VERSION ""

NS_ :

BS_:

BU_: WCM4 WCM3 WCM2 WCM VPM VLM VKM VICM VECM VDM VCU_RTOS_ETH VCU_ENTRY_ETH VCU_AGVM_ETH VCU UVM UPM TIM TEST_TOOL_1 TCP_ETH TCP TCM TCCM SRR_SRR_ETH SRR_SRR SRR_SLR_ETH SRR_SLR SRR_RR SRR_RF_ETH SRR_RF SRR_LR_CR SRR_LF_ETH SRR_LF SIB SDM SCL SBZA_R SBZA_L SBM SAM_RR SAM_RF SAM_LR SAM_LF SAM_BH SADS RadioLow_ETH RadioLow RSI_RTOS_ETH RSI RDCM PTM PLCM PFCM PDR_ETH PDR PCM PA ODS2 ODS NVM MTCM_R MTCM_L MSM_RR MSM_P MSM_LR MSM_D MSB2 MSB1 MRCM_R MRCM_L MFC LRR_RR_ETH LRR_LR_ETH LRR_CF_ETH LRR LRL_CF_ETH LIB_48V LIB1 IPC_INT IPC_GP IPC ICS_Info ICCM HVAC_FP_R HVAC_FP_F HUD_CAN HDLM FPI_RTOS_ETH FPI FOPM FCM_LC FCM EPSb EPS_1 EPSRAb EPSRAa EPS EOCM_HC_Superset EOCM_HCP2 EOCM ELM ECP_X1 ECP_S2 ECP_S ECP_MC ECP_H3 ECP_H2 ECP_H1 ECP_E ECM EBCM DMS DEFC DCM CSM_ETH CSM_AV CSM CGM_OTA_ETH CGM BSM_MH BSM_HEV BSM BCM ARS ARB APA AOS AMP ALC AHS AHL_AFL ADIMb ADIMa ACP2_MCU

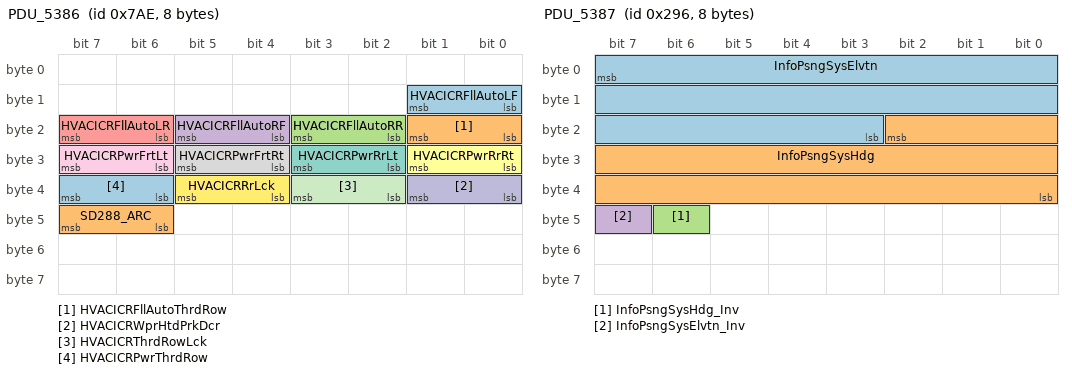
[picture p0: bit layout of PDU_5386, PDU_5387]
BO_ 1966 PDU_5386: 8 VCU
 SG_ HVACICRFllAutoLF : 9|2@0+ (1,0) [0|2] "" Vector__XXX
 SG_ HVACICRFllAutoThrdRow : 17|2@0+ (1,0) [0|2] "" Vector__XXX
 SG_ HVACICRFllAutoRR : 19|2@0+ (1,0) [0|2] "" Vector__XXX
 SG_ HVACICRFllAutoRF : 21|2@0+ (1,0) [0|2] "" Vector__XXX
 SG_ HVACICRFllAutoLR : 23|2@0+ (1,0) [0|2] "" Vector__XXX
 SG_ HVACICRPwrRrRt : 25|2@0+ (1,0) [0|2] "" Vector__XXX
 SG_ HVACICRPwrRrLt : 27|2@0+ (1,0) [0|2] "" Vector__XXX
 SG_ HVACICRPwrFrtRt : 29|2@0+ (1,0) [0|2] "" Vector__XXX
 SG_ HVACICRPwrFrtLt : 31|2@0+ (1,0) [0|2] "" Vector__XXX
 SG_ HVACICRWprHtdPrkDcr : 33|2@0+ (1,0) [0|2] "" Vector__XXX
 SG_ HVACICRThrdRowLck : 35|2@0+ (1,0) [0|2] "" Vector__XXX
 SG_ HVACICRRrLck : 37|2@0+ (1,0) [0|2] "" Vector__XXX
 SG_ HVACICRPwrThrdRow : 39|2@0+ (1,0) [0|2] "" Vector__XXX
 SG_ SD288_ARC : 47|2@0+ (1,0) [0|3] "" Vector__XXX

BO_ 662 PDU_5387: 8 VCU
 SG_ InfoPsngSysElvtn : 7|21@0+ (1,-100000) [-100000|1.99715e+006] "cm" Vector__XXX
 SG_ InfoPsngSysHdg : 18|19@0+ (0.001,0) [0|524.287] "deg" Vector__XXX
 SG_ InfoPsngSysHdg_Inv : 46|1@0+ (1,0) [0|1] "" Vector__XXX
 SG_ InfoPsngSysElvtn_Inv : 47|1@0+ (1,0) [0|1] "" Vector__XXX

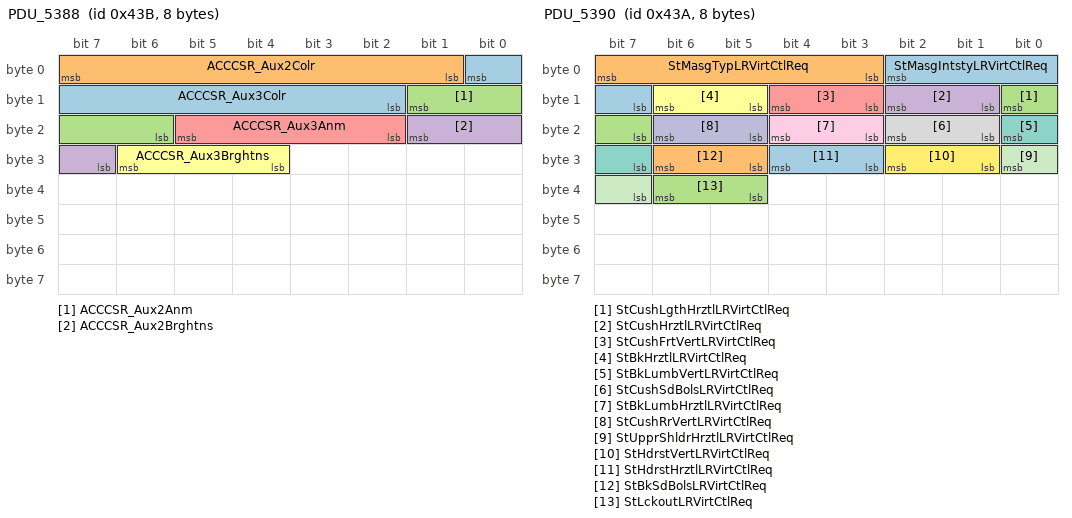
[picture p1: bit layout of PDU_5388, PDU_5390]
BO_ 1083 PDU_5388: 8 VCU
 SG_ ACCCSR_Aux3Colr : 0|7@0+ (1,0) [0|127] "" Vector__XXX
 SG_ ACCCSR_Aux2Colr : 7|7@0+ (1,0) [0|127] "" Vector__XXX
 SG_ ACCCSR_Aux2Anm : 9|4@0+ (1,0) [0|15] "" Vector__XXX
 SG_ ACCCSR_Aux2Brghtns : 17|3@0+ (1,0) [0|4] "" Vector__XXX
 SG_ ACCCSR_Aux3Anm : 21|4@0+ (1,0) [0|15] "" Vector__XXX
 SG_ ACCCSR_Aux3Brghtns : 30|3@0+ (1,0) [0|4] "" Vector__XXX

BO_ 1965 PDU_5389: 8 VCU
 SG_ StMasgTypLFVirtCtlReq : 1|5@0+ (1,0) [0|16] "" Vector__XXX
 SG_ StMemLFVirtCtlReq : 7|6@0+ (1,0) [0|33] "" Vector__XXX
 SG_ StBkHrztlLFCtlFrmFrtVirtCtlReq : 8|2@0+ (1,0) [0|2] "" Vector__XXX
 SG_ StMasgIntstyLFVirtCtlReq : 12|4@0+ (1,0) [0|8] "" Vector__XXX
 SG_ StBkLumbHrztlLFVirtCtlReq : 16|2@0+ (1,0) [0|2] "" Vector__XXX
 SG_ StCushHrztlLFCtlFrmFrtVirtCtlRq : 18|2@0+ (1,0) [0|2] "" Vector__XXX
 SG_ StCushFrtVertLFVirtCtlReq : 20|2@0+ (1,0) [0|2] "" Vector__XXX
 SG_ StBkHrztlLFCtlFrmRrVirtCtlReq : 22|2@0+ (1,0) [0|2] "" Vector__XXX
 SG_ StBkLumbVertLFVirtCtlReq : 24|2@0+ (1,0) [0|2] "" Vector__XXX
 SG_ StCushRrVertLFVirtCtlReq : 26|2@0+ (1,0) [0|2] "" Vector__XXX
 SG_ StCushLgthHrztlLFVirtCtlReq : 28|2@0+ (1,0) [0|2] "" Vector__XXX
 SG_ StCushHrztlLFCtlFrmRrVirtCtlReq : 30|2@0+ (1,0) [0|2] "" Vector__XXX
 SG_ StHdrstVertLFVirtCtlReq : 32|2@0+ (1,0) [0|2] "" Vector__XXX
 SG_ StHdrstHrztlLFVirtCtlReq : 34|2@0+ (1,0) [0|2] "" Vector__XXX
 SG_ StBkSdBolsLFVirtCtlReq : 36|2@0+ (1,0) [0|2] "" Vector__XXX
 SG_ StCushSdBolsLFVirtCtlReq : 38|2@0+ (1,0) [0|2] "" Vector__XXX
 SG_ StUpprShldrHrztlLFVirtCtlReq : 46|2@0+ (1,0) [0|2] "" Vector__XXX

BO_ 1082 PDU_5390: 8 VCU
 SG_ StMasgIntstyLRVirtCtlReq : 2|4@0+ (1,0) [0|8] "" Vector__XXX
 SG_ StMasgTypLRVirtCtlReq : 7|5@0+ (1,0) [0|16] "" Vector__XXX
 SG_ StCushLgthHrztlLRVirtCtlReq : 8|2@0+ (1,0) [0|2] "" Vector__XXX
 SG_ StCushHrztlLRVirtCtlReq : 10|2@0+ (1,0) [0|2] "" Vector__XXX
 SG_ StCushFrtVertLRVirtCtlReq : 12|2@0+ (1,0) [0|2] "" Vector__XXX
 SG_ StBkHrztlLRVirtCtlReq : 14|2@0+ (1,0) [0|2] "" Vector__XXX
 SG_ StBkLumbVertLRVirtCtlReq : 16|2@0+ (1,0) [0|2] "" Vector__XXX
 SG_ StCushSdBolsLRVirtCtlReq : 18|2@0+ (1,0) [0|2] "" Vector__XXX
 SG_ StBkLumbHrztlLRVirtCtlReq : 20|2@0+ (1,0) [0|2] "" Vector__XXX
 SG_ StCushRrVertLRVirtCtlReq : 22|2@0+ (1,0) [0|2] "" Vector__XXX
 SG_ StUpprShldrHrztlLRVirtCtlReq : 24|2@0+ (1,0) [0|2] "" Vector__XXX
 SG_ StHdrstVertLRVirtCtlReq : 26|2@0+ (1,0) [0|2] "" Vector__XXX
 SG_ StHdrstHrztlLRVirtCtlReq : 28|2@0+ (1,0) [0|2] "" Vector__XXX
 SG_ StBkSdBolsLRVirtCtlReq : 30|2@0+ (1,0) [0|2] "" Vector__XXX
 SG_ StLckoutLRVirtCtlReq : 38|2@0+ (1,0) [0|2] "" Vector__XXX

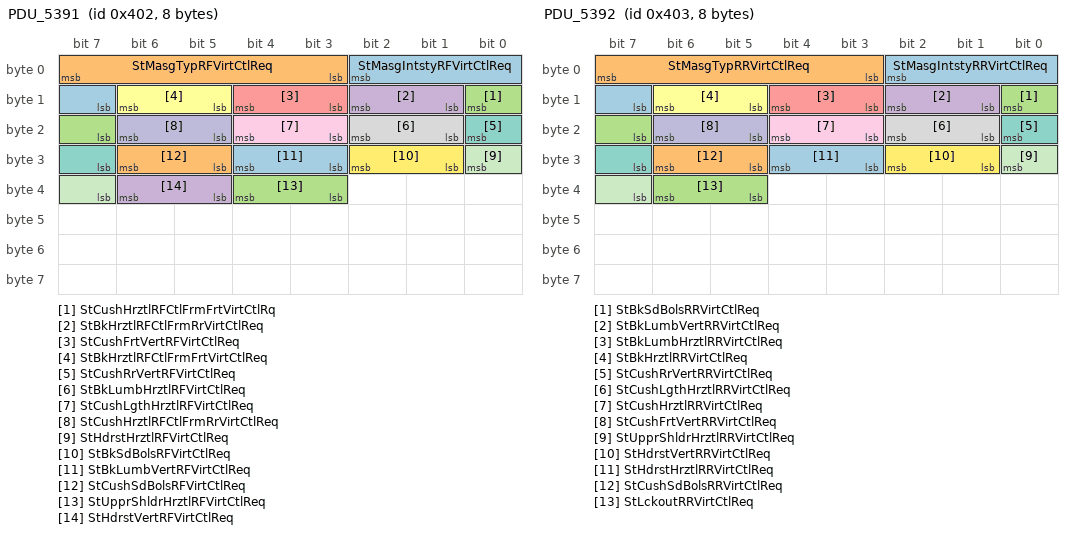
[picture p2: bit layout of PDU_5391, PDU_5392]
BO_ 1026 PDU_5391: 8 VCU
 SG_ StMasgIntstyRFVirtCtlReq : 2|4@0+ (1,0) [0|8] "" Vector__XXX
 SG_ StMasgTypRFVirtCtlReq : 7|5@0+ (1,0) [0|16] "" Vector__XXX
 SG_ StCushHrztlRFCtlFrmFrtVirtCtlRq : 8|2@0+ (1,0) [0|2] "" Vector__XXX
 SG_ StBkHrztlRFCtlFrmRrVirtCtlReq : 10|2@0+ (1,0) [0|2] "" Vector__XXX
 SG_ StCushFrtVertRFVirtCtlReq : 12|2@0+ (1,0) [0|2] "" Vector__XXX
 SG_ StBkHrztlRFCtlFrmFrtVirtCtlReq : 14|2@0+ (1,0) [0|2] "" Vector__XXX
 SG_ StCushRrVertRFVirtCtlReq : 16|2@0+ (1,0) [0|2] "" Vector__XXX
 SG_ StBkLumbHrztlRFVirtCtlReq : 18|2@0+ (1,0) [0|2] "" Vector__XXX
 SG_ StCushLgthHrztlRFVirtCtlReq : 20|2@0+ (1,0) [0|2] "" Vector__XXX
 SG_ StCushHrztlRFCtlFrmRrVirtCtlReq : 22|2@0+ (1,0) [0|2] "" Vector__XXX
 SG_ StHdrstHrztlRFVirtCtlReq : 24|2@0+ (1,0) [0|2] "" Vector__XXX
 SG_ StBkSdBolsRFVirtCtlReq : 26|2@0+ (1,0) [0|2] "" Vector__XXX
 SG_ StBkLumbVertRFVirtCtlReq : 28|2@0+ (1,0) [0|2] "" Vector__XXX
 SG_ StCushSdBolsRFVirtCtlReq : 30|2@0+ (1,0) [0|2] "" Vector__XXX
 SG_ StUpprShldrHrztlRFVirtCtlReq : 36|2@0+ (1,0) [0|2] "" Vector__XXX
 SG_ StHdrstVertRFVirtCtlReq : 38|2@0+ (1,0) [0|2] "" Vector__XXX

BO_ 1027 PDU_5392: 8 VCU
 SG_ StMasgIntstyRRVirtCtlReq : 2|4@0+ (1,0) [0|8] "" Vector__XXX
 SG_ StMasgTypRRVirtCtlReq : 7|5@0+ (1,0) [0|16] "" Vector__XXX
 SG_ StBkSdBolsRRVirtCtlReq : 8|2@0+ (1,0) [0|2] "" Vector__XXX
 SG_ StBkLumbVertRRVirtCtlReq : 10|2@0+ (1,0) [0|2] "" Vector__XXX
 SG_ StBkLumbHrztlRRVirtCtlReq : 12|2@0+ (1,0) [0|2] "" Vector__XXX
 SG_ StBkHrztlRRVirtCtlReq : 14|2@0+ (1,0) [0|2] "" Vector__XXX
 SG_ StCushRrVertRRVirtCtlReq : 16|2@0+ (1,0) [0|2] "" Vector__XXX
 SG_ StCushLgthHrztlRRVirtCtlReq : 18|2@0+ (1,0) [0|2] "" Vector__XXX
 SG_ StCushHrztlRRVirtCtlReq : 20|2@0+ (1,0) [0|2] "" Vector__XXX
 SG_ StCushFrtVertRRVirtCtlReq : 22|2@0+ (1,0) [0|2] "" Vector__XXX
 SG_ StUpprShldrHrztlRRVirtCtlReq : 24|2@0+ (1,0) [0|2] "" Vector__XXX
 SG_ StHdrstVertRRVirtCtlReq : 26|2@0+ (1,0) [0|2] "" Vector__XXX
 SG_ StHdrstHrztlRRVirtCtlReq : 28|2@0+ (1,0) [0|2] "" Vector__XXX
 SG_ StCushSdBolsRRVirtCtlReq : 30|2@0+ (1,0) [0|2] "" Vector__XXX
 SG_ StLckoutRRVirtCtlReq : 38|2@0+ (1,0) [0|2] "" Vector__XXX

BO_ 1085 PDU_5393: 8 VCU
 SG_ TrlrTirePresLFInrXferdSnsrID : 7|32@0+ (1,0) [0|4.29497e+009] "" Vector__XXX
 SG_ TrlrTirePresLRInrXferdSnsrID : 39|32@0+ (1,0) [0|4.29497e+009] "" Vector__XXX

BO_ 1982 PDU_5394: 8 VCU
 SG_ TrlrTirePresLtMdlInrXferdSnsrID : 7|32@0+ (1,0) [0|4.29497e+009] "" Vector__XXX
 SG_ TrlrTirePresRFInrXferdSnsrID : 39|32@0+ (1,0) [0|4.29497e+009] "" Vector__XXX

BO_ 1084 PDU_5395: 8 VCU
 SG_ TrlrTirePresRRInrXferdSnsrID : 7|32@0+ (1,0) [0|4.29497e+009] "" Vector__XXX
 SG_ TrlrTirePresRtMdlInrXferdSnsrID : 39|32@0+ (1,0) [0|4.29497e+009] "" Vector__XXX

BO_ 1983 PDU_5396: 8 VCU
 SG_ InfoUTCYr : 7|8@0+ (1,2000) [2000|2255] "year" Vector__XXX
 SG_ InfoUTCSec : 9|6@0+ (1,0) [0|63] "seconds" Vector__XXX
 SG_ InfoUTCMin : 15|6@0+ (1,0) [0|63] "minutes" Vector__XXX
 SG_ InfoUTCDay : 19|5@0+ (1,0) [0|31] "day" Vector__XXX
 SG_ InfoUTCMth : 25|4@0+ (1,0) [0|12] "" Vector__XXX
 SG_ InfoUTCHrs : 30|5@0+ (1,0) [0|31] "hour" Vector__XXX
 SG_ InfoUTCYr_Inv : 32|1@0+ (1,0) [0|1] "" Vector__XXX
 SG_ InfoUTCSec_Inv : 33|1@0+ (1,0) [0|1] "" Vector__XXX
 SG_ InfoUTCMth_Inv : 34|1@0+ (1,0) [0|1] "" Vector__XXX
 SG_ InfoUTCMin_Inv : 35|1@0+ (1,0) [0|1] "" Vector__XXX
 SG_ InfoUTCHrs_Inv : 36|1@0+ (1,0) [0|1] "" Vector__XXX
 SG_ InfoUTCDay_Inv : 37|1@0+ (1,0) [0|1] "" Vector__XXX
 SG_ OffbrdEngyXferMinSOCReq : 45|7@0+ (1,0) [0|127] "%" Vector__XXX
 SG_ DrvrSeltdOtltOffPwrMdVirCtlRq : 47|2@0+ (1,0) [0|2] "" Vector__XXX
 SG_ OtltsOffPwrModeTmrReqVal : 51|11@0+ (1,0) [0|2047] "min" Vector__XXX
 SG_ OtltsOffPwrModeTmrOpCstSetReq : 53|2@0+ (1,0) [0|2] "" Vector__XXX
 SG_ OffbrdEngyXferMinSOCReq_DuD : 54|1@0+ (1,0) [0|1] "" Vector__XXX
 SG_ OtltsOffPwrModeTmrReqVal_DuD : 56|1@0+ (1,0) [0|1] "" Vector__XXX

BO_ 1979 PDU_5397: 8 VCU
 SG_ VirtCtlGlsRfTntLvlPnl3Req : 1|3@0+ (1,0) [0|7] "" Vector__XXX
 SG_ VirtCtlGlsRfTntLvlPnl2Req : 4|3@0+ (1,0) [0|7] "" Vector__XXX
 SG_ VirtCtlGlsRfTntLvlPnl1Req : 7|3@0+ (1,0) [0|7] "" Vector__XXX
 SG_ VirtCtlGlsRfTntLvlPnl6Req : 8|3@0+ (1,0) [0|7] "" Vector__XXX
 SG_ VirtCtlGlsRfTntLvlPnl5Req : 11|3@0+ (1,0) [0|7] "" Vector__XXX
 SG_ VirtCtlGlsRfTntLvlPnl4Req : 14|3@0+ (1,0) [0|7] "" Vector__XXX
 SG_ VirtCtlGlsRfTntLvlPnl8Req : 18|3@0+ (1,0) [0|7] "" Vector__XXX
 SG_ VirtCtlGlsRfTntLvlPnl7Req : 21|3@0+ (1,0) [0|7] "" Vector__XXX
 SG_ VirtCtlPwrShdBkGlsReq : 24|2@0+ (1,0) [0|2] "" Vector__XXX
 SG_ VirtCtlGlsRfTntAutoSetReq : 26|2@0+ (1,0) [0|2] "" Vector__XXX
 SG_ VirtCtlGlsRfPwrShdPrvcyReqd : 28|2@0+ (1,0) [0|2] "" Vector__XXX
 SG_ VirtCtlGlsRfTntLvlSldrReq : 31|3@0+ (1,0) [0|6] "" Vector__XXX
 SG_ VirtCtlGlsRfTntReqd : 32|1@0+ (1,0) [0|1] "" Vector__XXX
 SG_ VirtCtlGlsRfDrkReqd : 33|1@0+ (1,0) [0|1] "" Vector__XXX
 SG_ VirtCtlGlsRfClrReqd : 34|1@0+ (1,0) [0|1] "" Vector__XXX
 SG_ VirtCtlPwrShdRRReq : 36|2@0+ (1,0) [0|2] "" Vector__XXX
 SG_ VirtCtlPwrShdLRReq : 38|2@0+ (1,0) [0|2] "" Vector__XXX
 SG_ OtltsOffPwrModeTmrAddTmReq : 46|1@0+ (1,0) [0|1] "" Vector__XXX
 SG_ OtltsOffPwrMdSysStopReq : 47|1@0+ (1,0) [0|1] "" Vector__XXX

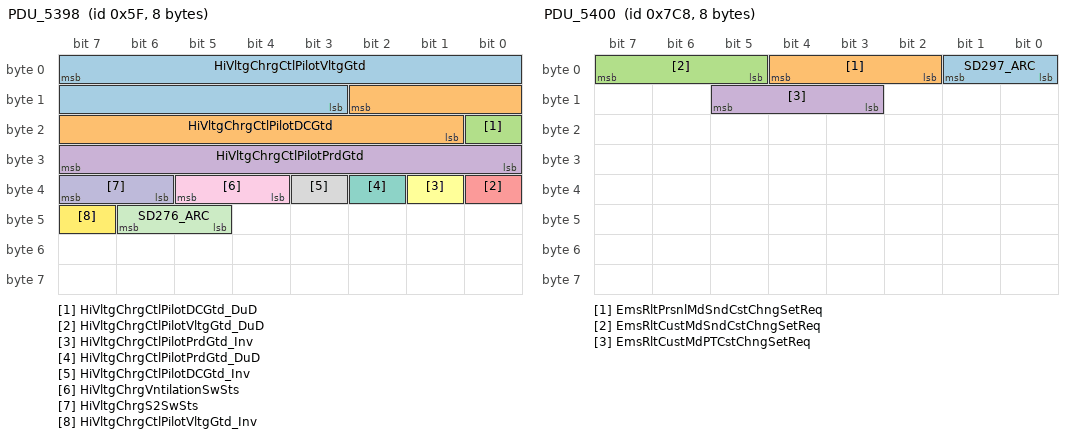
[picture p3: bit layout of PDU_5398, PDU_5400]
BO_ 95 PDU_5398: 8 PLCM
 SG_ HiVltgChrgCtlPilotVltgGtd : 7|13@0- (0.005,0) [-20.48|20.475] "V" VCU
 SG_ HiVltgChrgCtlPilotDCGtd : 10|10@0+ (0.1,0) [0|102.3] "%" VCU
 SG_ HiVltgChrgCtlPilotDCGtd_DuD : 16|1@0+ (1,0) [0|1] "" VCU
 SG_ HiVltgChrgCtlPilotPrdGtd : 31|8@0+ (0.01,0) [0|2.55] "ms" VCU
 SG_ HiVltgChrgCtlPilotVltgGtd_DuD : 32|1@0+ (1,0) [0|1] "" VCU
 SG_ HiVltgChrgCtlPilotPrdGtd_Inv : 33|1@0+ (1,0) [0|1] "" VCU
 SG_ HiVltgChrgCtlPilotPrdGtd_DuD : 34|1@0+ (1,0) [0|1] "" VCU
 SG_ HiVltgChrgCtlPilotDCGtd_Inv : 35|1@0+ (1,0) [0|1] "" VCU
 SG_ HiVltgChrgVntilationSwSts : 37|2@0+ (1,0) [0|3] "" VCU
 SG_ HiVltgChrgS2SwSts : 39|2@0+ (1,0) [0|3] "" VCU
 SG_ SD276_ARC : 46|2@0+ (1,0) [0|3] "" VCU
 SG_ HiVltgChrgCtlPilotVltgGtd_Inv : 47|1@0+ (1,0) [0|1] "" VCU

BO_ 1936 PDU_5399: 8 PLCM
 SG_ ChrgStnCommActvReqd : 7|1@0+ (1,0) [0|1] "" Vector__XXX

BO_ 1992 PDU_5400: 8 VCU
 SG_ SD297_ARC : 1|2@0+ (1,0) [0|3] "" Vector__XXX
 SG_ EmsRltPrsnlMdSndCstChngSetReq : 4|3@0+ (1,0) [0|7] "" Vector__XXX
 SG_ EmsRltCustMdSndCstChngSetReq : 7|3@0+ (1,0) [0|7] "" Vector__XXX
 SG_ EmsRltCustMdPTCstChngSetReq : 13|3@0+ (1,0) [0|7] "" Vector__XXX

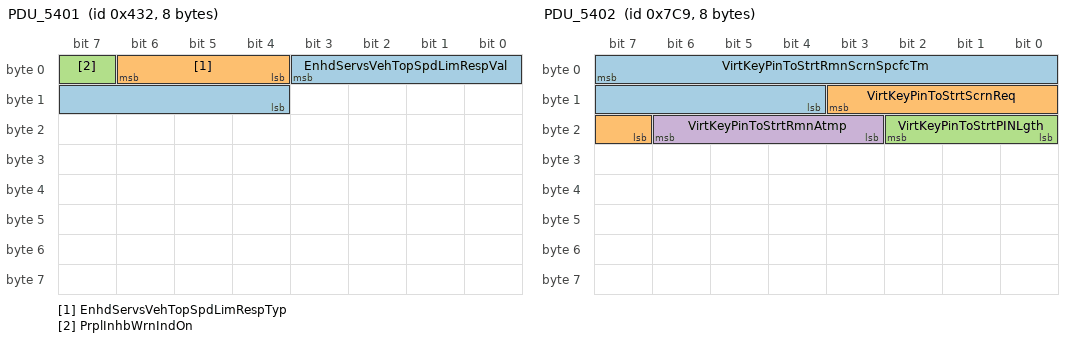
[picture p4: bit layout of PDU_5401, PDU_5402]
BO_ 1074 PDU_5401: 8 CGM
 SG_ EnhdServsVehTopSpdLimRespVal : 3|8@0+ (2,0) [0|510] "kph" TCP
 SG_ EnhdServsVehTopSpdLimRespTyp : 6|3@0+ (1,0) [0|6] "" TCP
 SG_ PrplInhbWrnIndOn : 7|1@0+ (1,0) [0|1] "" IPC,IPC_INT,VCU

BO_ 1993 PDU_5402: 8 VKM
 SG_ VirtKeyPinToStrtRmnScrnSpcfcTm : 7|12@0+ (1,0) [0|4095] "sec" CSM,VCU
 SG_ VirtKeyPinToStrtScrnReq : 11|5@0+ (1,0) [0|9] "" CSM,VCU
 SG_ VirtKeyPinToStrtPINLgth : 18|3@0+ (1,0) [0|7] "" CSM,VCU
 SG_ VirtKeyPinToStrtRmnAtmp : 22|4@0+ (1,0) [0|15] "" CSM,VCU

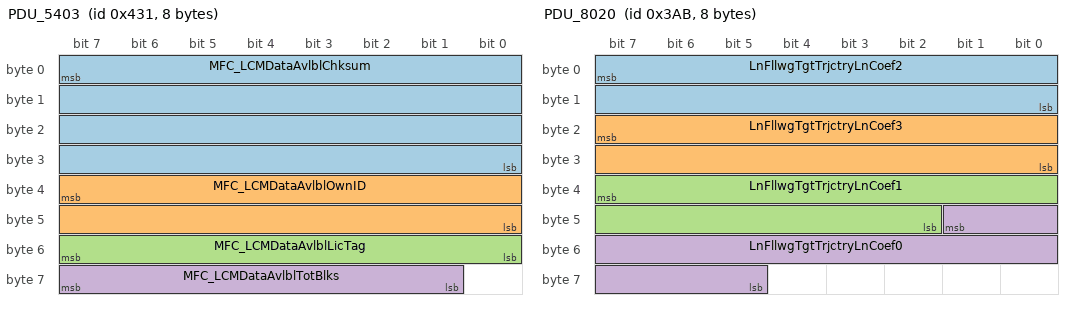
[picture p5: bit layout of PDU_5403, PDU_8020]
BO_ 1073 PDU_5403: 8 MFC
 SG_ MFC_LCMDataAvlblChksum : 7|32@0+ (1,0) [0|4.29497e+009] "" VCU
 SG_ MFC_LCMDataAvlblOwnID : 39|16@0+ (1,0) [0|65535] "" VCU
 SG_ MFC_LCMDataAvlblLicTag : 55|8@0+ (1,0) [0|255] "" VCU
 SG_ MFC_LCMDataAvlblTotBlks : 63|7@0+ (1,0) [0|127] "" VCU

BO_ 939 PDU_8020: 8 CGM
 SG_ LnFllwgTgtTrjctryLnCoef2 : 7|16@0- (9.77e-07,0) [-0.0320143|0.0320134] "1/m" TCP
 SG_ LnFllwgTgtTrjctryLnCoef3 : 23|16@0- (3.73e-09,0) [-0.000122225|0.000122221] "1/m^2" TCP
 SG_ LnFllwgTgtTrjctryLnCoef1 : 39|14@0- (0.00125,0) [-10.24|10.2388] "m/m" TCP
 SG_ LnFllwgTgtTrjctryLnCoef0 : 41|13@0- (0.00309,0) [-12.6566|12.6535] "m" TCP

BO_ 1947 PDU_8061: 8 CGM
 SG_ TrfcSgnMemCstSetAval : 0|1@0+ (1,0) [0|1] "" CSM,CSM_AV,VCU
 SG_ TrfcSgnMemCstAvlFlg7 : 1|1@0+ (1,0) [0|1] "" CSM,CSM_AV,VCU
 SG_ TrfcSgnMemCstAvlFlg6 : 2|1@0+ (1,0) [0|1] "" CSM,CSM_AV,VCU
 SG_ TrfcSgnMemCstAvlFlg5 : 3|1@0+ (1,0) [0|1] "" CSM,CSM_AV,VCU
 SG_ TrfcSgnMemCstAvlFlg4 : 4|1@0+ (1,0) [0|1] "" CSM,CSM_AV,VCU
 SG_ TrfcSgnMemCstAvlFlg3 : 5|1@0+ (1,0) [0|1] "" CSM,CSM_AV,VCU
 SG_ TrfcSgnMemCstAvlFlg2 : 6|1@0+ (1,0) [0|1] "" CSM,CSM_AV,VCU
 SG_ TrfcSgnMemCstAvlFlg1 : 7|1@0+ (1,0) [0|1] "" CSM,CSM_AV,VCU
 SG_ TrfcSgnMemOvrspdChmCstAvlFlg7 : 8|1@0+ (1,0) [0|1] "" CSM,CSM_AV,VCU
 SG_ TrfcSgnMemOvrspdChmCstAvlFlg6 : 9|1@0+ (1,0) [0|1] "" CSM,CSM_AV,VCU
 SG_ TrfcSgnMemOvrspdChmCstAvlFlg5 : 10|1@0+ (1,0) [0|1] "" CSM,CSM_AV,VCU
 SG_ TrfcSgnMemOvrspdChmCstAvlFlg4 : 11|1@0+ (1,0) [0|1] "" CSM,CSM_AV,VCU
 SG_ TrfcSgnMemOvrspdChmCstAvlFlg3 : 12|1@0+ (1,0) [0|1] "" CSM,CSM_AV,VCU
 SG_ TrfcSgnMemOvrspdChmCstAvlFlg2 : 13|1@0+ (1,0) [0|1] "" CSM,CSM_AV,VCU
 SG_ TrfcSgnMemOvrspdChmCstAvlFlg1 : 14|1@0+ (1,0) [0|1] "" CSM,CSM_AV,VCU
 SG_ TrfcSgnMemOfstEnbld : 15|1@0+ (1,0) [0|1] "" IPC,IPC_INT,VCU
 SG_ TrfcSgnMemSpdLmChgChmCstAvlFlg7 : 16|1@0+ (1,0) [0|1] "" CSM,CSM_AV,VCU
 SG_ TrfcSgnMemSpdLmChgChmCstAvlFlg6 : 17|1@0+ (1,0) [0|1] "" CSM,CSM_AV,VCU
 SG_ TrfcSgnMemSpdLmChgChmCstAvlFlg5 : 18|1@0+ (1,0) [0|1] "" CSM,CSM_AV,VCU
 SG_ TrfcSgnMemSpdLmChgChmCstAvlFlg4 : 19|1@0+ (1,0) [0|1] "" CSM,CSM_AV,VCU
 SG_ TrfcSgnMemSpdLmChgChmCstAvlFlg3 : 20|1@0+ (1,0) [0|1] "" CSM,CSM_AV,VCU
 SG_ TrfcSgnMemSpdLmChgChmCstAvlFlg2 : 21|1@0+ (1,0) [0|1] "" CSM,CSM_AV,VCU
 SG_ TrfcSgnMemSpdLmChgChmCstAvlFlg1 : 22|1@0+ (1,0) [0|1] "" CSM,CSM_AV,VCU
 SG_ TrfcSgnMemOvrspdChmCstSetAval : 23|1@0+ (1,0) [0|1] "" CSM,CSM_AV,VCU
 SG_ TrfcSgnMemSpdLmChgChmCstSetAval : 31|1@0+ (1,0) [0|1] "" CSM,CSM_AV,VCU

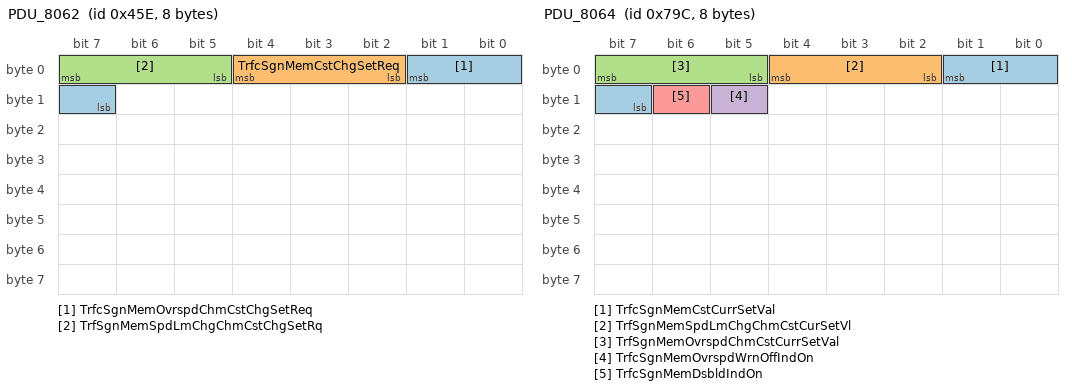
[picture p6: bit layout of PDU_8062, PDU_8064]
BO_ 1118 PDU_8062: 8 CSM
 SG_ TrfcSgnMemOvrspdChmCstChgSetReq : 1|3@0+ (1,0) [0|2] "" Vector__XXX
 SG_ TrfcSgnMemCstChgSetReq : 4|3@0+ (1,0) [0|2] "" Vector__XXX
 SG_ TrfSgnMemSpdLmChgChmCstChgSetRq : 7|3@0+ (1,0) [0|2] "" Vector__XXX

BO_ 1119 PDU_8063: 8 CGM
 SG_ TrfcSgnMemSgnChgChmEvntStat : 5|2@0+ (1,0) [0|2] "" IPC,IPC_INT,VCU
 SG_ TrfcSgnMemOvrspdChmEvntStat : 7|2@0+ (1,0) [0|2] "" IPC,IPC_INT,VCU

BO_ 1948 PDU_8064: 8 CGM
 SG_ TrfcSgnMemCstCurrSetVal : 1|3@0+ (1,0) [0|2] "" CSM,CSM_AV,VCU
 SG_ TrfSgnMemSpdLmChgChmCstCurSetVl : 4|3@0+ (1,0) [0|2] "" CSM,CSM_AV,VCU
 SG_ TrfSgnMemOvrspdChmCstCurrSetVal : 7|3@0+ (1,0) [0|2] "" CSM,CSM_AV,VCU
 SG_ TrfcSgnMemOvrspdWrnOffIndOn : 13|1@0+ (1,0) [0|1] "" IPC,IPC_INT,VCU
 SG_ TrfcSgnMemDsbldIndOn : 14|1@0+ (1,0) [0|1] "" IPC,IPC_INT,VCU

BO_ 1192 PDU_9036: 8 CGM
 SG_ AutDrvLckCstAvlFlg1 : 0|1@0+ (1,0) [0|1] "" RadioLow,CSM,CSM_AV,VCU
 SG_ AirQltySnsCstAvlFlg7 : 1|1@0+ (1,0) [0|1] "" RadioLow,CSM,CSM_AV,VCU
 SG_ AirQltySnsCstAvlFlg6 : 2|1@0+ (1,0) [0|1] "" RadioLow,CSM,CSM_AV,VCU
 SG_ AirQltySnsCstAvlFlg5 : 3|1@0+ (1,0) [0|1] "" RadioLow,CSM,CSM_AV,VCU
 SG_ AirQltySnsCstAvlFlg4 : 4|1@0+ (1,0) [0|1] "" RadioLow,CSM,CSM_AV,VCU
 SG_ AirQltySnsCstAvlFlg3 : 5|1@0+ (1,0) [0|1] "" RadioLow,CSM,CSM_AV,VCU
 SG_ AirQltySnsCstAvlFlg2 : 6|1@0+ (1,0) [0|1] "" RadioLow,CSM,CSM_AV,VCU
 SG_ AirQltySnsCstAvlFlg1 : 7|1@0+ (1,0) [0|1] "" RadioLow,CSM,CSM_AV,VCU
 SG_ AutMirFldCstAvlFlg2 : 8|1@0+ (1,0) [0|1] "" RadioLow,CSM,CSM_AV,VCU
 SG_ AutMirFldCstAvlFlg1 : 9|1@0+ (1,0) [0|1] "" RadioLow,CSM,CSM_AV,VCU
 SG_ AutDrvLckCstAvlFlg7 : 10|1@0+ (1,0) [0|1] "" RadioLow,CSM,CSM_AV,VCU
 SG_ AutDrvLckCstAvlFlg6 : 11|1@0+ (1,0) [0|1] "" RadioLow,CSM,CSM_AV,VCU
 SG_ AutDrvLckCstAvlFlg5 : 12|1@0+ (1,0) [0|1] "" RadioLow,CSM,CSM_AV,VCU
 SG_ AutDrvLckCstAvlFlg4 : 13|1@0+ (1,0) [0|1] "" RadioLow,CSM,CSM_AV,VCU
 SG_ AutDrvLckCstAvlFlg3 : 14|1@0+ (1,0) [0|1] "" RadioLow,CSM,CSM_AV,VCU
 SG_ AutDrvLckCstAvlFlg2 : 15|1@0+ (1,0) [0|1] "" RadioLow,CSM,CSM_AV,VCU
 SG_ AutoAirDstCstAvlFlg3 : 16|1@0+ (1,0) [0|1] "" RadioLow,TCP,CSM,CSM_AV,VCU
 SG_ AutoAirDstCstAvlFlg2 : 17|1@0+ (1,0) [0|1] "" RadioLow,TCP,CSM,CSM_AV,VCU
 SG_ AutoAirDstCstAvlFlg1 : 18|1@0+ (1,0) [0|1] "" RadioLow,TCP,CSM,CSM_AV,VCU
 SG_ AutMirFldCstAvlFlg7 : 19|1@0+ (1,0) [0|1] "" RadioLow,CSM,CSM_AV,VCU
 SG_ AutMirFldCstAvlFlg6 : 20|1@0+ (1,0) [0|1] "" RadioLow,CSM,CSM_AV,VCU
 SG_ AutMirFldCstAvlFlg5 : 21|1@0+ (1,0) [0|1] "" RadioLow,CSM,CSM_AV,VCU
 SG_ AutMirFldCstAvlFlg4 : 22|1@0+ (1,0) [0|1] "" RadioLow,CSM,CSM_AV,VCU
 SG_ AutMirFldCstAvlFlg3 : 23|1@0+ (1,0) [0|1] "" RadioLow,CSM,CSM_AV,VCU
 SG_ AutoCoolStCstAvlFlg4 : 24|1@0+ (1,0) [0|1] "" RadioLow,CSM,CSM_AV,VCU
 SG_ AutoCoolStCstAvlFlg3 : 25|1@0+ (1,0) [0|1] "" RadioLow,CSM,CSM_AV,VCU
 SG_ AutoCoolStCstAvlFlg2 : 26|1@0+ (1,0) [0|1] "" RadioLow,CSM,CSM_AV,VCU
 SG_ AutoCoolStCstAvlFlg1 : 27|1@0+ (1,0) [0|1] "" RadioLow,CSM,CSM_AV,VCU
 SG_ AutoAirDstCstAvlFlg7 : 28|1@0+ (1,0) [0|1] "" RadioLow,TCP,CSM,CSM_AV,VCU
 SG_ AutoAirDstCstAvlFlg6 : 29|1@0+ (1,0) [0|1] "" RadioLow,TCP,CSM,CSM_AV,VCU
 SG_ AutoAirDstCstAvlFlg5 : 30|1@0+ (1,0) [0|1] "" RadioLow,TCP,CSM,CSM_AV,VCU
 SG_ AutoAirDstCstAvlFlg4 : 31|1@0+ (1,0) [0|1] "" RadioLow,TCP,CSM,CSM_AV,VCU
 SG_ AutoDfgCstAvlFlg5 : 32|1@0+ (1,0) [0|1] "" RadioLow,CSM,CSM_AV,VCU
 SG_ AutoDfgCstAvlFlg4 : 33|1@0+ (1,0) [0|1] "" RadioLow,CSM,CSM_AV,VCU
 SG_ AutoDfgCstAvlFlg3 : 34|1@0+ (1,0) [0|1] "" RadioLow,CSM,CSM_AV,VCU
 SG_ AutoDfgCstAvlFlg2 : 35|1@0+ (1,0) [0|1] "" RadioLow,CSM,CSM_AV,VCU
 SG_ AutoDfgCstAvlFlg1 : 36|1@0+ (1,0) [0|1] "" RadioLow,CSM,CSM_AV,VCU
 SG_ AutoCoolStCstAvlFlg7 : 37|1@0+ (1,0) [0|1] "" RadioLow,CSM,CSM_AV,VCU
 SG_ AutoCoolStCstAvlFlg6 : 38|1@0+ (1,0) [0|1] "" RadioLow,CSM,CSM_AV,VCU
 SG_ AutoCoolStCstAvlFlg5 : 39|1@0+ (1,0) [0|1] "" RadioLow,CSM,CSM_AV,VCU
 SG_ AutoFanCstAvlFlg6 : 40|1@0+ (1,0) [0|1] "" RadioLow,CSM,CSM_AV,VCU
 SG_ AutoFanCstAvlFlg5 : 41|1@0+ (1,0) [0|1] "" RadioLow,CSM,CSM_AV,VCU
 SG_ AutoFanCstAvlFlg4 : 42|1@0+ (1,0) [0|1] "" RadioLow,CSM,CSM_AV,VCU
 SG_ AutoFanCstAvlFlg3 : 43|1@0+ (1,0) [0|1] "" RadioLow,CSM,CSM_AV,VCU
 SG_ AutoFanCstAvlFlg2 : 44|1@0+ (1,0) [0|1] "" RadioLow,CSM,CSM_AV,VCU
 SG_ AutoFanCstAvlFlg1 : 45|1@0+ (1,0) [0|1] "" RadioLow,CSM,CSM_AV,VCU
 SG_ AutoDfgCstAvlFlg7 : 46|1@0+ (1,0) [0|1] "" RadioLow,CSM,CSM_AV,VCU
 SG_ AutoDfgCstAvlFlg6 : 47|1@0+ (1,0) [0|1] "" RadioLow,CSM,CSM_AV,VCU
 SG_ AutoHtdStCstAvlFlg7 : 48|1@0+ (1,0) [0|1] "" RadioLow,CSM,CSM_AV,VCU
 SG_ AutoHtdStCstAvlFlg6 : 49|1@0+ (1,0) [0|1] "" RadioLow,CSM,CSM_AV,VCU
 SG_ AutoHtdStCstAvlFlg5 : 50|1@0+ (1,0) [0|1] "" RadioLow,CSM,CSM_AV,VCU
 SG_ AutoHtdStCstAvlFlg4 : 51|1@0+ (1,0) [0|1] "" RadioLow,CSM,CSM_AV,VCU
 SG_ AutoHtdStCstAvlFlg3 : 52|1@0+ (1,0) [0|1] "" RadioLow,CSM,CSM_AV,VCU
 SG_ AutoHtdStCstAvlFlg2 : 53|1@0+ (1,0) [0|1] "" RadioLow,CSM,CSM_AV,VCU
 SG_ AutoHtdStCstAvlFlg1 : 54|1@0+ (1,0) [0|1] "" RadioLow,CSM,CSM_AV,VCU
 SG_ AutoFanCstAvlFlg7 : 55|1@0+ (1,0) [0|1] "" RadioLow,CSM,CSM_AV,VCU
 SG_ Aux1AmbtColrCtlCstAvlFlg87 : 56|1@0+ (1,0) [0|1] "" VCU
 SG_ AutoRrWpCstAvlFlg7 : 57|1@0+ (1,0) [0|1] "" RadioLow,CSM,CSM_AV,VCU
 SG_ AutoRrWpCstAvlFlg6 : 58|1@0+ (1,0) [0|1] "" RadioLow,CSM,CSM_AV,VCU
 SG_ AutoRrWpCstAvlFlg5 : 59|1@0+ (1,0) [0|1] "" RadioLow,CSM,CSM_AV,VCU
 SG_ AutoRrWpCstAvlFlg4 : 60|1@0+ (1,0) [0|1] "" RadioLow,CSM,CSM_AV,VCU
 SG_ AutoRrWpCstAvlFlg3 : 61|1@0+ (1,0) [0|1] "" RadioLow,CSM,CSM_AV,VCU
 SG_ AutoRrWpCstAvlFlg2 : 62|1@0+ (1,0) [0|1] "" RadioLow,CSM,CSM_AV,VCU
 SG_ AutoRrWpCstAvlFlg1 : 63|1@0+ (1,0) [0|1] "" RadioLow,CSM,CSM_AV,VCU

BO_ 1874 PDU_9037: 8 CGM
 SG_ Aux1AmbtAnmCtlCstAvlFlg1 : 0|1@0+ (1,0) [0|1] "" RadioLow,CSM,CSM_AV,VCU
 SG_ AutUnlckCstAvlFlg7 : 1|1@0+ (1,0) [0|1] "" RadioLow,CSM,CSM_AV,VCU
 SG_ AutUnlckCstAvlFlg6 : 2|1@0+ (1,0) [0|1] "" RadioLow,CSM,CSM_AV,VCU
 SG_ AutUnlckCstAvlFlg5 : 3|1@0+ (1,0) [0|1] "" RadioLow,CSM,CSM_AV,VCU
 SG_ AutUnlckCstAvlFlg4 : 4|1@0+ (1,0) [0|1] "" RadioLow,CSM,CSM_AV,VCU
 SG_ AutUnlckCstAvlFlg3 : 5|1@0+ (1,0) [0|1] "" RadioLow,CSM,CSM_AV,VCU
 SG_ AutUnlckCstAvlFlg2 : 6|1@0+ (1,0) [0|1] "" RadioLow,CSM,CSM_AV,VCU
 SG_ AutUnlckCstAvlFlg1 : 7|1@0+ (1,0) [0|1] "" RadioLow,CSM,CSM_AV,VCU
 SG_ Aux1AmbtAnmCtlCstAvlFlg3 : 8|1@0+ (1,0) [0|1] "" RadioLow,CSM,CSM_AV,VCU
 SG_ Aux1AmbtAnmCtlCstAvlFlg2 : 9|1@0+ (1,0) [0|1] "" RadioLow,CSM,CSM_AV,VCU
 SG_ Aux1AmbtAnmCtlCstAvlFlg15 : 10|1@0+ (1,0) [0|1] "" RadioLow,CSM,CSM_AV,VCU
 SG_ Aux1AmbtAnmCtlCstAvlFlg14 : 11|1@0+ (1,0) [0|1] "" RadioLow,CSM,CSM_AV,VCU
 SG_ Aux1AmbtAnmCtlCstAvlFlg13 : 12|1@0+ (1,0) [0|1] "" RadioLow,CSM,CSM_AV,VCU
 SG_ Aux1AmbtAnmCtlCstAvlFlg12 : 13|1@0+ (1,0) [0|1] "" RadioLow,CSM,CSM_AV,VCU
 SG_ Aux1AmbtAnmCtlCstAvlFlg11 : 14|1@0+ (1,0) [0|1] "" RadioLow,CSM,CSM_AV,VCU
 SG_ Aux1AmbtAnmCtlCstAvlFlg10 : 15|1@0+ (1,0) [0|1] "" RadioLow,CSM,CSM_AV,VCU
 SG_ Aux1AmbtBrghtnsCtlCstAvlFlg1 : 16|1@0+ (1,0) [0|1] "" RadioLow,CSM,CSM_AV,VCU
 SG_ Aux1AmbtAnmCtlCstSetAval : 17|1@0+ (1,0) [0|1] "" RadioLow,CSM,CSM_AV,VCU
 SG_ Aux1AmbtAnmCtlCstAvlFlg9 : 18|1@0+ (1,0) [0|1] "" RadioLow,CSM,CSM_AV,VCU
 SG_ Aux1AmbtAnmCtlCstAvlFlg8 : 19|1@0+ (1,0) [0|1] "" RadioLow,CSM,CSM_AV,VCU
 SG_ Aux1AmbtAnmCtlCstAvlFlg7 : 20|1@0+ (1,0) [0|1] "" RadioLow,CSM,CSM_AV,VCU
 SG_ Aux1AmbtAnmCtlCstAvlFlg6 : 21|1@0+ (1,0) [0|1] "" RadioLow,CSM,CSM_AV,VCU
 SG_ Aux1AmbtAnmCtlCstAvlFlg5 : 22|1@0+ (1,0) [0|1] "" RadioLow,CSM,CSM_AV,VCU
 SG_ Aux1AmbtAnmCtlCstAvlFlg4 : 23|1@0+ (1,0) [0|1] "" RadioLow,CSM,CSM_AV,VCU
 SG_ Aux1AmbtColrCtlCstAvlFlg1 : 24|1@0+ (1,0) [0|1] "" RadioLow,CSM,CSM_AV,VCU
 SG_ Aux1AmbtBrghtnsCtlCstSetAval : 25|1@0+ (1,0) [0|1] "" RadioLow,CSM,CSM_AV,VCU
 SG_ Aux1AmbtBrghtnsCtlCstAvlFlg7 : 26|1@0+ (1,0) [0|1] "" RadioLow,CSM,CSM_AV,VCU
 SG_ Aux1AmbtBrghtnsCtlCstAvlFlg6 : 27|1@0+ (1,0) [0|1] "" RadioLow,CSM,CSM_AV,VCU
 SG_ Aux1AmbtBrghtnsCtlCstAvlFlg5 : 28|1@0+ (1,0) [0|1] "" RadioLow,CSM,CSM_AV,VCU
 SG_ Aux1AmbtBrghtnsCtlCstAvlFlg4 : 29|1@0+ (1,0) [0|1] "" RadioLow,CSM,CSM_AV,VCU
 SG_ Aux1AmbtBrghtnsCtlCstAvlFlg3 : 30|1@0+ (1,0) [0|1] "" RadioLow,CSM,CSM_AV,VCU
 SG_ Aux1AmbtBrghtnsCtlCstAvlFlg2 : 31|1@0+ (1,0) [0|1] "" RadioLow,CSM,CSM_AV,VCU
 SG_ Aux1AmbtColrCtlCstAvlFlg17 : 32|1@0+ (1,0) [0|1] "" RadioLow,CSM,CSM_AV,VCU
 SG_ Aux1AmbtColrCtlCstAvlFlg16 : 33|1@0+ (1,0) [0|1] "" RadioLow,CSM,CSM_AV,VCU
 SG_ Aux1AmbtColrCtlCstAvlFlg15 : 34|1@0+ (1,0) [0|1] "" RadioLow,CSM,CSM_AV,VCU
 SG_ Aux1AmbtColrCtlCstAvlFlg14 : 35|1@0+ (1,0) [0|1] "" RadioLow,CSM,CSM_AV,VCU
 SG_ Aux1AmbtColrCtlCstAvlFlg13 : 36|1@0+ (1,0) [0|1] "" RadioLow,CSM,CSM_AV,VCU
 SG_ Aux1AmbtColrCtlCstAvlFlg12 : 37|1@0+ (1,0) [0|1] "" RadioLow,CSM,CSM_AV,VCU
 SG_ Aux1AmbtColrCtlCstAvlFlg11 : 38|1@0+ (1,0) [0|1] "" RadioLow,CSM,CSM_AV,VCU
 SG_ Aux1AmbtColrCtlCstAvlFlg10 : 39|1@0+ (1,0) [0|1] "" RadioLow,CSM,CSM_AV,VCU
 SG_ Aux1AmbtColrCtlCstAvlFlg24 : 40|1@0+ (1,0) [0|1] "" RadioLow,CSM,CSM_AV,VCU
 SG_ Aux1AmbtColrCtlCstAvlFlg23 : 41|1@0+ (1,0) [0|1] "" RadioLow,CSM,CSM_AV,VCU
 SG_ Aux1AmbtColrCtlCstAvlFlg22 : 42|1@0+ (1,0) [0|1] "" RadioLow,CSM,CSM_AV,VCU
 SG_ Aux1AmbtColrCtlCstAvlFlg21 : 43|1@0+ (1,0) [0|1] "" RadioLow,CSM,CSM_AV,VCU
 SG_ Aux1AmbtColrCtlCstAvlFlg20 : 44|1@0+ (1,0) [0|1] "" RadioLow,CSM,CSM_AV,VCU
 SG_ Aux1AmbtColrCtlCstAvlFlg2 : 45|1@0+ (1,0) [0|1] "" RadioLow,CSM,CSM_AV,VCU
 SG_ Aux1AmbtColrCtlCstAvlFlg19 : 46|1@0+ (1,0) [0|1] "" RadioLow,CSM,CSM_AV,VCU
 SG_ Aux1AmbtColrCtlCstAvlFlg18 : 47|1@0+ (1,0) [0|1] "" RadioLow,CSM,CSM_AV,VCU
 SG_ Aux1AmbtColrCtlCstAvlFlg31 : 48|1@0+ (1,0) [0|1] "" RadioLow,CSM,CSM_AV,VCU
 SG_ Aux1AmbtColrCtlCstAvlFlg30 : 49|1@0+ (1,0) [0|1] "" RadioLow,CSM,CSM_AV,VCU
 SG_ Aux1AmbtColrCtlCstAvlFlg3 : 50|1@0+ (1,0) [0|1] "" RadioLow,CSM,CSM_AV,VCU
 SG_ Aux1AmbtColrCtlCstAvlFlg29 : 51|1@0+ (1,0) [0|1] "" RadioLow,CSM,CSM_AV,VCU
 SG_ Aux1AmbtColrCtlCstAvlFlg28 : 52|1@0+ (1,0) [0|1] "" RadioLow,CSM,CSM_AV,VCU
 SG_ Aux1AmbtColrCtlCstAvlFlg27 : 53|1@0+ (1,0) [0|1] "" RadioLow,CSM,CSM_AV,VCU
 SG_ Aux1AmbtColrCtlCstAvlFlg26 : 54|1@0+ (1,0) [0|1] "" RadioLow,CSM,CSM_AV,VCU
 SG_ Aux1AmbtColrCtlCstAvlFlg25 : 55|1@0+ (1,0) [0|1] "" RadioLow,CSM,CSM_AV,VCU
 SG_ Aux1AmbtColrCtlCstAvlFlg88 : 56|1@0+ (1,0) [0|1] "" VCU
 SG_ Aux1AmbtColrCtlCstSetAval : 57|1@0+ (1,0) [0|1] "" RadioLow,CSM,CSM_AV,VCU
 SG_ Aux1AmbtColrCtlCstAvlFlg9 : 58|1@0+ (1,0) [0|1] "" RadioLow,CSM,CSM_AV,VCU
 SG_ Aux1AmbtColrCtlCstAvlFlg8 : 59|1@0+ (1,0) [0|1] "" RadioLow,CSM,CSM_AV,VCU
 SG_ Aux1AmbtColrCtlCstAvlFlg7 : 60|1@0+ (1,0) [0|1] "" RadioLow,CSM,CSM_AV,VCU
 SG_ Aux1AmbtColrCtlCstAvlFlg6 : 61|1@0+ (1,0) [0|1] "" RadioLow,CSM,CSM_AV,VCU
 SG_ Aux1AmbtColrCtlCstAvlFlg5 : 62|1@0+ (1,0) [0|1] "" RadioLow,CSM,CSM_AV,VCU
 SG_ Aux1AmbtColrCtlCstAvlFlg4 : 63|1@0+ (1,0) [0|1] "" RadioLow,CSM,CSM_AV,VCU

BO_ 1191 PDU_9038: 8 CGM
 SG_ HndsFrStrgeAccssCstCfg : 7|3@0+ (1,0) [0|2] "" RadioLow,CSM,CSM_AV,VCU
 SG_ DaytimeTlLghtsCstAvlFlg7 : 8|1@0+ (1,0) [0|1] "" RadioLow,CSM,CSM_AV,VCU
 SG_ DaytimeTlLghtsCstAvlFlg6 : 9|1@0+ (1,0) [0|1] "" RadioLow,CSM,CSM_AV,VCU
 SG_ DaytimeTlLghtsCstAvlFlg5 : 10|1@0+ (1,0) [0|1] "" RadioLow,CSM,CSM_AV,VCU
 SG_ DaytimeTlLghtsCstAvlFlg4 : 11|1@0+ (1,0) [0|1] "" RadioLow,CSM,CSM_AV,VCU
 SG_ DaytimeTlLghtsCstAvlFlg3 : 12|1@0+ (1,0) [0|1] "" RadioLow,CSM,CSM_AV,VCU
 SG_ DaytimeTlLghtsCstAvlFlg2 : 13|1@0+ (1,0) [0|1] "" RadioLow,CSM,CSM_AV,VCU
 SG_ DaytimeTlLghtsCstAvlFlg1 : 14|1@0+ (1,0) [0|1] "" RadioLow,CSM,CSM_AV,VCU
 SG_ HFRCCstAvlFlg1 : 16|1@0+ (1,0) [0|1] "" RadioLow,CSM,CSM_AV,VCU
 SG_ ExtLghtCstAvlFlg7 : 17|1@0+ (1,0) [0|1] "" RadioLow,CSM,CSM_AV,VCU
 SG_ ExtLghtCstAvlFlg6 : 18|1@0+ (1,0) [0|1] "" RadioLow,CSM,CSM_AV,VCU
 SG_ ExtLghtCstAvlFlg5 : 19|1@0+ (1,0) [0|1] "" RadioLow,CSM,CSM_AV,VCU
 SG_ ExtLghtCstAvlFlg4 : 20|1@0+ (1,0) [0|1] "" RadioLow,CSM,CSM_AV,VCU
 SG_ ExtLghtCstAvlFlg3 : 21|1@0+ (1,0) [0|1] "" RadioLow,CSM,CSM_AV,VCU
 SG_ ExtLghtCstAvlFlg2 : 22|1@0+ (1,0) [0|1] "" RadioLow,CSM,CSM_AV,VCU
 SG_ ExtLghtCstAvlFlg1 : 23|1@0+ (1,0) [0|1] "" RadioLow,CSM,CSM_AV,VCU
 SG_ IntrAmbtAnmCtlCstAvlFlg10 : 24|1@0+ (1,0) [0|1] "" RadioLow,CSM,CSM_AV,VCU
 SG_ IntrAmbtAnmCtlCstAvlFlg1 : 25|1@0+ (1,0) [0|1] "" RadioLow,CSM,CSM_AV,VCU
 SG_ HFRCCstAvlFlg7 : 26|1@0+ (1,0) [0|1] "" RadioLow,CSM,CSM_AV,VCU
 SG_ HFRCCstAvlFlg6 : 27|1@0+ (1,0) [0|1] "" RadioLow,CSM,CSM_AV,VCU
 SG_ HFRCCstAvlFlg5 : 28|1@0+ (1,0) [0|1] "" RadioLow,CSM,CSM_AV,VCU
 SG_ HFRCCstAvlFlg4 : 29|1@0+ (1,0) [0|1] "" RadioLow,CSM,CSM_AV,VCU
 SG_ HFRCCstAvlFlg3 : 30|1@0+ (1,0) [0|1] "" RadioLow,CSM,CSM_AV,VCU
 SG_ HFRCCstAvlFlg2 : 31|1@0+ (1,0) [0|1] "" RadioLow,CSM,CSM_AV,VCU
 SG_ IntrAmbtAnmCtlCstAvlFlg4 : 32|1@0+ (1,0) [0|1] "" RadioLow,CSM,CSM_AV,VCU
 SG_ IntrAmbtAnmCtlCstAvlFlg3 : 33|1@0+ (1,0) [0|1] "" RadioLow,CSM,CSM_AV,VCU
 SG_ IntrAmbtAnmCtlCstAvlFlg2 : 34|1@0+ (1,0) [0|1] "" RadioLow,CSM,CSM_AV,VCU
 SG_ IntrAmbtAnmCtlCstAvlFlg15 : 35|1@0+ (1,0) [0|1] "" RadioLow,CSM,CSM_AV,VCU
 SG_ IntrAmbtAnmCtlCstAvlFlg14 : 36|1@0+ (1,0) [0|1] "" RadioLow,CSM,CSM_AV,VCU
 SG_ IntrAmbtAnmCtlCstAvlFlg13 : 37|1@0+ (1,0) [0|1] "" RadioLow,CSM,CSM_AV,VCU
 SG_ IntrAmbtAnmCtlCstAvlFlg12 : 38|1@0+ (1,0) [0|1] "" RadioLow,CSM,CSM_AV,VCU
 SG_ IntrAmbtAnmCtlCstAvlFlg11 : 39|1@0+ (1,0) [0|1] "" RadioLow,CSM,CSM_AV,VCU
 SG_ IntrAmbtBrghtnsCtlCstAvlFlg2 : 40|1@0+ (1,0) [0|1] "" RadioLow,CSM,CSM_AV,VCU
 SG_ IntrAmbtBrghtnsCtlCstAvlFlg1 : 41|1@0+ (1,0) [0|1] "" RadioLow,CSM,CSM_AV,VCU
 SG_ IntrAmbtAnmCtlCstSetAval : 42|1@0+ (1,0) [0|1] "" RadioLow,CSM,CSM_AV,VCU
 SG_ IntrAmbtAnmCtlCstAvlFlg9 : 43|1@0+ (1,0) [0|1] "" RadioLow,CSM,CSM_AV,VCU
 SG_ IntrAmbtAnmCtlCstAvlFlg8 : 44|1@0+ (1,0) [0|1] "" RadioLow,CSM,CSM_AV,VCU
 SG_ IntrAmbtAnmCtlCstAvlFlg7 : 45|1@0+ (1,0) [0|1] "" RadioLow,CSM,CSM_AV,VCU
 SG_ IntrAmbtAnmCtlCstAvlFlg6 : 46|1@0+ (1,0) [0|1] "" RadioLow,CSM,CSM_AV,VCU
 SG_ IntrAmbtAnmCtlCstAvlFlg5 : 47|1@0+ (1,0) [0|1] "" RadioLow,CSM,CSM_AV,VCU
 SG_ Aux1AmbtColrCtlCstAvlFlg75 : 48|1@0+ (1,0) [0|1] "" VCU
 SG_ Aux1AmbtColrCtlCstAvlFlg74 : 49|1@0+ (1,0) [0|1] "" VCU
 SG_ IntrAmbtBrghtnsCtlCstSetAval : 50|1@0+ (1,0) [0|1] "" RadioLow,CSM,CSM_AV,VCU
 SG_ IntrAmbtBrghtnsCtlCstAvlFlg7 : 51|1@0+ (1,0) [0|1] "" RadioLow,CSM,CSM_AV,VCU
 SG_ IntrAmbtBrghtnsCtlCstAvlFlg6 : 52|1@0+ (1,0) [0|1] "" RadioLow,CSM,CSM_AV,VCU
 SG_ IntrAmbtBrghtnsCtlCstAvlFlg5 : 53|1@0+ (1,0) [0|1] "" RadioLow,CSM,CSM_AV,VCU
 SG_ IntrAmbtBrghtnsCtlCstAvlFlg4 : 54|1@0+ (1,0) [0|1] "" RadioLow,CSM,CSM_AV,VCU
 SG_ IntrAmbtBrghtnsCtlCstAvlFlg3 : 55|1@0+ (1,0) [0|1] "" RadioLow,CSM,CSM_AV,VCU
 SG_ Aux1AmbtColrCtlCstAvlFlg83 : 56|1@0+ (1,0) [0|1] "" VCU
 SG_ Aux1AmbtColrCtlCstAvlFlg82 : 57|1@0+ (1,0) [0|1] "" VCU
 SG_ Aux1AmbtColrCtlCstAvlFlg81 : 58|1@0+ (1,0) [0|1] "" VCU
 SG_ Aux1AmbtColrCtlCstAvlFlg80 : 59|1@0+ (1,0) [0|1] "" VCU
 SG_ Aux1AmbtColrCtlCstAvlFlg79 : 60|1@0+ (1,0) [0|1] "" VCU
 SG_ Aux1AmbtColrCtlCstAvlFlg78 : 61|1@0+ (1,0) [0|1] "" VCU
 SG_ Aux1AmbtColrCtlCstAvlFlg77 : 62|1@0+ (1,0) [0|1] "" VCU
 SG_ Aux1AmbtColrCtlCstAvlFlg76 : 63|1@0+ (1,0) [0|1] "" VCU

BO_ 1875 PDU_9039: 8 CGM
 SG_ FTLDI_LFTmToFlt : 5|21@0+ (1,0) [0|2.09715e+006] "min" TCP,VCU
 SG_ FTLDI_LFSts : 7|2@0+ (1,0) [0|3] "" TCP,VCU
 SG_ FTLDI_RFSts : 16|2@0+ (1,0) [0|3] "" TCP,VCU
 SG_ FTLDI_RFTmToFlt : 30|21@0+ (1,0) [0|2.09715e+006] "min" TCP,VCU
 SG_ IntrAmbtColrCtlCstAvlFlg10 : 40|1@0+ (1,0) [0|1] "" RadioLow,CSM,CSM_AV,VCU
 SG_ IntrAmbtColrCtlCstAvlFlg1 : 41|1@0+ (1,0) [0|1] "" RadioLow,CSM,CSM_AV,VCU
 SG_ IntrAmbtColrCtlCstAvlFlg18 : 48|1@0+ (1,0) [0|1] "" RadioLow,CSM,CSM_AV,VCU
 SG_ IntrAmbtColrCtlCstAvlFlg17 : 49|1@0+ (1,0) [0|1] "" RadioLow,CSM,CSM_AV,VCU
 SG_ IntrAmbtColrCtlCstAvlFlg16 : 50|1@0+ (1,0) [0|1] "" RadioLow,CSM,CSM_AV,VCU
 SG_ IntrAmbtColrCtlCstAvlFlg15 : 51|1@0+ (1,0) [0|1] "" RadioLow,CSM,CSM_AV,VCU
 SG_ IntrAmbtColrCtlCstAvlFlg14 : 52|1@0+ (1,0) [0|1] "" RadioLow,CSM,CSM_AV,VCU
 SG_ IntrAmbtColrCtlCstAvlFlg13 : 53|1@0+ (1,0) [0|1] "" RadioLow,CSM,CSM_AV,VCU
 SG_ IntrAmbtColrCtlCstAvlFlg12 : 54|1@0+ (1,0) [0|1] "" RadioLow,CSM,CSM_AV,VCU
 SG_ IntrAmbtColrCtlCstAvlFlg11 : 55|1@0+ (1,0) [0|1] "" RadioLow,CSM,CSM_AV,VCU
 SG_ IntrAmbtColrCtlCstAvlFlg25 : 56|1@0+ (1,0) [0|1] "" RadioLow,CSM,CSM_AV,VCU
 SG_ IntrAmbtColrCtlCstAvlFlg24 : 57|1@0+ (1,0) [0|1] "" RadioLow,CSM,CSM_AV,VCU
 SG_ IntrAmbtColrCtlCstAvlFlg23 : 58|1@0+ (1,0) [0|1] "" RadioLow,CSM,CSM_AV,VCU
 SG_ IntrAmbtColrCtlCstAvlFlg22 : 59|1@0+ (1,0) [0|1] "" RadioLow,CSM,CSM_AV,VCU
 SG_ IntrAmbtColrCtlCstAvlFlg21 : 60|1@0+ (1,0) [0|1] "" RadioLow,CSM,CSM_AV,VCU
 SG_ IntrAmbtColrCtlCstAvlFlg20 : 61|1@0+ (1,0) [0|1] "" RadioLow,CSM,CSM_AV,VCU
 SG_ IntrAmbtColrCtlCstAvlFlg2 : 62|1@0+ (1,0) [0|1] "" RadioLow,CSM,CSM_AV,VCU
 SG_ IntrAmbtColrCtlCstAvlFlg19 : 63|1@0+ (1,0) [0|1] "" RadioLow,CSM,CSM_AV,VCU

BO_ 1190 PDU_9040: 8 CGM
 SG_ HmdtySnsrGlssTemp : 7|10@0+ (0.146,-50) [-50|99.358] "deg C" CSM,CSM_AV,VCU
 SG_ HmdtySnsrTemp : 13|10@0+ (0.146,-50) [-50|99.358] "deg C" CSM,CSM_AV,VCU
 SG_ HmdtySnsrRltvHmdty : 19|8@0+ (0.392,0) [0|99.96] "%" CSM,CSM_AV,VCU
 SG_ IntrAmbtColrCtlCstAvlFlg29 : 24|1@0+ (1,0) [0|1] "" RadioLow,CSM,CSM_AV,VCU
 SG_ IntrAmbtColrCtlCstAvlFlg28 : 25|1@0+ (1,0) [0|1] "" RadioLow,CSM,CSM_AV,VCU
 SG_ IntrAmbtColrCtlCstAvlFlg27 : 26|1@0+ (1,0) [0|1] "" RadioLow,CSM,CSM_AV,VCU
 SG_ IntrAmbtColrCtlCstAvlFlg26 : 27|1@0+ (1,0) [0|1] "" RadioLow,CSM,CSM_AV,VCU
 SG_ IntrAmbtColrCtlCstAvlFlg8 : 32|1@0+ (1,0) [0|1] "" RadioLow,CSM,CSM_AV,VCU
 SG_ IntrAmbtColrCtlCstAvlFlg7 : 33|1@0+ (1,0) [0|1] "" RadioLow,CSM,CSM_AV,VCU
 SG_ IntrAmbtColrCtlCstAvlFlg6 : 34|1@0+ (1,0) [0|1] "" RadioLow,CSM,CSM_AV,VCU
 SG_ IntrAmbtColrCtlCstAvlFlg5 : 35|1@0+ (1,0) [0|1] "" RadioLow,CSM,CSM_AV,VCU
 SG_ IntrAmbtColrCtlCstAvlFlg4 : 36|1@0+ (1,0) [0|1] "" RadioLow,CSM,CSM_AV,VCU
 SG_ IntrAmbtColrCtlCstAvlFlg31 : 37|1@0+ (1,0) [0|1] "" RadioLow,CSM,CSM_AV,VCU
 SG_ IntrAmbtColrCtlCstAvlFlg30 : 38|1@0+ (1,0) [0|1] "" RadioLow,CSM,CSM_AV,VCU
 SG_ IntrAmbtColrCtlCstAvlFlg3 : 39|1@0+ (1,0) [0|1] "" RadioLow,CSM,CSM_AV,VCU
 SG_ IonzrCtrlCstAvlFlg6 : 40|1@0+ (1,0) [0|1] "" RadioLow,CSM,CSM_AV,VCU
 SG_ IonzrCtrlCstAvlFlg5 : 41|1@0+ (1,0) [0|1] "" RadioLow,CSM,CSM_AV,VCU
 SG_ IonzrCtrlCstAvlFlg4 : 42|1@0+ (1,0) [0|1] "" RadioLow,CSM,CSM_AV,VCU
 SG_ IonzrCtrlCstAvlFlg3 : 43|1@0+ (1,0) [0|1] "" RadioLow,CSM,CSM_AV,VCU
 SG_ IonzrCtrlCstAvlFlg2 : 44|1@0+ (1,0) [0|1] "" RadioLow,CSM,CSM_AV,VCU
 SG_ IonzrCtrlCstAvlFlg1 : 45|1@0+ (1,0) [0|1] "" RadioLow,CSM,CSM_AV,VCU
 SG_ IntrAmbtColrCtlCstSetAval : 46|1@0+ (1,0) [0|1] "" RadioLow,CSM,CSM_AV,VCU
 SG_ IntrAmbtColrCtlCstAvlFlg9 : 47|1@0+ (1,0) [0|1] "" RadioLow,CSM,CSM_AV,VCU
 SG_ LDCLCstAvlFlg7 : 48|1@0+ (1,0) [0|1] "" RadioLow,CSM,CSM_AV,VCU
 SG_ LDCLCstAvlFlg6 : 49|1@0+ (1,0) [0|1] "" RadioLow,CSM,CSM_AV,VCU
 SG_ LDCLCstAvlFlg5 : 50|1@0+ (1,0) [0|1] "" RadioLow,CSM,CSM_AV,VCU
 SG_ LDCLCstAvlFlg4 : 51|1@0+ (1,0) [0|1] "" RadioLow,CSM,CSM_AV,VCU
 SG_ LDCLCstAvlFlg3 : 52|1@0+ (1,0) [0|1] "" RadioLow,CSM,CSM_AV,VCU
 SG_ LDCLCstAvlFlg2 : 53|1@0+ (1,0) [0|1] "" RadioLow,CSM,CSM_AV,VCU
 SG_ LDCLCstAvlFlg1 : 54|1@0+ (1,0) [0|1] "" RadioLow,CSM,CSM_AV,VCU
 SG_ IonzrCtrlCstAvlFlg7 : 55|1@0+ (1,0) [0|1] "" RadioLow,CSM,CSM_AV,VCU
 SG_ Aux1AmbtColrCtlCstAvlFlg89 : 56|1@0+ (1,0) [0|1] "" VCU
 SG_ OpDrAtLOCstAvlFlg7 : 57|1@0+ (1,0) [0|1] "" RadioLow,CSM,CSM_AV,VCU
 SG_ OpDrAtLOCstAvlFlg6 : 58|1@0+ (1,0) [0|1] "" RadioLow,CSM,CSM_AV,VCU
 SG_ OpDrAtLOCstAvlFlg5 : 59|1@0+ (1,0) [0|1] "" RadioLow,CSM,CSM_AV,VCU
 SG_ OpDrAtLOCstAvlFlg4 : 60|1@0+ (1,0) [0|1] "" RadioLow,CSM,CSM_AV,VCU
 SG_ OpDrAtLOCstAvlFlg3 : 61|1@0+ (1,0) [0|1] "" RadioLow,CSM,CSM_AV,VCU
 SG_ OpDrAtLOCstAvlFlg2 : 62|1@0+ (1,0) [0|1] "" RadioLow,CSM,CSM_AV,VCU
 SG_ OpDrAtLOCstAvlFlg1 : 63|1@0+ (1,0) [0|1] "" RadioLow,CSM,CSM_AV,VCU

BO_ 1876 PDU_9041: 8 CGM
 SG_ PsvUnlckCstAvlFlg1 : 0|1@0+ (1,0) [0|1] "" RadioLow,CSM,CSM_AV,VCU
 SG_ PlltnCtrlCstAvlFlg7 : 1|1@0+ (1,0) [0|1] "" RadioLow,CSM,CSM_AV,VCU
 SG_ PlltnCtrlCstAvlFlg6 : 2|1@0+ (1,0) [0|1] "" RadioLow,CSM,CSM_AV,VCU
 SG_ PlltnCtrlCstAvlFlg5 : 3|1@0+ (1,0) [0|1] "" RadioLow,CSM,CSM_AV,VCU
 SG_ PlltnCtrlCstAvlFlg4 : 4|1@0+ (1,0) [0|1] "" RadioLow,CSM,CSM_AV,VCU
 SG_ PlltnCtrlCstAvlFlg3 : 5|1@0+ (1,0) [0|1] "" RadioLow,CSM,CSM_AV,VCU
 SG_ PlltnCtrlCstAvlFlg2 : 6|1@0+ (1,0) [0|1] "" RadioLow,CSM,CSM_AV,VCU
 SG_ PlltnCtrlCstAvlFlg1 : 7|1@0+ (1,0) [0|1] "" RadioLow,CSM,CSM_AV,VCU
 SG_ RemInVehRmndrCstAvlFlg2 : 8|1@0+ (1,0) [0|1] "" RadioLow,CSM,CSM_AV,VCU
 SG_ RemInVehRmndrCstAvlFlg1 : 9|1@0+ (1,0) [0|1] "" RadioLow,CSM,CSM_AV,VCU
 SG_ PsvUnlckCstAvlFlg7 : 10|1@0+ (1,0) [0|1] "" RadioLow,CSM,CSM_AV,VCU
 SG_ PsvUnlckCstAvlFlg6 : 11|1@0+ (1,0) [0|1] "" RadioLow,CSM,CSM_AV,VCU
 SG_ PsvUnlckCstAvlFlg5 : 12|1@0+ (1,0) [0|1] "" RadioLow,CSM,CSM_AV,VCU
 SG_ PsvUnlckCstAvlFlg4 : 13|1@0+ (1,0) [0|1] "" RadioLow,CSM,CSM_AV,VCU
 SG_ PsvUnlckCstAvlFlg3 : 14|1@0+ (1,0) [0|1] "" RadioLow,CSM,CSM_AV,VCU
 SG_ PsvUnlckCstAvlFlg2 : 15|1@0+ (1,0) [0|1] "" RadioLow,CSM,CSM_AV,VCU
 SG_ RemLftVehRmndrCstAvlFlg3 : 16|1@0+ (1,0) [0|1] "" RadioLow,CSM,CSM_AV,VCU
 SG_ RemLftVehRmndrCstAvlFlg2 : 17|1@0+ (1,0) [0|1] "" RadioLow,CSM,CSM_AV,VCU
 SG_ RemLftVehRmndrCstAvlFlg1 : 18|1@0+ (1,0) [0|1] "" RadioLow,CSM,CSM_AV,VCU
 SG_ RemInVehRmndrCstAvlFlg7 : 19|1@0+ (1,0) [0|1] "" RadioLow,CSM,CSM_AV,VCU
 SG_ RemInVehRmndrCstAvlFlg6 : 20|1@0+ (1,0) [0|1] "" RadioLow,CSM,CSM_AV,VCU
 SG_ RemInVehRmndrCstAvlFlg5 : 21|1@0+ (1,0) [0|1] "" RadioLow,CSM,CSM_AV,VCU
 SG_ RemInVehRmndrCstAvlFlg4 : 22|1@0+ (1,0) [0|1] "" RadioLow,CSM,CSM_AV,VCU
 SG_ RemInVehRmndrCstAvlFlg3 : 23|1@0+ (1,0) [0|1] "" RadioLow,CSM,CSM_AV,VCU
 SG_ RevTltMirCstAvlFlg4 : 24|1@0+ (1,0) [0|1] "" RadioLow,CSM,CSM_AV,VCU
 SG_ RevTltMirCstAvlFlg3 : 25|1@0+ (1,0) [0|1] "" RadioLow,CSM,CSM_AV,VCU
 SG_ RevTltMirCstAvlFlg2 : 26|1@0+ (1,0) [0|1] "" RadioLow,CSM,CSM_AV,VCU
 SG_ RevTltMirCstAvlFlg1 : 27|1@0+ (1,0) [0|1] "" RadioLow,CSM,CSM_AV,VCU
 SG_ RemLftVehRmndrCstAvlFlg7 : 28|1@0+ (1,0) [0|1] "" RadioLow,CSM,CSM_AV,VCU
 SG_ RemLftVehRmndrCstAvlFlg6 : 29|1@0+ (1,0) [0|1] "" RadioLow,CSM,CSM_AV,VCU
 SG_ RemLftVehRmndrCstAvlFlg5 : 30|1@0+ (1,0) [0|1] "" RadioLow,CSM,CSM_AV,VCU
 SG_ RemLftVehRmndrCstAvlFlg4 : 31|1@0+ (1,0) [0|1] "" RadioLow,CSM,CSM_AV,VCU
 SG_ RlkRtUlkDrCstAvlFlg5 : 32|1@0+ (1,0) [0|1] "" RadioLow,CSM,CSM_AV,VCU
 SG_ RlkRtUlkDrCstAvlFlg4 : 33|1@0+ (1,0) [0|1] "" RadioLow,CSM,CSM_AV,VCU
 SG_ RlkRtUlkDrCstAvlFlg3 : 34|1@0+ (1,0) [0|1] "" RadioLow,CSM,CSM_AV,VCU
 SG_ RlkRtUlkDrCstAvlFlg2 : 35|1@0+ (1,0) [0|1] "" RadioLow,CSM,CSM_AV,VCU
 SG_ RlkRtUlkDrCstAvlFlg1 : 36|1@0+ (1,0) [0|1] "" RadioLow,CSM,CSM_AV,VCU
 SG_ RevTltMirCstAvlFlg7 : 37|1@0+ (1,0) [0|1] "" RadioLow,CSM,CSM_AV,VCU
 SG_ RevTltMirCstAvlFlg6 : 38|1@0+ (1,0) [0|1] "" RadioLow,CSM,CSM_AV,VCU
 SG_ RevTltMirCstAvlFlg5 : 39|1@0+ (1,0) [0|1] "" RadioLow,CSM,CSM_AV,VCU
 SG_ RmtSnrfOpCstAvlFlg6 : 40|1@0+ (1,0) [0|1] "" RadioLow,CSM,CSM_AV,VCU
 SG_ RmtSnrfOpCstAvlFlg5 : 41|1@0+ (1,0) [0|1] "" RadioLow,CSM,CSM_AV,VCU
 SG_ RmtSnrfOpCstAvlFlg4 : 42|1@0+ (1,0) [0|1] "" RadioLow,CSM,CSM_AV,VCU
 SG_ RmtSnrfOpCstAvlFlg3 : 43|1@0+ (1,0) [0|1] "" RadioLow,CSM,CSM_AV,VCU
 SG_ RmtSnrfOpCstAvlFlg2 : 44|1@0+ (1,0) [0|1] "" RadioLow,CSM,CSM_AV,VCU
 SG_ RmtSnrfOpCstAvlFlg1 : 45|1@0+ (1,0) [0|1] "" RadioLow,CSM,CSM_AV,VCU
 SG_ RlkRtUlkDrCstAvlFlg7 : 46|1@0+ (1,0) [0|1] "" RadioLow,CSM,CSM_AV,VCU
 SG_ RlkRtUlkDrCstAvlFlg6 : 47|1@0+ (1,0) [0|1] "" RadioLow,CSM,CSM_AV,VCU
 SG_ RmtStrtCoolStCstAvlFlg7 : 48|1@0+ (1,0) [0|1] "" RadioLow,CSM,CSM_AV,VCU
 SG_ RmtStrtCoolStCstAvlFlg6 : 49|1@0+ (1,0) [0|1] "" RadioLow,CSM,CSM_AV,VCU
 SG_ RmtStrtCoolStCstAvlFlg5 : 50|1@0+ (1,0) [0|1] "" RadioLow,CSM,CSM_AV,VCU
 SG_ RmtStrtCoolStCstAvlFlg4 : 51|1@0+ (1,0) [0|1] "" RadioLow,CSM,CSM_AV,VCU
 SG_ RmtStrtCoolStCstAvlFlg3 : 52|1@0+ (1,0) [0|1] "" RadioLow,CSM,CSM_AV,VCU
 SG_ RmtStrtCoolStCstAvlFlg2 : 53|1@0+ (1,0) [0|1] "" RadioLow,CSM,CSM_AV,VCU
 SG_ RmtStrtCoolStCstAvlFlg1 : 54|1@0+ (1,0) [0|1] "" RadioLow,CSM,CSM_AV,VCU
 SG_ RmtSnrfOpCstAvlFlg7 : 55|1@0+ (1,0) [0|1] "" RadioLow,CSM,CSM_AV,VCU
 SG_ Aux1AmbtColrCtlCstAvlFlg90 : 56|1@0+ (1,0) [0|1] "" VCU
 SG_ RmtStrtHtdStCstAvlFlg7 : 57|1@0+ (1,0) [0|1] "" RadioLow,CSM,CSM_AV,VCU
 SG_ RmtStrtHtdStCstAvlFlg6 : 58|1@0+ (1,0) [0|1] "" RadioLow,CSM,CSM_AV,VCU
 SG_ RmtStrtHtdStCstAvlFlg5 : 59|1@0+ (1,0) [0|1] "" RadioLow,CSM,CSM_AV,VCU
 SG_ RmtStrtHtdStCstAvlFlg4 : 60|1@0+ (1,0) [0|1] "" RadioLow,CSM,CSM_AV,VCU
 SG_ RmtStrtHtdStCstAvlFlg3 : 61|1@0+ (1,0) [0|1] "" RadioLow,CSM,CSM_AV,VCU
 SG_ RmtStrtHtdStCstAvlFlg2 : 62|1@0+ (1,0) [0|1] "" RadioLow,CSM,CSM_AV,VCU
 SG_ RmtStrtHtdStCstAvlFlg1 : 63|1@0+ (1,0) [0|1] "" RadioLow,CSM,CSM_AV,VCU

BO_ 1189 PDU_9042: 8 CGM
 SG_ RnSnsCstAvlFlg1 : 0|1@0+ (1,0) [0|1] "" RadioLow,CSM,CSM_AV,VCU
 SG_ RmtWndOpCstAvlFlg7 : 1|1@0+ (1,0) [0|1] "" RadioLow,CSM,CSM_AV,VCU
 SG_ RmtWndOpCstAvlFlg6 : 2|1@0+ (1,0) [0|1] "" RadioLow,CSM,CSM_AV,VCU
 SG_ RmtWndOpCstAvlFlg5 : 3|1@0+ (1,0) [0|1] "" RadioLow,CSM,CSM_AV,VCU
 SG_ RmtWndOpCstAvlFlg4 : 4|1@0+ (1,0) [0|1] "" RadioLow,CSM,CSM_AV,VCU
 SG_ RmtWndOpCstAvlFlg3 : 5|1@0+ (1,0) [0|1] "" RadioLow,CSM,CSM_AV,VCU
 SG_ RmtWndOpCstAvlFlg2 : 6|1@0+ (1,0) [0|1] "" RadioLow,CSM,CSM_AV,VCU
 SG_ RmtWndOpCstAvlFlg1 : 7|1@0+ (1,0) [0|1] "" RadioLow,CSM,CSM_AV,VCU
 SG_ RrDfgStUpCstAvlFlg2 : 8|1@0+ (1,0) [0|1] "" RadioLow,CSM,CSM_AV,VCU
 SG_ RrDfgStUpCstAvlFlg1 : 9|1@0+ (1,0) [0|1] "" RadioLow,CSM,CSM_AV,VCU
 SG_ RnSnsCstAvlFlg7 : 10|1@0+ (1,0) [0|1] "" RadioLow,CSM,CSM_AV,VCU
 SG_ RnSnsCstAvlFlg6 : 11|1@0+ (1,0) [0|1] "" RadioLow,CSM,CSM_AV,VCU
 SG_ RnSnsCstAvlFlg5 : 12|1@0+ (1,0) [0|1] "" RadioLow,CSM,CSM_AV,VCU
 SG_ RnSnsCstAvlFlg4 : 13|1@0+ (1,0) [0|1] "" RadioLow,CSM,CSM_AV,VCU
 SG_ RnSnsCstAvlFlg3 : 14|1@0+ (1,0) [0|1] "" RadioLow,CSM,CSM_AV,VCU
 SG_ RnSnsCstAvlFlg2 : 15|1@0+ (1,0) [0|1] "" RadioLow,CSM,CSM_AV,VCU
 SG_ RrStRmndrEnblDsblCstAvlFlg3 : 16|1@0+ (1,0) [0|1] "" RadioLow,CSM,CSM_AV,VCU
 SG_ RrStRmndrEnblDsblCstAvlFlg2 : 17|1@0+ (1,0) [0|1] "" RadioLow,CSM,CSM_AV,VCU
 SG_ RrStRmndrEnblDsblCstAvlFlg1 : 18|1@0+ (1,0) [0|1] "" RadioLow,CSM,CSM_AV,VCU
 SG_ RrDfgStUpCstAvlFlg7 : 19|1@0+ (1,0) [0|1] "" RadioLow,CSM,CSM_AV,VCU
 SG_ RrDfgStUpCstAvlFlg6 : 20|1@0+ (1,0) [0|1] "" RadioLow,CSM,CSM_AV,VCU
 SG_ RrDfgStUpCstAvlFlg5 : 21|1@0+ (1,0) [0|1] "" RadioLow,CSM,CSM_AV,VCU
 SG_ RrDfgStUpCstAvlFlg4 : 22|1@0+ (1,0) [0|1] "" RadioLow,CSM,CSM_AV,VCU
 SG_ RrDfgStUpCstAvlFlg3 : 23|1@0+ (1,0) [0|1] "" RadioLow,CSM,CSM_AV,VCU
 SG_ RrZnStUpCstAvlFlg4 : 24|1@0+ (1,0) [0|1] "" RadioLow,CSM,CSM_AV,VCU
 SG_ RrZnStUpCstAvlFlg3 : 25|1@0+ (1,0) [0|1] "" RadioLow,CSM,CSM_AV,VCU
 SG_ RrZnStUpCstAvlFlg2 : 26|1@0+ (1,0) [0|1] "" RadioLow,CSM,CSM_AV,VCU
 SG_ RrZnStUpCstAvlFlg1 : 27|1@0+ (1,0) [0|1] "" RadioLow,CSM,CSM_AV,VCU
 SG_ RrStRmndrEnblDsblCstAvlFlg7 : 28|1@0+ (1,0) [0|1] "" RadioLow,CSM,CSM_AV,VCU
 SG_ RrStRmndrEnblDsblCstAvlFlg6 : 29|1@0+ (1,0) [0|1] "" RadioLow,CSM,CSM_AV,VCU
 SG_ RrStRmndrEnblDsblCstAvlFlg5 : 30|1@0+ (1,0) [0|1] "" RadioLow,CSM,CSM_AV,VCU
 SG_ RrStRmndrEnblDsblCstAvlFlg4 : 31|1@0+ (1,0) [0|1] "" RadioLow,CSM,CSM_AV,VCU
 SG_ RtLkFdbkCstAvlFlg5 : 32|1@0+ (1,0) [0|1] "" RadioLow,CSM,CSM_AV,VCU
 SG_ RtLkFdbkCstAvlFlg4 : 33|1@0+ (1,0) [0|1] "" RadioLow,CSM,CSM_AV,VCU
 SG_ RtLkFdbkCstAvlFlg3 : 34|1@0+ (1,0) [0|1] "" RadioLow,CSM,CSM_AV,VCU
 SG_ RtLkFdbkCstAvlFlg2 : 35|1@0+ (1,0) [0|1] "" RadioLow,CSM,CSM_AV,VCU
 SG_ RtLkFdbkCstAvlFlg1 : 36|1@0+ (1,0) [0|1] "" RadioLow,CSM,CSM_AV,VCU
 SG_ RrZnStUpCstAvlFlg7 : 37|1@0+ (1,0) [0|1] "" RadioLow,CSM,CSM_AV,VCU
 SG_ RrZnStUpCstAvlFlg6 : 38|1@0+ (1,0) [0|1] "" RadioLow,CSM,CSM_AV,VCU
 SG_ RrZnStUpCstAvlFlg5 : 39|1@0+ (1,0) [0|1] "" RadioLow,CSM,CSM_AV,VCU
 SG_ RtUlkLtFbCstAvlFlg6 : 40|1@0+ (1,0) [0|1] "" RadioLow,CSM,CSM_AV,VCU
 SG_ RtUlkLtFbCstAvlFlg5 : 41|1@0+ (1,0) [0|1] "" RadioLow,CSM,CSM_AV,VCU
 SG_ RtUlkLtFbCstAvlFlg4 : 42|1@0+ (1,0) [0|1] "" RadioLow,CSM,CSM_AV,VCU
 SG_ RtUlkLtFbCstAvlFlg3 : 43|1@0+ (1,0) [0|1] "" RadioLow,CSM,CSM_AV,VCU
 SG_ RtUlkLtFbCstAvlFlg2 : 44|1@0+ (1,0) [0|1] "" RadioLow,CSM,CSM_AV,VCU
 SG_ RtUlkLtFbCstAvlFlg1 : 45|1@0+ (1,0) [0|1] "" RadioLow,CSM,CSM_AV,VCU
 SG_ RtLkFdbkCstAvlFlg7 : 46|1@0+ (1,0) [0|1] "" RadioLow,CSM,CSM_AV,VCU
 SG_ RtLkFdbkCstAvlFlg6 : 47|1@0+ (1,0) [0|1] "" RadioLow,CSM,CSM_AV,VCU
 SG_ SelUlkCstAvlFlg7 : 48|1@0+ (1,0) [0|1] "" RadioLow,CSM,CSM_AV,VCU
 SG_ SelUlkCstAvlFlg6 : 49|1@0+ (1,0) [0|1] "" RadioLow,CSM,CSM_AV,VCU
 SG_ SelUlkCstAvlFlg5 : 50|1@0+ (1,0) [0|1] "" RadioLow,CSM,CSM_AV,VCU
 SG_ SelUlkCstAvlFlg4 : 51|1@0+ (1,0) [0|1] "" RadioLow,CSM,CSM_AV,VCU
 SG_ SelUlkCstAvlFlg3 : 52|1@0+ (1,0) [0|1] "" RadioLow,CSM,CSM_AV,VCU
 SG_ SelUlkCstAvlFlg2 : 53|1@0+ (1,0) [0|1] "" RadioLow,CSM,CSM_AV,VCU
 SG_ SelUlkCstAvlFlg1 : 54|1@0+ (1,0) [0|1] "" RadioLow,CSM,CSM_AV,VCU
 SG_ RtUlkLtFbCstAvlFlg7 : 55|1@0+ (1,0) [0|1] "" RadioLow,CSM,CSM_AV,VCU
 SG_ Aux1AmbtColrCtlCstAvlFlg92 : 56|1@0+ (1,0) [0|1] "" VCU
 SG_ Aux1AmbtColrCtlCstAvlFlg91 : 57|1@0+ (1,0) [0|1] "" VCU
 SG_ TnDrvOvSpdWrnCstAvlFlg6 : 58|1@0+ (1,0) [0|1] "" RadioLow,TCP,CSM,CSM_AV,VCU
 SG_ TnDrvOvSpdWrnCstAvlFlg5 : 59|1@0+ (1,0) [0|1] "" RadioLow,TCP,CSM,CSM_AV,VCU
 SG_ TnDrvOvSpdWrnCstAvlFlg4 : 60|1@0+ (1,0) [0|1] "" RadioLow,TCP,CSM,CSM_AV,VCU
 SG_ TnDrvOvSpdWrnCstAvlFlg3 : 61|1@0+ (1,0) [0|1] "" RadioLow,TCP,CSM,CSM_AV,VCU
 SG_ TnDrvOvSpdWrnCstAvlFlg2 : 62|1@0+ (1,0) [0|1] "" RadioLow,TCP,CSM,CSM_AV,VCU
 SG_ TnDrvOvSpdWrnCstAvlFlg1 : 63|1@0+ (1,0) [0|1] "" RadioLow,TCP,CSM,CSM_AV,VCU

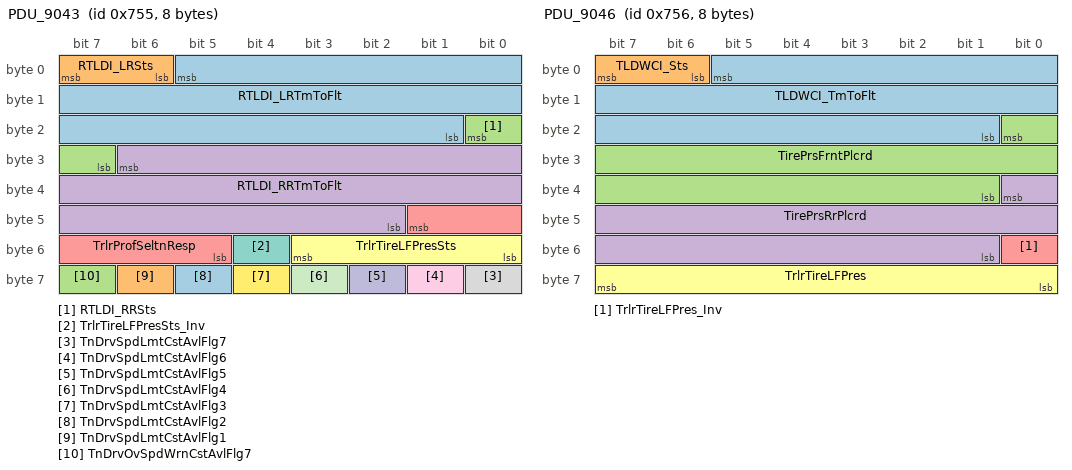
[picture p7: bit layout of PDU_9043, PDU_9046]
BO_ 1877 PDU_9043: 8 CGM
 SG_ RTLDI_LRTmToFlt : 5|21@0+ (1,0) [0|2.09715e+006] "min" TCP,VCU
 SG_ RTLDI_LRSts : 7|2@0+ (1,0) [0|3] "" TCP,VCU
 SG_ RTLDI_RRSts : 16|2@0+ (1,0) [0|3] "" TCP,VCU
 SG_ RTLDI_RRTmToFlt : 30|21@0+ (1,0) [0|2.09715e+006] "min" TCP,VCU
 SG_ TrlrProfSeltnResp : 41|5@0+ (1,0) [0|21] "" CSM,CSM_AV,VCU
 SG_ TrlrTireLFPresSts : 51|4@0+ (1,0) [0|8] "" VKM,CSM,CSM_AV,VCU
 SG_ TrlrTireLFPresSts_Inv : 52|1@0+ (1,0) [0|1] "" VKM,CSM,CSM_AV,VCU
 SG_ TnDrvSpdLmtCstAvlFlg7 : 56|1@0+ (1,0) [0|1] "" RadioLow,CSM,CSM_AV,VCU
 SG_ TnDrvSpdLmtCstAvlFlg6 : 57|1@0+ (1,0) [0|1] "" RadioLow,TCP,CSM,CSM_AV,VCU
 SG_ TnDrvSpdLmtCstAvlFlg5 : 58|1@0+ (1,0) [0|1] "" RadioLow,TCP,CSM,CSM_AV,VCU
 SG_ TnDrvSpdLmtCstAvlFlg4 : 59|1@0+ (1,0) [0|1] "" RadioLow,TCP,CSM,CSM_AV,VCU
 SG_ TnDrvSpdLmtCstAvlFlg3 : 60|1@0+ (1,0) [0|1] "" RadioLow,TCP,CSM,CSM_AV,VCU
 SG_ TnDrvSpdLmtCstAvlFlg2 : 61|1@0+ (1,0) [0|1] "" RadioLow,TCP,CSM,CSM_AV,VCU
 SG_ TnDrvSpdLmtCstAvlFlg1 : 62|1@0+ (1,0) [0|1] "" RadioLow,TCP,CSM,CSM_AV,VCU
 SG_ TnDrvOvSpdWrnCstAvlFlg7 : 63|1@0+ (1,0) [0|1] "" RadioLow,TCP,CSM,CSM_AV,VCU

BO_ 1878 PDU_9046: 8 CGM
 SG_ TLDWCI_TmToFlt : 5|21@0+ (1,0) [0|2.09715e+006] "min" TCP,VCU
 SG_ TLDWCI_Sts : 7|2@0+ (1,0) [0|3] "" TCP,VCU
 SG_ TirePrsFrntPlcrd : 16|16@0+ (0.0625,0) [0|4095.94] "kPaG" TCP,VKM,CSM,CSM_AV,VCU
 SG_ TirePrsRrPlcrd : 32|16@0+ (0.0625,0) [0|4095.94] "kPaG" TCP,VKM,VCU
 SG_ TrlrTireLFPres_Inv : 48|1@0+ (1,0) [0|1] "" VKM,CSM,CSM_AV,VCU
 SG_ TrlrTireLFPres : 63|8@0+ (4,0) [0|1020] "kPaG" VKM,CSM,CSM_AV,VCU

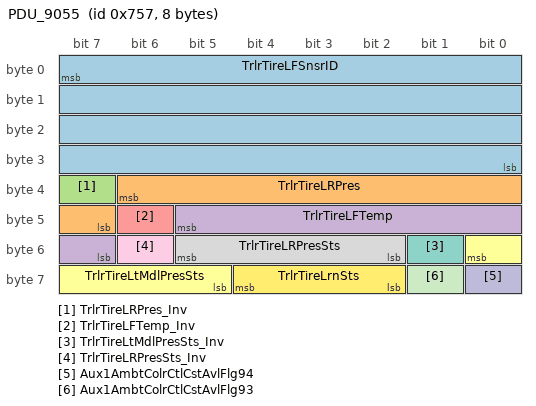
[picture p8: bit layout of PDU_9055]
BO_ 1879 PDU_9055: 8 CGM
 SG_ TrlrTireLFSnsrID : 7|32@0+ (1,0) [0|4.29497e+009] "" CSM,CSM_AV,VCU
 SG_ TrlrTireLRPres : 38|8@0+ (4,0) [0|1020] "kPaG" VKM,CSM,CSM_AV,VCU
 SG_ TrlrTireLRPres_Inv : 39|1@0+ (1,0) [0|1] "" VKM,CSM,CSM_AV,VCU
 SG_ TrlrTireLFTemp : 45|7@0+ (1,-20) [-20|107] "degC" CSM,CSM_AV,VCU
 SG_ TrlrTireLFTemp_Inv : 46|1@0+ (1,0) [0|1] "" CSM,CSM_AV,VCU
 SG_ TrlrTireLtMdlPresSts : 48|4@0+ (1,0) [0|8] "" VKM,CSM,CSM_AV,VCU
 SG_ TrlrTireLtMdlPresSts_Inv : 49|1@0+ (1,0) [0|1] "" VKM,CSM,CSM_AV,VCU
 SG_ TrlrTireLRPresSts : 53|4@0+ (1,0) [0|8] "" VKM,CSM,CSM_AV,VCU
 SG_ TrlrTireLRPresSts_Inv : 54|1@0+ (1,0) [0|1] "" VKM,CSM,CSM_AV,VCU
 SG_ Aux1AmbtColrCtlCstAvlFlg94 : 56|1@0+ (1,0) [0|1] "" VCU
 SG_ Aux1AmbtColrCtlCstAvlFlg93 : 57|1@0+ (1,0) [0|1] "" VCU
 SG_ TrlrTireLrnSts : 60|3@0+ (1,0) [0|4] "" CSM,CSM_AV,VCU

BA_DEF_ SG_  "SignalType" STRING ;
BA_DEF_ SG_  "SignalLongName" STRING ;
BA_DEF_ BO_  "GenMsgCycleTime" INT 0 10000;
BA_DEF_ BO_  "GenMsgSendType" ENUM "cyclicX","spontanX","cyclicIfActiveX","spontanWithDelay","cyclicAndSpontanX","cyclicAndSpontanWithDelay","spontanWithRepetition","cyclicIfActiveAndSpontanWD";
BA_DEF_DEF_  "SignalType" "";
BA_DEF_DEF_  "SignalLongName" "";
BA_DEF_DEF_  "GenMsgCycleTime" 0;
BA_DEF_DEF_  "GenMsgSendType" "cyclicX";
BA_ "GenMsgCycleTime" BO_ 1966 1000;
BA_ "GenMsgCycleTime" BO_ 662 100;
BA_ "GenMsgCycleTime" BO_ 1083 1000;
BA_ "GenMsgCycleTime" BO_ 1965 1000;
BA_ "GenMsgCycleTime" BO_ 1082 1000;
BA_ "GenMsgCycleTime" BO_ 1026 1000;
BA_ "GenMsgCycleTime" BO_ 1027 1000;
BA_ "GenMsgCycleTime" BO_ 1085 1000;
BA_ "GenMsgCycleTime" BO_ 1982 1000;
BA_ "GenMsgCycleTime" BO_ 1084 1000;
BA_ "GenMsgCycleTime" BO_ 1983 1000;
BA_ "GenMsgCycleTime" BO_ 1979 1000;
BA_ "GenMsgCycleTime" BO_ 95 10;
BA_ "GenMsgCycleTime" BO_ 1936 1000;
BA_ "GenMsgCycleTime" BO_ 1992 1000;
BA_ "GenMsgCycleTime" BO_ 1074 1000;
BA_ "GenMsgCycleTime" BO_ 1993 1000;
BA_ "GenMsgCycleTime" BO_ 939 500;
BA_ "GenMsgCycleTime" BO_ 1947 1000;
BA_ "GenMsgCycleTime" BO_ 1118 1000;
BA_ "GenMsgCycleTime" BO_ 1119 1000;
BA_ "GenMsgCycleTime" BO_ 1948 1000;
BA_ "GenMsgCycleTime" BO_ 1192 1000;
BA_ "GenMsgCycleTime" BO_ 1874 1000;
BA_ "GenMsgCycleTime" BO_ 1191 1000;
BA_ "GenMsgCycleTime" BO_ 1875 1000;
BA_ "GenMsgCycleTime" BO_ 1190 1000;
BA_ "GenMsgCycleTime" BO_ 1876 1000;
BA_ "GenMsgCycleTime" BO_ 1189 1000;
BA_ "GenMsgCycleTime" BO_ 1877 1000;
BA_ "GenMsgCycleTime" BO_ 1878 1000;
BA_ "GenMsgCycleTime" BO_ 1879 1000;
BA_ "SignalType" SG_ 1966 HVACICRFllAutoLF "ENM";
BA_ "SignalLongName" SG_ 1966 HVACICRFllAutoLF "Serial Data 288 : HVAC Infotainment Controls Request Full Auto Front Left";
BA_ "SignalType" SG_ 1966 HVACICRFllAutoThrdRow "ENM";
BA_ "SignalLongName" SG_ 1966 HVACICRFllAutoThrdRow "Serial Data 288 : HVAC Infotainment Controls Request Full Auto Third Row";
BA_ "SignalType" SG_ 1966 HVACICRFllAutoRR "ENM";
BA_ "SignalLongName" SG_ 1966 HVACICRFllAutoRR "Serial Data 288 : HVAC Infotainment Controls Request Full Auto Rear Right";
BA_ "SignalType" SG_ 1966 HVACICRFllAutoRF "ENM";
BA_ "SignalLongName" SG_ 1966 HVACICRFllAutoRF "Serial Data 288 : HVAC Infotainment Controls Request Full Auto Front Right";
BA_ "SignalType" SG_ 1966 HVACICRFllAutoLR "ENM";
BA_ "SignalLongName" SG_ 1966 HVACICRFllAutoLR "Serial Data 288 : HVAC Infotainment Controls Request Full Auto Rear Left";
BA_ "SignalType" SG_ 1966 HVACICRPwrRrRt "ENM";
BA_ "SignalLongName" SG_ 1966 HVACICRPwrRrRt "Serial Data 288 : HVAC Infotainment Controls Request Power Rear Right";
BA_ "SignalType" SG_ 1966 HVACICRPwrRrLt "ENM";
BA_ "SignalLongName" SG_ 1966 HVACICRPwrRrLt "Serial Data 288 : HVAC Infotainment Controls Request Power Rear Left";
BA_ "SignalType" SG_ 1966 HVACICRPwrFrtRt "ENM";
BA_ "SignalLongName" SG_ 1966 HVACICRPwrFrtRt "Serial Data 288 : HVAC Infotainment Controls Request Power Front Right";
BA_ "SignalType" SG_ 1966 HVACICRPwrFrtLt "ENM";
BA_ "SignalLongName" SG_ 1966 HVACICRPwrFrtLt "Serial Data 288 : HVAC Infotainment Controls Request Power Front Left";
BA_ "SignalType" SG_ 1966 HVACICRWprHtdPrkDcr "ENM";
BA_ "SignalLongName" SG_ 1966 HVACICRWprHtdPrkDcr "Serial Data 288 : HVAC Infotainment Controls Request Wiper Heated Park Deicer";
BA_ "SignalType" SG_ 1966 HVACICRThrdRowLck "ENM";
BA_ "SignalLongName" SG_ 1966 HVACICRThrdRowLck "Serial Data 288 : HVAC Infotainment Controls Request Third Row Lock";
BA_ "SignalType" SG_ 1966 HVACICRRrLck "ENM";
BA_ "SignalLongName" SG_ 1966 HVACICRRrLck "Serial Data 288 : HVAC Infotainment Controls Request Rear Lock";
BA_ "SignalType" SG_ 1966 HVACICRPwrThrdRow "ENM";
BA_ "SignalLongName" SG_ 1966 HVACICRPwrThrdRow "Serial Data 288 : HVAC Infotainment Controls Request Power Third Row";
BA_ "SignalLongName" SG_ 1966 SD288_ARC "Serial Data 288 : Alive Rolling Count";
BA_ "SignalLongName" SG_ 662 InfoPsngSysElvtn "Infotainment Positioning System Velocity : Infotainment Positioning System Elevation";
BA_ "SignalLongName" SG_ 662 InfoPsngSysHdg "Infotainment Positioning System Velocity : Infotainment Positioning System Heading";
BA_ "SignalType" SG_ 662 InfoPsngSysHdg_Inv "ENM";
BA_ "SignalLongName" SG_ 662 InfoPsngSysHdg_Inv "Infotainment Positioning System Velocity : Infotainment Positioning System Heading Invalid";
BA_ "SignalType" SG_ 662 InfoPsngSysElvtn_Inv "ENM";
BA_ "SignalLongName" SG_ 662 InfoPsngSysElvtn_Inv "Infotainment Positioning System Velocity : Infotainment Positioning System Elevation Invalid";
BA_ "SignalType" SG_ 1083 ACCCSR_Aux3Colr "ENM";
BA_ "SignalLongName" SG_ 1083 ACCCSR_Aux3Colr "Ambient Control Customization Change Setting Request Extended : Ambient Control Customization Change Setting Request Auxiliary 3 Color";
BA_ "SignalType" SG_ 1083 ACCCSR_Aux2Colr "ENM";
BA_ "SignalLongName" SG_ 1083 ACCCSR_Aux2Colr "Ambient Control Customization Change Setting Request Extended : Ambient Control Customization Change Setting Request Auxiliary 2 Color";
BA_ "SignalType" SG_ 1083 ACCCSR_Aux2Anm "ENM";
BA_ "SignalLongName" SG_ 1083 ACCCSR_Aux2Anm "Ambient Control Customization Change Setting Request Extended : Ambient Control Customization Change Setting Request Auxiliary 2 Animation";
BA_ "SignalType" SG_ 1083 ACCCSR_Aux2Brghtns "ENM";
BA_ "SignalLongName" SG_ 1083 ACCCSR_Aux2Brghtns "Ambient Control Customization Change Setting Request Extended : Ambient Control Customization Change Setting Request Auxiliary 2 Brightness";
BA_ "SignalType" SG_ 1083 ACCCSR_Aux3Anm "ENM";
BA_ "SignalLongName" SG_ 1083 ACCCSR_Aux3Anm "Ambient Control Customization Change Setting Request Extended : Ambient Control Customization Change Setting Request Auxiliary 3 Animation";
BA_ "SignalType" SG_ 1083 ACCCSR_Aux3Brghtns "ENM";
BA_ "SignalLongName" SG_ 1083 ACCCSR_Aux3Brghtns "Ambient Control Customization Change Setting Request Extended : Ambient Control Customization Change Setting Request Auxiliary 3 Brightness";
BA_ "SignalType" SG_ 1965 StMasgTypLFVirtCtlReq "ENM";
BA_ "SignalLongName" SG_ 1965 StMasgTypLFVirtCtlReq "Seat Left Front Virtual Control Request Information : Seat Massage Type Left Front Virtual Control Request";
BA_ "SignalType" SG_ 1965 StMemLFVirtCtlReq "ENM";
BA_ "SignalLongName" SG_ 1965 StMemLFVirtCtlReq "Seat Memory Left Front Virtual Control Request";
BA_ "SignalType" SG_ 1965 StBkHrztlLFCtlFrmFrtVirtCtlReq "ENM";
BA_ "SignalLongName" SG_ 1965 StBkHrztlLFCtlFrmFrtVirtCtlReq "Seat Left Front Virtual Control Request Information : Seat Back Horizontal Left Front Control From Front Virtual Control Request";
BA_ "SignalType" SG_ 1965 StMasgIntstyLFVirtCtlReq "ENM";
BA_ "SignalLongName" SG_ 1965 StMasgIntstyLFVirtCtlReq "Seat Left Front Virtual Control Request Information : Seat Massage Intensity Left Front Virtual Control Request";
BA_ "SignalType" SG_ 1965 StBkLumbHrztlLFVirtCtlReq "ENM";
BA_ "SignalLongName" SG_ 1965 StBkLumbHrztlLFVirtCtlReq "Seat Left Front Virtual Control Request Information : Seat Back Lumbar Horizontal Left Front Virtual Control Request";
BA_ "SignalType" SG_ 1965 StCushHrztlLFCtlFrmFrtVirtCtlRq "ENM";
BA_ "SignalLongName" SG_ 1965 StCushHrztlLFCtlFrmFrtVirtCtlRq "Seat Left Front Virtual Control Request Information : Seat Cushion Horizontal Left Front Control From Front Virtual Control Request";
BA_ "SignalType" SG_ 1965 StCushFrtVertLFVirtCtlReq "ENM";
BA_ "SignalLongName" SG_ 1965 StCushFrtVertLFVirtCtlReq "Seat Left Front Virtual Control Request Information : Seat Cushion Front Vertical Left Front Virtual Control Request";
BA_ "SignalType" SG_ 1965 StBkHrztlLFCtlFrmRrVirtCtlReq "ENM";
BA_ "SignalLongName" SG_ 1965 StBkHrztlLFCtlFrmRrVirtCtlReq "Seat Left Front Virtual Control Request Information : Seat Back Horizontal Left Front Control From Rear Virtual Control Request";
BA_ "SignalType" SG_ 1965 StBkLumbVertLFVirtCtlReq "ENM";
BA_ "SignalLongName" SG_ 1965 StBkLumbVertLFVirtCtlReq "Seat Left Front Virtual Control Request Information : Seat Back Lumbar Vertical Left Front Virtual Control Request";
BA_ "SignalType" SG_ 1965 StCushRrVertLFVirtCtlReq "ENM";
BA_ "SignalLongName" SG_ 1965 StCushRrVertLFVirtCtlReq "Seat Left Front Virtual Control Request Information : Seat Cushion Rear Vertical Left Front Virtual Control Request";
BA_ "SignalType" SG_ 1965 StCushLgthHrztlLFVirtCtlReq "ENM";
BA_ "SignalLongName" SG_ 1965 StCushLgthHrztlLFVirtCtlReq "Seat Left Front Virtual Control Request Information : Seat Cushion Length Horizontal Left Front Virtual Control Request";
BA_ "SignalType" SG_ 1965 StCushHrztlLFCtlFrmRrVirtCtlReq "ENM";
BA_ "SignalLongName" SG_ 1965 StCushHrztlLFCtlFrmRrVirtCtlReq "Seat Left Front Virtual Control Request Information : Seat Cushion Horizontal Left Front Control From Rear Virtual Control Request";
BA_ "SignalType" SG_ 1965 StHdrstVertLFVirtCtlReq "ENM";
BA_ "SignalLongName" SG_ 1965 StHdrstVertLFVirtCtlReq "Seat Left Front Virtual Control Request Information : Seat Headrest Vertical Left Front Virtual Control Request";
BA_ "SignalType" SG_ 1965 StHdrstHrztlLFVirtCtlReq "ENM";
BA_ "SignalLongName" SG_ 1965 StHdrstHrztlLFVirtCtlReq "Seat Left Front Virtual Control Request Information : Seat Headrest Horizontal Left Front Virtual Control Request";
BA_ "SignalType" SG_ 1965 StBkSdBolsLFVirtCtlReq "ENM";
BA_ "SignalLongName" SG_ 1965 StBkSdBolsLFVirtCtlReq "Seat Left Front Virtual Control Request Information : Seat Back Side Bolster Left Front Virtual Control Request";
BA_ "SignalType" SG_ 1965 StCushSdBolsLFVirtCtlReq "ENM";
BA_ "SignalLongName" SG_ 1965 StCushSdBolsLFVirtCtlReq "Seat Left Front Virtual Control Request Information : Seat Cushion Side Bolster Left Front Virtual Control Request";
BA_ "SignalType" SG_ 1965 StUpprShldrHrztlLFVirtCtlReq "ENM";
BA_ "SignalLongName" SG_ 1965 StUpprShldrHrztlLFVirtCtlReq "Seat Left Front Virtual Control Request Information : Seat Upper Shoulder Horizontal Left Front Virtual Control Request";
BA_ "SignalType" SG_ 1082 StMasgIntstyLRVirtCtlReq "ENM";
BA_ "SignalLongName" SG_ 1082 StMasgIntstyLRVirtCtlReq "Seat Left Rear Virtual Control Request Information : Seat Massage Intensity Left Rear Virtual Control Request";
BA_ "SignalType" SG_ 1082 StMasgTypLRVirtCtlReq "ENM";
BA_ "SignalLongName" SG_ 1082 StMasgTypLRVirtCtlReq "Seat Left Rear Virtual Control Request Information : Seat Massage Type Left Rear Virtual Control Request";
BA_ "SignalType" SG_ 1082 StCushLgthHrztlLRVirtCtlReq "ENM";
BA_ "SignalLongName" SG_ 1082 StCushLgthHrztlLRVirtCtlReq "Seat Left Rear Virtual Control Request Information : Seat Cushion Length Horizontal Left Rear Virtual Control Request";
BA_ "SignalType" SG_ 1082 StCushHrztlLRVirtCtlReq "ENM";
BA_ "SignalLongName" SG_ 1082 StCushHrztlLRVirtCtlReq "Seat Left Rear Virtual Control Request Information : Seat Cushion Horizontal Left Rear Virtual Control Request";
BA_ "SignalType" SG_ 1082 StCushFrtVertLRVirtCtlReq "ENM";
BA_ "SignalLongName" SG_ 1082 StCushFrtVertLRVirtCtlReq "Seat Left Rear Virtual Control Request Information : Seat Cushion Front Vertical Left Rear Virtual Control Request";
BA_ "SignalType" SG_ 1082 StBkHrztlLRVirtCtlReq "ENM";
BA_ "SignalLongName" SG_ 1082 StBkHrztlLRVirtCtlReq "Seat Left Rear Virtual Control Request Information : Seat Back Horizontal Left Rear Virtual Control Request";
BA_ "SignalType" SG_ 1082 StBkLumbVertLRVirtCtlReq "ENM";
BA_ "SignalLongName" SG_ 1082 StBkLumbVertLRVirtCtlReq "Seat Left Rear Virtual Control Request Information : Seat Back Lumbar Vertical Left Rear Virtual Control Request";
BA_ "SignalType" SG_ 1082 StCushSdBolsLRVirtCtlReq "ENM";
BA_ "SignalLongName" SG_ 1082 StCushSdBolsLRVirtCtlReq "Seat Left Rear Virtual Control Request Information : Seat Cushion Side Bolster Left Rear Virtual Control Request";
BA_ "SignalType" SG_ 1082 StBkLumbHrztlLRVirtCtlReq "ENM";
BA_ "SignalLongName" SG_ 1082 StBkLumbHrztlLRVirtCtlReq "Seat Left Rear Virtual Control Request Information : Seat Back Lumbar Horizontal Left Rear Virtual Control Request";
BA_ "SignalType" SG_ 1082 StCushRrVertLRVirtCtlReq "ENM";
BA_ "SignalLongName" SG_ 1082 StCushRrVertLRVirtCtlReq "Seat Left Rear Virtual Control Request Information : Seat Cushion Rear Vertical Left Rear Virtual Control Request";
BA_ "SignalType" SG_ 1082 StUpprShldrHrztlLRVirtCtlReq "ENM";
BA_ "SignalLongName" SG_ 1082 StUpprShldrHrztlLRVirtCtlReq "Seat Left Rear Virtual Control Request Information : Seat Upper Shoulder Horizontal Left Rear Virtual Control Request";
BA_ "SignalType" SG_ 1082 StHdrstVertLRVirtCtlReq "ENM";
BA_ "SignalLongName" SG_ 1082 StHdrstVertLRVirtCtlReq "Seat Left Rear Virtual Control Request Information : Seat Headrest Vertical Left Rear Virtual Control Request";
BA_ "SignalType" SG_ 1082 StHdrstHrztlLRVirtCtlReq "ENM";
BA_ "SignalLongName" SG_ 1082 StHdrstHrztlLRVirtCtlReq "Seat Left Rear Virtual Control Request Information : Seat Headrest Horizontal Left Rear Virtual Control Request";
BA_ "SignalType" SG_ 1082 StBkSdBolsLRVirtCtlReq "ENM";
BA_ "SignalLongName" SG_ 1082 StBkSdBolsLRVirtCtlReq "Seat Left Rear Virtual Control Request Information : Seat Back Side Bolster Left Rear Virtual Control Request";
BA_ "SignalType" SG_ 1082 StLckoutLRVirtCtlReq "ENM";
BA_ "SignalLongName" SG_ 1082 StLckoutLRVirtCtlReq "Seat Lockout Left Rear Virtual Control Request";
BA_ "SignalType" SG_ 1026 StMasgIntstyRFVirtCtlReq "ENM";
BA_ "SignalLongName" SG_ 1026 StMasgIntstyRFVirtCtlReq "Seat Right Front Virtual Control Request Information : Seat Massage Intensity Right Front Virtual Control Request";
BA_ "SignalType" SG_ 1026 StMasgTypRFVirtCtlReq "ENM";
BA_ "SignalLongName" SG_ 1026 StMasgTypRFVirtCtlReq "Seat Right Front Virtual Control Request Information : Seat Massage Type Right Front Virtual Control Request";
BA_ "SignalType" SG_ 1026 StCushHrztlRFCtlFrmFrtVirtCtlRq "ENM";
BA_ "SignalLongName" SG_ 1026 StCushHrztlRFCtlFrmFrtVirtCtlRq "Seat Right Front Virtual Control Request Information : Seat Cushion Horizontal Right Front Control From Front Virtual Control Request";
BA_ "SignalType" SG_ 1026 StBkHrztlRFCtlFrmRrVirtCtlReq "ENM";
BA_ "SignalLongName" SG_ 1026 StBkHrztlRFCtlFrmRrVirtCtlReq "Seat Right Front Virtual Control Request Information : Seat Back Horizontal Right Front Control From Rear Virtual Control Request";
BA_ "SignalType" SG_ 1026 StCushFrtVertRFVirtCtlReq "ENM";
BA_ "SignalLongName" SG_ 1026 StCushFrtVertRFVirtCtlReq "Seat Right Front Virtual Control Request Information : Seat Cushion Front Vertical Right Front Virtual Control Request";
BA_ "SignalType" SG_ 1026 StBkHrztlRFCtlFrmFrtVirtCtlReq "ENM";
BA_ "SignalLongName" SG_ 1026 StBkHrztlRFCtlFrmFrtVirtCtlReq "Seat Right Front Virtual Control Request Information : Seat Back Horizontal Right Front Control From Front Virtual Control Request";
BA_ "SignalType" SG_ 1026 StCushRrVertRFVirtCtlReq "ENM";
BA_ "SignalLongName" SG_ 1026 StCushRrVertRFVirtCtlReq "Seat Right Front Virtual Control Request Information : Seat Cushion Rear Vertical Right Front Virtual Control Request";
BA_ "SignalType" SG_ 1026 StBkLumbHrztlRFVirtCtlReq "ENM";
BA_ "SignalLongName" SG_ 1026 StBkLumbHrztlRFVirtCtlReq "Seat Right Front Virtual Control Request Information : Seat Back Lumbar Horizontal Right Front Virtual Control Request";
BA_ "SignalType" SG_ 1026 StCushLgthHrztlRFVirtCtlReq "ENM";
BA_ "SignalLongName" SG_ 1026 StCushLgthHrztlRFVirtCtlReq "Seat Right Front Virtual Control Request Information : Seat Cushion Length Horizontal Right Front Virtual Control Request";
BA_ "SignalType" SG_ 1026 StCushHrztlRFCtlFrmRrVirtCtlReq "ENM";
BA_ "SignalLongName" SG_ 1026 StCushHrztlRFCtlFrmRrVirtCtlReq "Seat Right Front Virtual Control Request Information : Seat Cushion Horizontal Right Front Control From Rear Virtual Control Request";
BA_ "SignalType" SG_ 1026 StHdrstHrztlRFVirtCtlReq "ENM";
BA_ "SignalLongName" SG_ 1026 StHdrstHrztlRFVirtCtlReq "Seat Right Front Virtual Control Request Information : Seat Headrest Horizontal Right Front Virtual Control Request";
BA_ "SignalType" SG_ 1026 StBkSdBolsRFVirtCtlReq "ENM";
BA_ "SignalLongName" SG_ 1026 StBkSdBolsRFVirtCtlReq "Seat Right Front Virtual Control Request Information : Seat Back Side Bolster Right Front Virtual Control Request";
BA_ "SignalType" SG_ 1026 StBkLumbVertRFVirtCtlReq "ENM";
BA_ "SignalLongName" SG_ 1026 StBkLumbVertRFVirtCtlReq "Seat Right Front Virtual Control Request Information : Seat Back Lumbar Vertical Right Front Virtual Control Request";
BA_ "SignalType" SG_ 1026 StCushSdBolsRFVirtCtlReq "ENM";
BA_ "SignalLongName" SG_ 1026 StCushSdBolsRFVirtCtlReq "Seat Right Front Virtual Control Request Information : Seat Cushion Side Bolster Right Front Virtual Control Request";
BA_ "SignalType" SG_ 1026 StUpprShldrHrztlRFVirtCtlReq "ENM";
BA_ "SignalLongName" SG_ 1026 StUpprShldrHrztlRFVirtCtlReq "Seat Right Front Virtual Control Request Information : Seat Upper Shoulder Horizontal Right Front Virtual Control Request";
BA_ "SignalType" SG_ 1026 StHdrstVertRFVirtCtlReq "ENM";
BA_ "SignalLongName" SG_ 1026 StHdrstVertRFVirtCtlReq "Seat Right Front Virtual Control Request Information : Seat Headrest Vertical Right Front Virtual Control Request";
BA_ "SignalType" SG_ 1027 StMasgIntstyRRVirtCtlReq "ENM";
BA_ "SignalLongName" SG_ 1027 StMasgIntstyRRVirtCtlReq "Seat Right Rear Virtual Control Request Information : Seat Massage Intensity Right Rear Virtual Control Request";
BA_ "SignalType" SG_ 1027 StMasgTypRRVirtCtlReq "ENM";
BA_ "SignalLongName" SG_ 1027 StMasgTypRRVirtCtlReq "Seat Right Rear Virtual Control Request Information : Seat Massage Type Right Rear Virtual Control Request";
BA_ "SignalType" SG_ 1027 StBkSdBolsRRVirtCtlReq "ENM";
BA_ "SignalLongName" SG_ 1027 StBkSdBolsRRVirtCtlReq "Seat Right Rear Virtual Control Request Information : Seat Back Side Bolster Right Rear Virtual Control Request";
BA_ "SignalType" SG_ 1027 StBkLumbVertRRVirtCtlReq "ENM";
BA_ "SignalLongName" SG_ 1027 StBkLumbVertRRVirtCtlReq "Seat Right Rear Virtual Control Request Information : Seat Back Lumbar Vertical Right Rear Virtual Control Request";
BA_ "SignalType" SG_ 1027 StBkLumbHrztlRRVirtCtlReq "ENM";
BA_ "SignalLongName" SG_ 1027 StBkLumbHrztlRRVirtCtlReq "Seat Right Rear Virtual Control Request Information : Seat Back Lumbar Horizontal Right Rear Virtual Control Request";
BA_ "SignalType" SG_ 1027 StBkHrztlRRVirtCtlReq "ENM";
BA_ "SignalLongName" SG_ 1027 StBkHrztlRRVirtCtlReq "Seat Right Rear Virtual Control Request Information : Seat Back Horizontal Right Rear Virtual Control Request";
BA_ "SignalType" SG_ 1027 StCushRrVertRRVirtCtlReq "ENM";
BA_ "SignalLongName" SG_ 1027 StCushRrVertRRVirtCtlReq "Seat Right Rear Virtual Control Request Information : Seat Cushion Rear Vertical Right Rear Virtual Control Request";
BA_ "SignalType" SG_ 1027 StCushLgthHrztlRRVirtCtlReq "ENM";
BA_ "SignalLongName" SG_ 1027 StCushLgthHrztlRRVirtCtlReq "Seat Right Rear Virtual Control Request Information : Seat Cushion Length Horizontal Right Rear Virtual Control Request";
BA_ "SignalType" SG_ 1027 StCushHrztlRRVirtCtlReq "ENM";
BA_ "SignalLongName" SG_ 1027 StCushHrztlRRVirtCtlReq "Seat Right Rear Virtual Control Request Information : Seat Cushion Horizontal Right Rear Virtual Control Request";
BA_ "SignalType" SG_ 1027 StCushFrtVertRRVirtCtlReq "ENM";
BA_ "SignalLongName" SG_ 1027 StCushFrtVertRRVirtCtlReq "Seat Right Rear Virtual Control Request Information : Seat Cushion Front Vertical Right Rear Virtual Control Request";
BA_ "SignalType" SG_ 1027 StUpprShldrHrztlRRVirtCtlReq "ENM";
BA_ "SignalLongName" SG_ 1027 StUpprShldrHrztlRRVirtCtlReq "Seat Right Rear Virtual Control Request Information : Seat Upper Shoulder Horizontal Right Rear Virtual Control Request";
BA_ "SignalType" SG_ 1027 StHdrstVertRRVirtCtlReq "ENM";
BA_ "SignalLongName" SG_ 1027 StHdrstVertRRVirtCtlReq "Seat Right Rear Virtual Control Request Information : Seat Headrest Vertical Right Rear Virtual Control Request";
BA_ "SignalType" SG_ 1027 StHdrstHrztlRRVirtCtlReq "ENM";
BA_ "SignalLongName" SG_ 1027 StHdrstHrztlRRVirtCtlReq "Seat Right Rear Virtual Control Request Information : Seat Headrest Horizontal Right Rear Virtual Control Request";
BA_ "SignalType" SG_ 1027 StCushSdBolsRRVirtCtlReq "ENM";
BA_ "SignalLongName" SG_ 1027 StCushSdBolsRRVirtCtlReq "Seat Right Rear Virtual Control Request Information : Seat Cushion Side Bolster Right Rear Virtual Control Request";
BA_ "SignalType" SG_ 1027 StLckoutRRVirtCtlReq "ENM";
BA_ "SignalLongName" SG_ 1027 StLckoutRRVirtCtlReq "Seat Lockout Right Rear Virtual Control Request";
BA_ "SignalLongName" SG_ 1085 TrlrTirePresLFInrXferdSnsrID "Trailer Tire Pressure Left Front Inner Transferred Sensor ID";
BA_ "SignalLongName" SG_ 1085 TrlrTirePresLRInrXferdSnsrID "Trailer Tire Pressure Left Rear Inner Transferred Sensor ID";
BA_ "SignalLongName" SG_ 1982 TrlrTirePresLtMdlInrXferdSnsrID "Trailer Tire Pressure Left Middle Inner Transferred Sensor ID";
BA_ "SignalLongName" SG_ 1982 TrlrTirePresRFInrXferdSnsrID "Trailer Tire Pressure Right Front Inner Transferred Sensor ID";
BA_ "SignalLongName" SG_ 1084 TrlrTirePresRRInrXferdSnsrID "Trailer Tire Pressure Right Rear Inner Transferred Sensor ID";
BA_ "SignalLongName" SG_ 1084 TrlrTirePresRtMdlInrXferdSnsrID "Trailer Tire Pressure Right Middle Inner Transferred Sensor ID";
BA_ "SignalLongName" SG_ 1983 InfoUTCYr "Infotainment UTC Date and Time : Year";
BA_ "SignalLongName" SG_ 1983 InfoUTCSec "Infotainment UTC Date and Time : Seconds";
BA_ "SignalLongName" SG_ 1983 InfoUTCMin "Infotainment UTC Date and Time : Minutes";
BA_ "SignalLongName" SG_ 1983 InfoUTCDay "Infotainment UTC Date and Time : Day";
BA_ "SignalType" SG_ 1983 InfoUTCMth "ENM";
BA_ "SignalLongName" SG_ 1983 InfoUTCMth "Infotainment UTC Date and Time : Month";
BA_ "SignalLongName" SG_ 1983 InfoUTCHrs "Infotainment UTC Date and Time : Hours";
BA_ "SignalType" SG_ 1983 InfoUTCYr_Inv "ENM";
BA_ "SignalLongName" SG_ 1983 InfoUTCYr_Inv "Infotainment UTC Date and Time : Year Invalid";
BA_ "SignalType" SG_ 1983 InfoUTCSec_Inv "ENM";
BA_ "SignalLongName" SG_ 1983 InfoUTCSec_Inv "Infotainment UTC Date and Time : Seconds Invalid";
BA_ "SignalType" SG_ 1983 InfoUTCMth_Inv "ENM";
BA_ "SignalLongName" SG_ 1983 InfoUTCMth_Inv "Infotainment UTC Date and Time : Month Invalid";
BA_ "SignalType" SG_ 1983 InfoUTCMin_Inv "ENM";
BA_ "SignalLongName" SG_ 1983 InfoUTCMin_Inv "Infotainment UTC Date and Time : Minutes Invalid";
BA_ "SignalType" SG_ 1983 InfoUTCHrs_Inv "ENM";
BA_ "SignalLongName" SG_ 1983 InfoUTCHrs_Inv "Infotainment UTC Date and Time : Hours Invalid";
BA_ "SignalType" SG_ 1983 InfoUTCDay_Inv "ENM";
BA_ "SignalLongName" SG_ 1983 InfoUTCDay_Inv "Infotainment UTC Date and Time : Day Invalid";
BA_ "SignalLongName" SG_ 1983 OffbrdEngyXferMinSOCReq "Offboard Energy Transfer Minimum State of Charge Information : Offboard Energy Transfer Minimum State of Charge Request";
BA_ "SignalType" SG_ 1983 DrvrSeltdOtltOffPwrMdVirCtlRq "ENM";
BA_ "SignalLongName" SG_ 1983 DrvrSeltdOtltOffPwrMdVirCtlRq "Driver Selected Outlet Off Power Mode Virtual Control Request";
BA_ "SignalLongName" SG_ 1983 OtltsOffPwrModeTmrReqVal "Outlets Off Power Mode Timer Request Information : Outlets Off Power Mode Timer Request Value";
BA_ "SignalType" SG_ 1983 OtltsOffPwrModeTmrOpCstSetReq "ENM";
BA_ "SignalLongName" SG_ 1983 OtltsOffPwrModeTmrOpCstSetReq "Outlets Off Power Mode Timer Operation Customization Setting Request";
BA_ "SignalType" SG_ 1983 OffbrdEngyXferMinSOCReq_DuD "ENM";
BA_ "SignalLongName" SG_ 1983 OffbrdEngyXferMinSOCReq_DuD "Offboard Energy Transfer Minimum State of Charge Information : Offboard Energy Transfer Minimum State of Charge Request Don't Use Data";
BA_ "SignalType" SG_ 1983 OtltsOffPwrModeTmrReqVal_DuD "ENM";
BA_ "SignalLongName" SG_ 1983 OtltsOffPwrModeTmrReqVal_DuD "Outlets Off Power Mode Timer Request Information : Outlets Off Power Mode Timer Request Value Don't Use Data";
BA_ "SignalType" SG_ 1979 VirtCtlGlsRfTntLvlPnl3Req "ENM";
BA_ "SignalLongName" SG_ 1979 VirtCtlGlsRfTntLvlPnl3Req "Virtual Control Glass Roof and Shade Information : Virtual Control Glass Roof Tint Level Panel 3 Request";
BA_ "SignalType" SG_ 1979 VirtCtlGlsRfTntLvlPnl2Req "ENM";
BA_ "SignalLongName" SG_ 1979 VirtCtlGlsRfTntLvlPnl2Req "Virtual Control Glass Roof and Shade Information : Virtual Control Glass Roof Tint Level Panel 2 Request";
BA_ "SignalType" SG_ 1979 VirtCtlGlsRfTntLvlPnl1Req "ENM";
BA_ "SignalLongName" SG_ 1979 VirtCtlGlsRfTntLvlPnl1Req "Virtual Control Glass Roof and Shade Information : Virtual Control Glass Roof Tint Level Panel 1 Request";
BA_ "SignalType" SG_ 1979 VirtCtlGlsRfTntLvlPnl6Req "ENM";
BA_ "SignalLongName" SG_ 1979 VirtCtlGlsRfTntLvlPnl6Req "Virtual Control Glass Roof and Shade Information : Virtual Control Glass Roof Tint Level Panel 6 Request";
BA_ "SignalType" SG_ 1979 VirtCtlGlsRfTntLvlPnl5Req "ENM";
BA_ "SignalLongName" SG_ 1979 VirtCtlGlsRfTntLvlPnl5Req "Virtual Control Glass Roof and Shade Information : Virtual Control Glass Roof Tint Level Panel 5 Request";
BA_ "SignalType" SG_ 1979 VirtCtlGlsRfTntLvlPnl4Req "ENM";
BA_ "SignalLongName" SG_ 1979 VirtCtlGlsRfTntLvlPnl4Req "Virtual Control Glass Roof and Shade Information : Virtual Control Glass Roof Tint Level Panel 4 Request";
BA_ "SignalType" SG_ 1979 VirtCtlGlsRfTntLvlPnl8Req "ENM";
BA_ "SignalLongName" SG_ 1979 VirtCtlGlsRfTntLvlPnl8Req "Virtual Control Glass Roof and Shade Information : Virtual Control Glass Roof Tint Level Panel 8 Request";
BA_ "SignalType" SG_ 1979 VirtCtlGlsRfTntLvlPnl7Req "ENM";
BA_ "SignalLongName" SG_ 1979 VirtCtlGlsRfTntLvlPnl7Req "Virtual Control Glass Roof and Shade Information : Virtual Control Glass Roof Tint Level Panel 7 Request";
BA_ "SignalType" SG_ 1979 VirtCtlPwrShdBkGlsReq "ENM";
BA_ "SignalLongName" SG_ 1979 VirtCtlPwrShdBkGlsReq "Virtual Control Glass Roof and Shade Information : Virtual Control Power Shades Back Glass Request";
BA_ "SignalType" SG_ 1979 VirtCtlGlsRfTntAutoSetReq "ENM";
BA_ "SignalLongName" SG_ 1979 VirtCtlGlsRfTntAutoSetReq "Virtual Control Glass Roof and Shade Information : Virtual Control Glass Roof Tint Automatic Setting Request";
BA_ "SignalType" SG_ 1979 VirtCtlGlsRfPwrShdPrvcyReqd "ENM";
BA_ "SignalLongName" SG_ 1979 VirtCtlGlsRfPwrShdPrvcyReqd "Virtual Control Glass Roof and Shade Information : Virtual Control Glass Roof and Power Shades Privacy Requested";
BA_ "SignalType" SG_ 1979 VirtCtlGlsRfTntLvlSldrReq "ENM";
BA_ "SignalLongName" SG_ 1979 VirtCtlGlsRfTntLvlSldrReq "Virtual Control Glass Roof and Shade Information : Virtual Control Glass Roof Tint Level Slider Request";
BA_ "SignalType" SG_ 1979 VirtCtlGlsRfTntReqd "ENM";
BA_ "SignalLongName" SG_ 1979 VirtCtlGlsRfTntReqd "Virtual Control Glass Roof and Shade Information : Virtual Control Glass Roof Tint Requested";
BA_ "SignalType" SG_ 1979 VirtCtlGlsRfDrkReqd "ENM";
BA_ "SignalLongName" SG_ 1979 VirtCtlGlsRfDrkReqd "Virtual Control Glass Roof and Shade Information : Virtual Control Glass Roof Dark Requested";
BA_ "SignalType" SG_ 1979 VirtCtlGlsRfClrReqd "ENM";
BA_ "SignalLongName" SG_ 1979 VirtCtlGlsRfClrReqd "Virtual Control Glass Roof and Shade Information : Virtual Control Glass Roof Clear Requested";
BA_ "SignalType" SG_ 1979 VirtCtlPwrShdRRReq "ENM";
BA_ "SignalLongName" SG_ 1979 VirtCtlPwrShdRRReq "Virtual Control Glass Roof and Shade Information : Virtual Control Power Shades Right Rear Request";
BA_ "SignalType" SG_ 1979 VirtCtlPwrShdLRReq "ENM";
BA_ "SignalLongName" SG_ 1979 VirtCtlPwrShdLRReq "Virtual Control Glass Roof and Shade Information : Virtual Control Power Shades Left Rear Request";
BA_ "SignalType" SG_ 1979 OtltsOffPwrModeTmrAddTmReq "ENM";
BA_ "SignalLongName" SG_ 1979 OtltsOffPwrModeTmrAddTmReq "Outlets Off Power Mode Timer Add Time Request";
BA_ "SignalType" SG_ 1979 OtltsOffPwrMdSysStopReq "ENM";
BA_ "SignalLongName" SG_ 1979 OtltsOffPwrMdSysStopReq "Outlets Off Power Mode System Stop Request";
BA_ "SignalLongName" SG_ 95 HiVltgChrgCtlPilotVltgGtd "Serial Data 276 : High Voltage Charging Control Pilot Voltage Gated";
BA_ "SignalLongName" SG_ 95 HiVltgChrgCtlPilotDCGtd "Serial Data 276 : High Voltage Charging Control Pilot Duty Cycle Gated";
BA_ "SignalType" SG_ 95 HiVltgChrgCtlPilotDCGtd_DuD "ENM";
BA_ "SignalLongName" SG_ 95 HiVltgChrgCtlPilotDCGtd_DuD "Serial Data 276 : High Voltage Charging Control Pilot Duty Cycle Gated Don't Use Data";
BA_ "SignalLongName" SG_ 95 HiVltgChrgCtlPilotPrdGtd "Serial Data 276 : High Voltage Charging Control Pilot Period Gated";
BA_ "SignalType" SG_ 95 HiVltgChrgCtlPilotVltgGtd_DuD "ENM";
BA_ "SignalLongName" SG_ 95 HiVltgChrgCtlPilotVltgGtd_DuD "Serial Data 276 : High Voltage Charging Control Pilot Voltage Gated Don't Use Data";
BA_ "SignalType" SG_ 95 HiVltgChrgCtlPilotPrdGtd_Inv "ENM";
BA_ "SignalLongName" SG_ 95 HiVltgChrgCtlPilotPrdGtd_Inv "Serial Data 276 : High Voltage Charging Control Pilot Period Gated Invalid";
BA_ "SignalType" SG_ 95 HiVltgChrgCtlPilotPrdGtd_DuD "ENM";
BA_ "SignalLongName" SG_ 95 HiVltgChrgCtlPilotPrdGtd_DuD "Serial Data 276 : High Voltage Charging Control Pilot Period Gated Don't Use Data";
BA_ "SignalType" SG_ 95 HiVltgChrgCtlPilotDCGtd_Inv "ENM";
BA_ "SignalLongName" SG_ 95 HiVltgChrgCtlPilotDCGtd_Inv "Serial Data 276 : High Voltage Charging Control Pilot Duty Cycle Gated Invalid";
BA_ "SignalType" SG_ 95 HiVltgChrgVntilationSwSts "ENM";
BA_ "SignalLongName" SG_ 95 HiVltgChrgVntilationSwSts "Serial Data 276 : High Voltage Charging Ventilation Switch Status";
BA_ "SignalType" SG_ 95 HiVltgChrgS2SwSts "ENM";
BA_ "SignalLongName" SG_ 95 HiVltgChrgS2SwSts "Serial Data 276 : High Voltage Charging S2 Switch Status";
BA_ "SignalLongName" SG_ 95 SD276_ARC "Serial Data 276 : Alive Rolling Count";
BA_ "SignalType" SG_ 95 HiVltgChrgCtlPilotVltgGtd_Inv "ENM";
BA_ "SignalLongName" SG_ 95 HiVltgChrgCtlPilotVltgGtd_Inv "Serial Data 276 : High Voltage Charging Control Pilot Voltage Gated Invalid";
BA_ "SignalType" SG_ 1936 ChrgStnCommActvReqd "ENM";
BA_ "SignalLongName" SG_ 1936 ChrgStnCommActvReqd "Charging Station Communication Active Requested";
BA_ "SignalLongName" SG_ 1992 SD297_ARC "Serial Data 297 : Alive Rolling Count";
BA_ "SignalType" SG_ 1992 EmsRltPrsnlMdSndCstChngSetReq "ENM";
BA_ "SignalLongName" SG_ 1992 EmsRltPrsnlMdSndCstChngSetReq "Serial Data 297 : Emissions Related Personal Mode Sound Customization Change Setting Request";
BA_ "SignalType" SG_ 1992 EmsRltCustMdSndCstChngSetReq "ENM";
BA_ "SignalLongName" SG_ 1992 EmsRltCustMdSndCstChngSetReq "Serial Data 297 : Emissions Related Custom Mode Sound Customization Change Setting Request";
BA_ "SignalType" SG_ 1992 EmsRltCustMdPTCstChngSetReq "ENM";
BA_ "SignalLongName" SG_ 1992 EmsRltCustMdPTCstChngSetReq "Serial Data 297 : Emissions Related Custom Mode Powertrain Customization Change Setting Request";
BA_ "SignalLongName" SG_ 1074 EnhdServsVehTopSpdLimRespVal "Enhanced Services Vehicle Top Speed Information : Enhanced Services Vehicle Top Speed Limit Response Value";
BA_ "SignalType" SG_ 1074 EnhdServsVehTopSpdLimRespTyp "ENM";
BA_ "SignalLongName" SG_ 1074 EnhdServsVehTopSpdLimRespTyp "Enhanced Services Vehicle Top Speed Information : Enhanced Services Vehicle Top Speed Limit Response Type";
BA_ "SignalType" SG_ 1074 PrplInhbWrnIndOn "ENM";
BA_ "SignalLongName" SG_ 1074 PrplInhbWrnIndOn "Propulsion Inhibit Warning Indication On";
BA_ "SignalLongName" SG_ 1993 VirtKeyPinToStrtRmnScrnSpcfcTm "Virtual Key Pin to Start Information : Virtual Key Pin To Start Remaining Screen Specific Time";
BA_ "SignalType" SG_ 1993 VirtKeyPinToStrtScrnReq "ENM";
BA_ "SignalLongName" SG_ 1993 VirtKeyPinToStrtScrnReq "Virtual Key Pin to Start Information : Virtual Key Pin To Start Screen Request";
BA_ "SignalType" SG_ 1993 VirtKeyPinToStrtPINLgth "ENM";
BA_ "SignalLongName" SG_ 1993 VirtKeyPinToStrtPINLgth "Virtual Key Pin to Start Information : Virtual Key Pin To Start PIN Length";
BA_ "SignalType" SG_ 1993 VirtKeyPinToStrtRmnAtmp "ENM";
BA_ "SignalLongName" SG_ 1993 VirtKeyPinToStrtRmnAtmp "Virtual Key Pin to Start Information : Virtual Key Pin To Start Remaining Attempts";
BA_ "SignalLongName" SG_ 1073 MFC_LCMDataAvlblChksum "Multi Function Controller - License Compliance Material Display Interface : License Complaince Material Data Available Check Sum";
BA_ "SignalLongName" SG_ 1073 MFC_LCMDataAvlblOwnID "Multi Function Controller - License Compliance Material Display Interface : License Complaince Material Data Available Owner ID";
BA_ "SignalLongName" SG_ 1073 MFC_LCMDataAvlblLicTag "Multi Function Controller - License Compliance Material Display Interface : License Complaince Material Data Available License Tag";
BA_ "SignalLongName" SG_ 1073 MFC_LCMDataAvlblTotBlks "Multi Function Controller - License Compliance Material Display Interface : License Complaince Material Data Available Total Blocks";
BA_ "SignalLongName" SG_ 939 LnFllwgTgtTrjctryLnCoef2 "Lane Following Target Trajectory Lane Coefficient 2";
BA_ "SignalLongName" SG_ 939 LnFllwgTgtTrjctryLnCoef3 "Lane Following Target Trajectory Lane Coefficient 3";
BA_ "SignalLongName" SG_ 939 LnFllwgTgtTrjctryLnCoef1 "Lane Following Target Trajectory Lane Coefficient 1";
BA_ "SignalLongName" SG_ 939 LnFllwgTgtTrjctryLnCoef0 "Lane Following Target Trajectory Lane Coefficient 0";
BA_ "SignalType" SG_ 1947 TrfcSgnMemCstSetAval "ENM";
BA_ "SignalLongName" SG_ 1947 TrfcSgnMemCstSetAval "Traffic Sign Memory Customization Setting Available";
BA_ "SignalType" SG_ 1947 TrfcSgnMemCstAvlFlg7 "ENM";
BA_ "SignalLongName" SG_ 1947 TrfcSgnMemCstAvlFlg7 "Traffic Sign Memory Customization Availability Flag 7";
BA_ "SignalType" SG_ 1947 TrfcSgnMemCstAvlFlg6 "ENM";
BA_ "SignalLongName" SG_ 1947 TrfcSgnMemCstAvlFlg6 "Traffic Sign Memory Customization Availability Flag 6";
BA_ "SignalType" SG_ 1947 TrfcSgnMemCstAvlFlg5 "ENM";
BA_ "SignalLongName" SG_ 1947 TrfcSgnMemCstAvlFlg5 "Traffic Sign Memory Customization Availability Flag 5";
BA_ "SignalType" SG_ 1947 TrfcSgnMemCstAvlFlg4 "ENM";
BA_ "SignalLongName" SG_ 1947 TrfcSgnMemCstAvlFlg4 "Traffic Sign Memory Customization Availability Flag 4";
BA_ "SignalType" SG_ 1947 TrfcSgnMemCstAvlFlg3 "ENM";
BA_ "SignalLongName" SG_ 1947 TrfcSgnMemCstAvlFlg3 "Traffic Sign Memory Customization Availability Flag 3";
BA_ "SignalType" SG_ 1947 TrfcSgnMemCstAvlFlg2 "ENM";
BA_ "SignalLongName" SG_ 1947 TrfcSgnMemCstAvlFlg2 "Traffic Sign Memory Customization Availability Flag 2";
BA_ "SignalType" SG_ 1947 TrfcSgnMemCstAvlFlg1 "ENM";
BA_ "SignalLongName" SG_ 1947 TrfcSgnMemCstAvlFlg1 "Traffic Sign Memory Customization Availability Flag 1";
BA_ "SignalType" SG_ 1947 TrfcSgnMemOvrspdChmCstAvlFlg7 "ENM";
BA_ "SignalLongName" SG_ 1947 TrfcSgnMemOvrspdChmCstAvlFlg7 "Traffic Sign Memory Overspeed Chime Customization Availability Flag 7";
BA_ "SignalType" SG_ 1947 TrfcSgnMemOvrspdChmCstAvlFlg6 "ENM";
BA_ "SignalLongName" SG_ 1947 TrfcSgnMemOvrspdChmCstAvlFlg6 "Traffic Sign Memory Overspeed Chime Customization Availability Flag 6";
BA_ "SignalType" SG_ 1947 TrfcSgnMemOvrspdChmCstAvlFlg5 "ENM";
BA_ "SignalLongName" SG_ 1947 TrfcSgnMemOvrspdChmCstAvlFlg5 "Traffic Sign Memory Overspeed Chime Customization Availability Flag 5";
BA_ "SignalType" SG_ 1947 TrfcSgnMemOvrspdChmCstAvlFlg4 "ENM";
BA_ "SignalLongName" SG_ 1947 TrfcSgnMemOvrspdChmCstAvlFlg4 "Traffic Sign Memory Overspeed Chime Customization Availability Flag 4";
BA_ "SignalType" SG_ 1947 TrfcSgnMemOvrspdChmCstAvlFlg3 "ENM";
BA_ "SignalLongName" SG_ 1947 TrfcSgnMemOvrspdChmCstAvlFlg3 "Traffic Sign Memory Overspeed Chime Customization Availability Flag 3";
BA_ "SignalType" SG_ 1947 TrfcSgnMemOvrspdChmCstAvlFlg2 "ENM";
BA_ "SignalLongName" SG_ 1947 TrfcSgnMemOvrspdChmCstAvlFlg2 "Traffic Sign Memory Overspeed Chime Customization Availability Flag 2";
BA_ "SignalType" SG_ 1947 TrfcSgnMemOvrspdChmCstAvlFlg1 "ENM";
BA_ "SignalLongName" SG_ 1947 TrfcSgnMemOvrspdChmCstAvlFlg1 "Traffic Sign Memory Overspeed Chime Customization Availability Flag 1";
BA_ "SignalType" SG_ 1947 TrfcSgnMemOfstEnbld "ENM";
BA_ "SignalLongName" SG_ 1947 TrfcSgnMemOfstEnbld "Traffic Sign Memory Offset Enabled";
BA_ "SignalType" SG_ 1947 TrfcSgnMemSpdLmChgChmCstAvlFlg7 "ENM";
BA_ "SignalLongName" SG_ 1947 TrfcSgnMemSpdLmChgChmCstAvlFlg7 "Traffic Sign Memory Speed Limit Change Chime Customization Availability Flag 7";
BA_ "SignalType" SG_ 1947 TrfcSgnMemSpdLmChgChmCstAvlFlg6 "ENM";
BA_ "SignalLongName" SG_ 1947 TrfcSgnMemSpdLmChgChmCstAvlFlg6 "Traffic Sign Memory Speed Limit Change Chime Customization Availability Flag 6";
BA_ "SignalType" SG_ 1947 TrfcSgnMemSpdLmChgChmCstAvlFlg5 "ENM";
BA_ "SignalLongName" SG_ 1947 TrfcSgnMemSpdLmChgChmCstAvlFlg5 "Traffic Sign Memory Speed Limit Change Chime Customization Availability Flag 5";
BA_ "SignalType" SG_ 1947 TrfcSgnMemSpdLmChgChmCstAvlFlg4 "ENM";
BA_ "SignalLongName" SG_ 1947 TrfcSgnMemSpdLmChgChmCstAvlFlg4 "Traffic Sign Memory Speed Limit Change Chime Customization Availability Flag 4";
BA_ "SignalType" SG_ 1947 TrfcSgnMemSpdLmChgChmCstAvlFlg3 "ENM";
BA_ "SignalLongName" SG_ 1947 TrfcSgnMemSpdLmChgChmCstAvlFlg3 "Traffic Sign Memory Speed Limit Change Chime Customization Availability Flag 3";
BA_ "SignalType" SG_ 1947 TrfcSgnMemSpdLmChgChmCstAvlFlg2 "ENM";
BA_ "SignalLongName" SG_ 1947 TrfcSgnMemSpdLmChgChmCstAvlFlg2 "Traffic Sign Memory Speed Limit Change Chime Customization Availability Flag 2";
BA_ "SignalType" SG_ 1947 TrfcSgnMemSpdLmChgChmCstAvlFlg1 "ENM";
BA_ "SignalLongName" SG_ 1947 TrfcSgnMemSpdLmChgChmCstAvlFlg1 "Traffic Sign Memory Speed Limit Change Chime Customization Availability Flag 1";
BA_ "SignalType" SG_ 1947 TrfcSgnMemOvrspdChmCstSetAval "ENM";
BA_ "SignalLongName" SG_ 1947 TrfcSgnMemOvrspdChmCstSetAval "Traffic Sign Memory Overspeed Chime Customization Setting Available";
BA_ "SignalType" SG_ 1947 TrfcSgnMemSpdLmChgChmCstSetAval "ENM";
BA_ "SignalLongName" SG_ 1947 TrfcSgnMemSpdLmChgChmCstSetAval "Traffic Sign Memory Speed Limit Change Chime Customization Setting Available";
BA_ "SignalType" SG_ 1118 TrfcSgnMemOvrspdChmCstChgSetReq "ENM";
BA_ "SignalLongName" SG_ 1118 TrfcSgnMemOvrspdChmCstChgSetReq "Traffic Sign Memory Overspeed Chime Customization Change Setting Request";
BA_ "SignalType" SG_ 1118 TrfcSgnMemCstChgSetReq "ENM";
BA_ "SignalLongName" SG_ 1118 TrfcSgnMemCstChgSetReq "Traffic Sign Memory Customization Change Setting Request";
BA_ "SignalType" SG_ 1118 TrfSgnMemSpdLmChgChmCstChgSetRq "ENM";
BA_ "SignalLongName" SG_ 1118 TrfSgnMemSpdLmChgChmCstChgSetRq "Traffic Sign Memory Speed Limit Change Chime Customization Change Setting Request";
BA_ "SignalType" SG_ 1119 TrfcSgnMemSgnChgChmEvntStat "ENM";
BA_ "SignalLongName" SG_ 1119 TrfcSgnMemSgnChgChmEvntStat "Traffic Sign Memory Sign Change Chime Event State";
BA_ "SignalType" SG_ 1119 TrfcSgnMemOvrspdChmEvntStat "ENM";
BA_ "SignalLongName" SG_ 1119 TrfcSgnMemOvrspdChmEvntStat "Traffic Sign Memory Overspeed Chime Event State";
BA_ "SignalType" SG_ 1948 TrfcSgnMemCstCurrSetVal "ENM";
BA_ "SignalLongName" SG_ 1948 TrfcSgnMemCstCurrSetVal "Traffic Sign Memory Customization Current Setting Value";
BA_ "SignalType" SG_ 1948 TrfSgnMemSpdLmChgChmCstCurSetVl "ENM";
BA_ "SignalLongName" SG_ 1948 TrfSgnMemSpdLmChgChmCstCurSetVl "Traffic Sign Memory Speed Limit Change Chime Customization Current Setting Value";
BA_ "SignalType" SG_ 1948 TrfSgnMemOvrspdChmCstCurrSetVal "ENM";
BA_ "SignalLongName" SG_ 1948 TrfSgnMemOvrspdChmCstCurrSetVal "Traffic Sign Memory Overspeed Chime Customization Current Setting Value";
BA_ "SignalType" SG_ 1948 TrfcSgnMemOvrspdWrnOffIndOn "ENM";
BA_ "SignalLongName" SG_ 1948 TrfcSgnMemOvrspdWrnOffIndOn "Traffic Sign Memory Overspeed Warning Off Indication On";
BA_ "SignalType" SG_ 1948 TrfcSgnMemDsbldIndOn "ENM";
BA_ "SignalLongName" SG_ 1948 TrfcSgnMemDsbldIndOn "Traffic Sign Memory Disabled Indication On";
BA_ "SignalType" SG_ 1192 AutDrvLckCstAvlFlg1 "ENM";
BA_ "SignalLongName" SG_ 1192 AutDrvLckCstAvlFlg1 "AutomaticDriveLockingCustomizationAvailabilityFlag1";
BA_ "SignalType" SG_ 1192 AirQltySnsCstAvlFlg7 "ENM";
BA_ "SignalLongName" SG_ 1192 AirQltySnsCstAvlFlg7 "Air Quality Sensor Customization Availability Flag 7";
BA_ "SignalType" SG_ 1192 AirQltySnsCstAvlFlg6 "ENM";
BA_ "SignalLongName" SG_ 1192 AirQltySnsCstAvlFlg6 "Air Quality Sensor Customization Availability Flag 6";
BA_ "SignalType" SG_ 1192 AirQltySnsCstAvlFlg5 "ENM";
BA_ "SignalLongName" SG_ 1192 AirQltySnsCstAvlFlg5 "Air Quality Sensor Customization Availability Flag 5";
BA_ "SignalType" SG_ 1192 AirQltySnsCstAvlFlg4 "ENM";
BA_ "SignalLongName" SG_ 1192 AirQltySnsCstAvlFlg4 "Air Quality Sensor Customization Availability Flag 4";
BA_ "SignalType" SG_ 1192 AirQltySnsCstAvlFlg3 "ENM";
BA_ "SignalLongName" SG_ 1192 AirQltySnsCstAvlFlg3 "Air Quality Sensor Customization Availability Flag 3";
BA_ "SignalType" SG_ 1192 AirQltySnsCstAvlFlg2 "ENM";
BA_ "SignalLongName" SG_ 1192 AirQltySnsCstAvlFlg2 "Air Quality Sensor Customization Availability Flag 2";
BA_ "SignalType" SG_ 1192 AirQltySnsCstAvlFlg1 "ENM";
BA_ "SignalLongName" SG_ 1192 AirQltySnsCstAvlFlg1 "Air Quality Sensor Customization Availability Flag 1";
BA_ "SignalType" SG_ 1192 AutMirFldCstAvlFlg2 "ENM";
BA_ "SignalLongName" SG_ 1192 AutMirFldCstAvlFlg2 "AutoMirrorFoldCustomizationAvailabilityFlag2";
BA_ "SignalType" SG_ 1192 AutMirFldCstAvlFlg1 "ENM";
BA_ "SignalLongName" SG_ 1192 AutMirFldCstAvlFlg1 "AutoMirrorFoldCustomizationAvailabilityFlag1";
BA_ "SignalType" SG_ 1192 AutDrvLckCstAvlFlg7 "ENM";
BA_ "SignalLongName" SG_ 1192 AutDrvLckCstAvlFlg7 "AutomaticDriveLockingCustomizationAvailabilityFlag7";
BA_ "SignalType" SG_ 1192 AutDrvLckCstAvlFlg6 "ENM";
BA_ "SignalLongName" SG_ 1192 AutDrvLckCstAvlFlg6 "AutomaticDriveLockingCustomizationAvailabilityFlag6";
BA_ "SignalType" SG_ 1192 AutDrvLckCstAvlFlg5 "ENM";
BA_ "SignalLongName" SG_ 1192 AutDrvLckCstAvlFlg5 "AutomaticDriveLockingCustomizationAvailabilityFlag5";
BA_ "SignalType" SG_ 1192 AutDrvLckCstAvlFlg4 "ENM";
BA_ "SignalLongName" SG_ 1192 AutDrvLckCstAvlFlg4 "AutomaticDriveLockingCustomizationAvailabilityFlag4";
BA_ "SignalType" SG_ 1192 AutDrvLckCstAvlFlg3 "ENM";
BA_ "SignalLongName" SG_ 1192 AutDrvLckCstAvlFlg3 "AutomaticDriveLockingCustomizationAvailabilityFlag3";
BA_ "SignalType" SG_ 1192 AutDrvLckCstAvlFlg2 "ENM";
BA_ "SignalLongName" SG_ 1192 AutDrvLckCstAvlFlg2 "AutomaticDriveLockingCustomizationAvailabilityFlag2";
BA_ "SignalType" SG_ 1192 AutoAirDstCstAvlFlg3 "ENM";
BA_ "SignalLongName" SG_ 1192 AutoAirDstCstAvlFlg3 "Automatic Air Distribution Customization Availability Flag 3";
BA_ "SignalType" SG_ 1192 AutoAirDstCstAvlFlg2 "ENM";
BA_ "SignalLongName" SG_ 1192 AutoAirDstCstAvlFlg2 "Automatic Air Distribution Customization Availability Flag 2";
BA_ "SignalType" SG_ 1192 AutoAirDstCstAvlFlg1 "ENM";
BA_ "SignalLongName" SG_ 1192 AutoAirDstCstAvlFlg1 "Automatic Air Distribution Customization Availability Flag 1";
BA_ "SignalType" SG_ 1192 AutMirFldCstAvlFlg7 "ENM";
BA_ "SignalLongName" SG_ 1192 AutMirFldCstAvlFlg7 "AutoMirrorFoldCustomizationAvailabilityFlag7";
BA_ "SignalType" SG_ 1192 AutMirFldCstAvlFlg6 "ENM";
BA_ "SignalLongName" SG_ 1192 AutMirFldCstAvlFlg6 "AutoMirrorFoldCustomizationAvailabilityFlag6";
BA_ "SignalType" SG_ 1192 AutMirFldCstAvlFlg5 "ENM";
BA_ "SignalLongName" SG_ 1192 AutMirFldCstAvlFlg5 "AutoMirrorFoldCustomizationAvailabilityFlag5";
BA_ "SignalType" SG_ 1192 AutMirFldCstAvlFlg4 "ENM";
BA_ "SignalLongName" SG_ 1192 AutMirFldCstAvlFlg4 "AutoMirrorFoldCustomizationAvailabilityFlag4";
BA_ "SignalType" SG_ 1192 AutMirFldCstAvlFlg3 "ENM";
BA_ "SignalLongName" SG_ 1192 AutMirFldCstAvlFlg3 "AutoMirrorFoldCustomizationAvailabilityFlag3";
BA_ "SignalType" SG_ 1192 AutoCoolStCstAvlFlg4 "ENM";
BA_ "SignalLongName" SG_ 1192 AutoCoolStCstAvlFlg4 "Automatic Cooled Seat Customization Availability Flag 4";
BA_ "SignalType" SG_ 1192 AutoCoolStCstAvlFlg3 "ENM";
BA_ "SignalLongName" SG_ 1192 AutoCoolStCstAvlFlg3 "Automatic Cooled Seat Customization Availability Flag 3";
BA_ "SignalType" SG_ 1192 AutoCoolStCstAvlFlg2 "ENM";
BA_ "SignalLongName" SG_ 1192 AutoCoolStCstAvlFlg2 "Automatic Cooled Seat Customization Availability Flag 2";
BA_ "SignalType" SG_ 1192 AutoCoolStCstAvlFlg1 "ENM";
BA_ "SignalLongName" SG_ 1192 AutoCoolStCstAvlFlg1 "Automatic Cooled Seat Customization Availability Flag 1";
BA_ "SignalType" SG_ 1192 AutoAirDstCstAvlFlg7 "ENM";
BA_ "SignalLongName" SG_ 1192 AutoAirDstCstAvlFlg7 "Automatic Air Distribution Customization Availability Flag 7";
BA_ "SignalType" SG_ 1192 AutoAirDstCstAvlFlg6 "ENM";
BA_ "SignalLongName" SG_ 1192 AutoAirDstCstAvlFlg6 "Automatic Air Distribution Customization Availability Flag 6";
BA_ "SignalType" SG_ 1192 AutoAirDstCstAvlFlg5 "ENM";
BA_ "SignalLongName" SG_ 1192 AutoAirDstCstAvlFlg5 "Automatic Air Distribution Customization Availability Flag 5";
BA_ "SignalType" SG_ 1192 AutoAirDstCstAvlFlg4 "ENM";
BA_ "SignalLongName" SG_ 1192 AutoAirDstCstAvlFlg4 "Automatic Air Distribution Customization Availability Flag 4";
BA_ "SignalType" SG_ 1192 AutoDfgCstAvlFlg5 "ENM";
BA_ "SignalLongName" SG_ 1192 AutoDfgCstAvlFlg5 "Automatic Defog Customization Availability Flag 5";
BA_ "SignalType" SG_ 1192 AutoDfgCstAvlFlg4 "ENM";
BA_ "SignalLongName" SG_ 1192 AutoDfgCstAvlFlg4 "Automatic Defog Customization Availability Flag 4";
BA_ "SignalType" SG_ 1192 AutoDfgCstAvlFlg3 "ENM";
BA_ "SignalLongName" SG_ 1192 AutoDfgCstAvlFlg3 "Automatic Defog Customization Availability Flag 3";
BA_ "SignalType" SG_ 1192 AutoDfgCstAvlFlg2 "ENM";
BA_ "SignalLongName" SG_ 1192 AutoDfgCstAvlFlg2 "Automatic Defog Customization Availability Flag 2";
BA_ "SignalType" SG_ 1192 AutoDfgCstAvlFlg1 "ENM";
BA_ "SignalLongName" SG_ 1192 AutoDfgCstAvlFlg1 "Automatic Defog Customization Availability Flag 1";
BA_ "SignalType" SG_ 1192 AutoCoolStCstAvlFlg7 "ENM";
BA_ "SignalLongName" SG_ 1192 AutoCoolStCstAvlFlg7 "Automatic Cooled Seat Customization Availability Flag 7";
BA_ "SignalType" SG_ 1192 AutoCoolStCstAvlFlg6 "ENM";
BA_ "SignalLongName" SG_ 1192 AutoCoolStCstAvlFlg6 "Automatic Cooled Seat Customization Availability Flag 6";
BA_ "SignalType" SG_ 1192 AutoCoolStCstAvlFlg5 "ENM";
BA_ "SignalLongName" SG_ 1192 AutoCoolStCstAvlFlg5 "Automatic Cooled Seat Customization Availability Flag 5";
BA_ "SignalType" SG_ 1192 AutoFanCstAvlFlg6 "ENM";
BA_ "SignalLongName" SG_ 1192 AutoFanCstAvlFlg6 "Automatic Fan Customization Availability Flag 6";
BA_ "SignalType" SG_ 1192 AutoFanCstAvlFlg5 "ENM";
BA_ "SignalLongName" SG_ 1192 AutoFanCstAvlFlg5 "Automatic Fan Customization Availability Flag 5";
BA_ "SignalType" SG_ 1192 AutoFanCstAvlFlg4 "ENM";
BA_ "SignalLongName" SG_ 1192 AutoFanCstAvlFlg4 "Automatic Fan Customization Availability Flag 4";
BA_ "SignalType" SG_ 1192 AutoFanCstAvlFlg3 "ENM";
BA_ "SignalLongName" SG_ 1192 AutoFanCstAvlFlg3 "Automatic Fan Customization Availability Flag 3";
BA_ "SignalType" SG_ 1192 AutoFanCstAvlFlg2 "ENM";
BA_ "SignalLongName" SG_ 1192 AutoFanCstAvlFlg2 "Automatic Fan Customization Availability Flag 2";
BA_ "SignalType" SG_ 1192 AutoFanCstAvlFlg1 "ENM";
BA_ "SignalLongName" SG_ 1192 AutoFanCstAvlFlg1 "Automatic Fan Customization Availability Flag 1";
BA_ "SignalType" SG_ 1192 AutoDfgCstAvlFlg7 "ENM";
BA_ "SignalLongName" SG_ 1192 AutoDfgCstAvlFlg7 "Automatic Defog Customization Availability Flag 7";
BA_ "SignalType" SG_ 1192 AutoDfgCstAvlFlg6 "ENM";
BA_ "SignalLongName" SG_ 1192 AutoDfgCstAvlFlg6 "Automatic Defog Customization Availability Flag 6";
BA_ "SignalType" SG_ 1192 AutoHtdStCstAvlFlg7 "ENM";
BA_ "SignalLongName" SG_ 1192 AutoHtdStCstAvlFlg7 "Automatic Heated Seat Customization Availability Flag 7";
BA_ "SignalType" SG_ 1192 AutoHtdStCstAvlFlg6 "ENM";
BA_ "SignalLongName" SG_ 1192 AutoHtdStCstAvlFlg6 "Automatic Heated Seat Customization Availability Flag 6";
BA_ "SignalType" SG_ 1192 AutoHtdStCstAvlFlg5 "ENM";
BA_ "SignalLongName" SG_ 1192 AutoHtdStCstAvlFlg5 "Automatic Heated Seat Customization Availability Flag 5";
BA_ "SignalType" SG_ 1192 AutoHtdStCstAvlFlg4 "ENM";
BA_ "SignalLongName" SG_ 1192 AutoHtdStCstAvlFlg4 "Automatic Heated Seat Customization Availability Flag 4";
BA_ "SignalType" SG_ 1192 AutoHtdStCstAvlFlg3 "ENM";
BA_ "SignalLongName" SG_ 1192 AutoHtdStCstAvlFlg3 "Automatic Heated Seat Customization Availability Flag 3";
BA_ "SignalType" SG_ 1192 AutoHtdStCstAvlFlg2 "ENM";
BA_ "SignalLongName" SG_ 1192 AutoHtdStCstAvlFlg2 "Automatic Heated Seat Customization Availability Flag 2";
BA_ "SignalType" SG_ 1192 AutoHtdStCstAvlFlg1 "ENM";
BA_ "SignalLongName" SG_ 1192 AutoHtdStCstAvlFlg1 "Automatic Heated Seat Customization Availability Flag 1";
BA_ "SignalType" SG_ 1192 AutoFanCstAvlFlg7 "ENM";
BA_ "SignalLongName" SG_ 1192 AutoFanCstAvlFlg7 "Automatic Fan Customization Availability Flag 7";
BA_ "SignalType" SG_ 1192 Aux1AmbtColrCtlCstAvlFlg87 "ENM";
BA_ "SignalLongName" SG_ 1192 Aux1AmbtColrCtlCstAvlFlg87 "Auxiliary 1 Ambient Color Control Customization Availability Flag 87";
BA_ "SignalType" SG_ 1192 AutoRrWpCstAvlFlg7 "ENM";
BA_ "SignalLongName" SG_ 1192 AutoRrWpCstAvlFlg7 "AutoRearWipeCustomizationAvailabilityFlag7";
BA_ "SignalType" SG_ 1192 AutoRrWpCstAvlFlg6 "ENM";
BA_ "SignalLongName" SG_ 1192 AutoRrWpCstAvlFlg6 "AutoRearWipeCustomizationAvailabilityFlag6";
BA_ "SignalType" SG_ 1192 AutoRrWpCstAvlFlg5 "ENM";
BA_ "SignalLongName" SG_ 1192 AutoRrWpCstAvlFlg5 "AutoRearWipeCustomizationAvailabilityFlag5";
BA_ "SignalType" SG_ 1192 AutoRrWpCstAvlFlg4 "ENM";
BA_ "SignalLongName" SG_ 1192 AutoRrWpCstAvlFlg4 "AutoRearWipeCustomizationAvailabilityFlag4";
BA_ "SignalType" SG_ 1192 AutoRrWpCstAvlFlg3 "ENM";
BA_ "SignalLongName" SG_ 1192 AutoRrWpCstAvlFlg3 "AutoRearWipeCustomizationAvailabilityFlag3";
BA_ "SignalType" SG_ 1192 AutoRrWpCstAvlFlg2 "ENM";
BA_ "SignalLongName" SG_ 1192 AutoRrWpCstAvlFlg2 "AutoRearWipeCustomizationAvailabilityFlag2";
BA_ "SignalType" SG_ 1192 AutoRrWpCstAvlFlg1 "ENM";
BA_ "SignalLongName" SG_ 1192 AutoRrWpCstAvlFlg1 "AutoRearWipeCustomizationAvailabilityFlag1";
BA_ "SignalType" SG_ 1874 Aux1AmbtAnmCtlCstAvlFlg1 "ENM";
BA_ "SignalLongName" SG_ 1874 Aux1AmbtAnmCtlCstAvlFlg1 "Auxiliary 1 Ambient Animation Control Customization Availability Flag 1";
BA_ "SignalType" SG_ 1874 AutUnlckCstAvlFlg7 "ENM";
BA_ "SignalLongName" SG_ 1874 AutUnlckCstAvlFlg7 "AutomaticUnlockingCustomizationAvailabilityFlag7";
BA_ "SignalType" SG_ 1874 AutUnlckCstAvlFlg6 "ENM";
BA_ "SignalLongName" SG_ 1874 AutUnlckCstAvlFlg6 "AutomaticUnlockingCustomizationAvailabilityFlag6";
BA_ "SignalType" SG_ 1874 AutUnlckCstAvlFlg5 "ENM";
BA_ "SignalLongName" SG_ 1874 AutUnlckCstAvlFlg5 "AutomaticUnlockingCustomizationAvailabilityFlag5";
BA_ "SignalType" SG_ 1874 AutUnlckCstAvlFlg4 "ENM";
BA_ "SignalLongName" SG_ 1874 AutUnlckCstAvlFlg4 "AutomaticUnlockingCustomizationAvailabilityFlag4";
BA_ "SignalType" SG_ 1874 AutUnlckCstAvlFlg3 "ENM";
BA_ "SignalLongName" SG_ 1874 AutUnlckCstAvlFlg3 "AutomaticUnlockingCustomizationAvailabilityFlag3";
BA_ "SignalType" SG_ 1874 AutUnlckCstAvlFlg2 "ENM";
BA_ "SignalLongName" SG_ 1874 AutUnlckCstAvlFlg2 "AutomaticUnlockingCustomizationAvailabilityFlag2";
BA_ "SignalType" SG_ 1874 AutUnlckCstAvlFlg1 "ENM";
BA_ "SignalLongName" SG_ 1874 AutUnlckCstAvlFlg1 "AutomaticUnlockingCustomizationAvailabilityFlag1";
BA_ "SignalType" SG_ 1874 Aux1AmbtAnmCtlCstAvlFlg3 "ENM";
BA_ "SignalLongName" SG_ 1874 Aux1AmbtAnmCtlCstAvlFlg3 "Auxiliary 1 Ambient Animation Control Customization Availability Flag 3";
BA_ "SignalType" SG_ 1874 Aux1AmbtAnmCtlCstAvlFlg2 "ENM";
BA_ "SignalLongName" SG_ 1874 Aux1AmbtAnmCtlCstAvlFlg2 "Auxiliary 1 Ambient Animation Control Customization Availability Flag 2";
BA_ "SignalType" SG_ 1874 Aux1AmbtAnmCtlCstAvlFlg15 "ENM";
BA_ "SignalLongName" SG_ 1874 Aux1AmbtAnmCtlCstAvlFlg15 "Auxiliary 1 Ambient Animation Control Customization Availability Flag 15";
BA_ "SignalType" SG_ 1874 Aux1AmbtAnmCtlCstAvlFlg14 "ENM";
BA_ "SignalLongName" SG_ 1874 Aux1AmbtAnmCtlCstAvlFlg14 "Auxiliary 1 Ambient Animation Control Customization Availability Flag 14";
BA_ "SignalType" SG_ 1874 Aux1AmbtAnmCtlCstAvlFlg13 "ENM";
BA_ "SignalLongName" SG_ 1874 Aux1AmbtAnmCtlCstAvlFlg13 "Auxiliary 1 Ambient Animation Control Customization Availability Flag 13";
BA_ "SignalType" SG_ 1874 Aux1AmbtAnmCtlCstAvlFlg12 "ENM";
BA_ "SignalLongName" SG_ 1874 Aux1AmbtAnmCtlCstAvlFlg12 "Auxiliary 1 Ambient Animation Control Customization Availability Flag 12";
BA_ "SignalType" SG_ 1874 Aux1AmbtAnmCtlCstAvlFlg11 "ENM";
BA_ "SignalLongName" SG_ 1874 Aux1AmbtAnmCtlCstAvlFlg11 "Auxiliary 1 Ambient Animation Control Customization Availability Flag 11";
BA_ "SignalType" SG_ 1874 Aux1AmbtAnmCtlCstAvlFlg10 "ENM";
BA_ "SignalLongName" SG_ 1874 Aux1AmbtAnmCtlCstAvlFlg10 "Auxiliary 1 Ambient Animation Control Customization Availability Flag 10";
BA_ "SignalType" SG_ 1874 Aux1AmbtBrghtnsCtlCstAvlFlg1 "ENM";
BA_ "SignalLongName" SG_ 1874 Aux1AmbtBrghtnsCtlCstAvlFlg1 "Auxiliary 1 Ambient Brightness Control Customization Availability Flag 1";
BA_ "SignalType" SG_ 1874 Aux1AmbtAnmCtlCstSetAval "ENM";
BA_ "SignalLongName" SG_ 1874 Aux1AmbtAnmCtlCstSetAval "Auxiliary 1 Ambient Animation Control Customization Setting Available";
BA_ "SignalType" SG_ 1874 Aux1AmbtAnmCtlCstAvlFlg9 "ENM";
BA_ "SignalLongName" SG_ 1874 Aux1AmbtAnmCtlCstAvlFlg9 "Auxiliary 1 Ambient Animation Control Customization Availability Flag 9";
BA_ "SignalType" SG_ 1874 Aux1AmbtAnmCtlCstAvlFlg8 "ENM";
BA_ "SignalLongName" SG_ 1874 Aux1AmbtAnmCtlCstAvlFlg8 "Auxiliary 1 Ambient Animation Control Customization Availability Flag 8";
BA_ "SignalType" SG_ 1874 Aux1AmbtAnmCtlCstAvlFlg7 "ENM";
BA_ "SignalLongName" SG_ 1874 Aux1AmbtAnmCtlCstAvlFlg7 "Auxiliary 1 Ambient Animation Control Customization Availability Flag 7";
BA_ "SignalType" SG_ 1874 Aux1AmbtAnmCtlCstAvlFlg6 "ENM";
BA_ "SignalLongName" SG_ 1874 Aux1AmbtAnmCtlCstAvlFlg6 "Auxiliary 1 Ambient Animation Control Customization Availability Flag 6";
BA_ "SignalType" SG_ 1874 Aux1AmbtAnmCtlCstAvlFlg5 "ENM";
BA_ "SignalLongName" SG_ 1874 Aux1AmbtAnmCtlCstAvlFlg5 "Auxiliary 1 Ambient Animation Control Customization Availability Flag 5";
BA_ "SignalType" SG_ 1874 Aux1AmbtAnmCtlCstAvlFlg4 "ENM";
BA_ "SignalLongName" SG_ 1874 Aux1AmbtAnmCtlCstAvlFlg4 "Auxiliary 1 Ambient Animation Control Customization Availability Flag 4";
BA_ "SignalType" SG_ 1874 Aux1AmbtColrCtlCstAvlFlg1 "ENM";
BA_ "SignalLongName" SG_ 1874 Aux1AmbtColrCtlCstAvlFlg1 "Auxiliary 1 Ambient Color Control Customization Availability Flag 1";
BA_ "SignalType" SG_ 1874 Aux1AmbtBrghtnsCtlCstSetAval "ENM";
BA_ "SignalLongName" SG_ 1874 Aux1AmbtBrghtnsCtlCstSetAval "Auxiliary 1 Ambient Brightness Control Customization Setting Available";
BA_ "SignalType" SG_ 1874 Aux1AmbtBrghtnsCtlCstAvlFlg7 "ENM";
BA_ "SignalLongName" SG_ 1874 Aux1AmbtBrghtnsCtlCstAvlFlg7 "Auxiliary 1 Ambient Brightness Control Customization Availability Flag 7";
BA_ "SignalType" SG_ 1874 Aux1AmbtBrghtnsCtlCstAvlFlg6 "ENM";
BA_ "SignalLongName" SG_ 1874 Aux1AmbtBrghtnsCtlCstAvlFlg6 "Auxiliary 1 Ambient Brightness Control Customization Availability Flag 6";
BA_ "SignalType" SG_ 1874 Aux1AmbtBrghtnsCtlCstAvlFlg5 "ENM";
BA_ "SignalLongName" SG_ 1874 Aux1AmbtBrghtnsCtlCstAvlFlg5 "Auxiliary 1 Ambient Brightness Control Customization Availability Flag 5";
BA_ "SignalType" SG_ 1874 Aux1AmbtBrghtnsCtlCstAvlFlg4 "ENM";
BA_ "SignalLongName" SG_ 1874 Aux1AmbtBrghtnsCtlCstAvlFlg4 "Auxiliary 1 Ambient Brightness Control Customization Availability Flag 4";
BA_ "SignalType" SG_ 1874 Aux1AmbtBrghtnsCtlCstAvlFlg3 "ENM";
BA_ "SignalLongName" SG_ 1874 Aux1AmbtBrghtnsCtlCstAvlFlg3 "Auxiliary 1 Ambient Brightness Control Customization Availability Flag 3";
BA_ "SignalType" SG_ 1874 Aux1AmbtBrghtnsCtlCstAvlFlg2 "ENM";
BA_ "SignalLongName" SG_ 1874 Aux1AmbtBrghtnsCtlCstAvlFlg2 "Auxiliary 1 Ambient Brightness Control Customization Availability Flag 2";
BA_ "SignalType" SG_ 1874 Aux1AmbtColrCtlCstAvlFlg17 "ENM";
BA_ "SignalLongName" SG_ 1874 Aux1AmbtColrCtlCstAvlFlg17 "Auxiliary 1 Ambient Color Control Customization Availability Flag 17";
BA_ "SignalType" SG_ 1874 Aux1AmbtColrCtlCstAvlFlg16 "ENM";
BA_ "SignalLongName" SG_ 1874 Aux1AmbtColrCtlCstAvlFlg16 "Auxiliary 1 Ambient Color Control Customization Availability Flag 16";
BA_ "SignalType" SG_ 1874 Aux1AmbtColrCtlCstAvlFlg15 "ENM";
BA_ "SignalLongName" SG_ 1874 Aux1AmbtColrCtlCstAvlFlg15 "Auxiliary 1 Ambient Color Control Customization Availability Flag 15";
BA_ "SignalType" SG_ 1874 Aux1AmbtColrCtlCstAvlFlg14 "ENM";
BA_ "SignalLongName" SG_ 1874 Aux1AmbtColrCtlCstAvlFlg14 "Auxiliary 1 Ambient Color Control Customization Availability Flag 14";
BA_ "SignalType" SG_ 1874 Aux1AmbtColrCtlCstAvlFlg13 "ENM";
BA_ "SignalLongName" SG_ 1874 Aux1AmbtColrCtlCstAvlFlg13 "Auxiliary 1 Ambient Color Control Customization Availability Flag 13";
BA_ "SignalType" SG_ 1874 Aux1AmbtColrCtlCstAvlFlg12 "ENM";
BA_ "SignalLongName" SG_ 1874 Aux1AmbtColrCtlCstAvlFlg12 "Auxiliary 1 Ambient Color Control Customization Availability Flag 12";
BA_ "SignalType" SG_ 1874 Aux1AmbtColrCtlCstAvlFlg11 "ENM";
BA_ "SignalLongName" SG_ 1874 Aux1AmbtColrCtlCstAvlFlg11 "Auxiliary 1 Ambient Color Control Customization Availability Flag 11";
BA_ "SignalType" SG_ 1874 Aux1AmbtColrCtlCstAvlFlg10 "ENM";
BA_ "SignalLongName" SG_ 1874 Aux1AmbtColrCtlCstAvlFlg10 "Auxiliary 1 Ambient Color Control Customization Availability Flag 10";
BA_ "SignalType" SG_ 1874 Aux1AmbtColrCtlCstAvlFlg24 "ENM";
BA_ "SignalLongName" SG_ 1874 Aux1AmbtColrCtlCstAvlFlg24 "Auxiliary 1 Ambient Color Control Customization Availability Flag 24";
BA_ "SignalType" SG_ 1874 Aux1AmbtColrCtlCstAvlFlg23 "ENM";
BA_ "SignalLongName" SG_ 1874 Aux1AmbtColrCtlCstAvlFlg23 "Auxiliary 1 Ambient Color Control Customization Availability Flag 23";
BA_ "SignalType" SG_ 1874 Aux1AmbtColrCtlCstAvlFlg22 "ENM";
BA_ "SignalLongName" SG_ 1874 Aux1AmbtColrCtlCstAvlFlg22 "Auxiliary 1 Ambient Color Control Customization Availability Flag 22";
BA_ "SignalType" SG_ 1874 Aux1AmbtColrCtlCstAvlFlg21 "ENM";
BA_ "SignalLongName" SG_ 1874 Aux1AmbtColrCtlCstAvlFlg21 "Auxiliary 1 Ambient Color Control Customization Availability Flag 21";
BA_ "SignalType" SG_ 1874 Aux1AmbtColrCtlCstAvlFlg20 "ENM";
BA_ "SignalLongName" SG_ 1874 Aux1AmbtColrCtlCstAvlFlg20 "Auxiliary 1 Ambient Color Control Customization Availability Flag 20";
BA_ "SignalType" SG_ 1874 Aux1AmbtColrCtlCstAvlFlg2 "ENM";
BA_ "SignalLongName" SG_ 1874 Aux1AmbtColrCtlCstAvlFlg2 "Auxiliary 1 Ambient Color Control Customization Availability Flag 2";
BA_ "SignalType" SG_ 1874 Aux1AmbtColrCtlCstAvlFlg19 "ENM";
BA_ "SignalLongName" SG_ 1874 Aux1AmbtColrCtlCstAvlFlg19 "Auxiliary 1 Ambient Color Control Customization Availability Flag 19";
BA_ "SignalType" SG_ 1874 Aux1AmbtColrCtlCstAvlFlg18 "ENM";
BA_ "SignalLongName" SG_ 1874 Aux1AmbtColrCtlCstAvlFlg18 "Auxiliary 1 Ambient Color Control Customization Availability Flag 18";
BA_ "SignalType" SG_ 1874 Aux1AmbtColrCtlCstAvlFlg31 "ENM";
BA_ "SignalLongName" SG_ 1874 Aux1AmbtColrCtlCstAvlFlg31 "Auxiliary 1 Ambient Color Control Customization Availability Flag 31";
BA_ "SignalType" SG_ 1874 Aux1AmbtColrCtlCstAvlFlg30 "ENM";
BA_ "SignalLongName" SG_ 1874 Aux1AmbtColrCtlCstAvlFlg30 "Auxiliary 1 Ambient Color Control Customization Availability Flag 30";
BA_ "SignalType" SG_ 1874 Aux1AmbtColrCtlCstAvlFlg3 "ENM";
BA_ "SignalLongName" SG_ 1874 Aux1AmbtColrCtlCstAvlFlg3 "Auxiliary 1 Ambient Color Control Customization Availability Flag 3";
BA_ "SignalType" SG_ 1874 Aux1AmbtColrCtlCstAvlFlg29 "ENM";
BA_ "SignalLongName" SG_ 1874 Aux1AmbtColrCtlCstAvlFlg29 "Auxiliary 1 Ambient Color Control Customization Availability Flag 29";
BA_ "SignalType" SG_ 1874 Aux1AmbtColrCtlCstAvlFlg28 "ENM";
BA_ "SignalLongName" SG_ 1874 Aux1AmbtColrCtlCstAvlFlg28 "Auxiliary 1 Ambient Color Control Customization Availability Flag 28";
BA_ "SignalType" SG_ 1874 Aux1AmbtColrCtlCstAvlFlg27 "ENM";
BA_ "SignalLongName" SG_ 1874 Aux1AmbtColrCtlCstAvlFlg27 "Auxiliary 1 Ambient Color Control Customization Availability Flag 27";
BA_ "SignalType" SG_ 1874 Aux1AmbtColrCtlCstAvlFlg26 "ENM";
BA_ "SignalLongName" SG_ 1874 Aux1AmbtColrCtlCstAvlFlg26 "Auxiliary 1 Ambient Color Control Customization Availability Flag 26";
BA_ "SignalType" SG_ 1874 Aux1AmbtColrCtlCstAvlFlg25 "ENM";
BA_ "SignalLongName" SG_ 1874 Aux1AmbtColrCtlCstAvlFlg25 "Auxiliary 1 Ambient Color Control Customization Availability Flag 25";
BA_ "SignalType" SG_ 1874 Aux1AmbtColrCtlCstAvlFlg88 "ENM";
BA_ "SignalLongName" SG_ 1874 Aux1AmbtColrCtlCstAvlFlg88 "Auxiliary 1 Ambient Color Control Customization Availability Flag 88";
BA_ "SignalType" SG_ 1874 Aux1AmbtColrCtlCstSetAval "ENM";
BA_ "SignalLongName" SG_ 1874 Aux1AmbtColrCtlCstSetAval "Auxiliary 1 Ambient Color Control Customization Setting Available";
BA_ "SignalType" SG_ 1874 Aux1AmbtColrCtlCstAvlFlg9 "ENM";
BA_ "SignalLongName" SG_ 1874 Aux1AmbtColrCtlCstAvlFlg9 "Auxiliary 1 Ambient Color Control Customization Availability Flag 9";
BA_ "SignalType" SG_ 1874 Aux1AmbtColrCtlCstAvlFlg8 "ENM";
BA_ "SignalLongName" SG_ 1874 Aux1AmbtColrCtlCstAvlFlg8 "Auxiliary 1 Ambient Color Control Customization Availability Flag 8";
BA_ "SignalType" SG_ 1874 Aux1AmbtColrCtlCstAvlFlg7 "ENM";
BA_ "SignalLongName" SG_ 1874 Aux1AmbtColrCtlCstAvlFlg7 "Auxiliary 1 Ambient Color Control Customization Availability Flag 7";
BA_ "SignalType" SG_ 1874 Aux1AmbtColrCtlCstAvlFlg6 "ENM";
BA_ "SignalLongName" SG_ 1874 Aux1AmbtColrCtlCstAvlFlg6 "Auxiliary 1 Ambient Color Control Customization Availability Flag 6";
BA_ "SignalType" SG_ 1874 Aux1AmbtColrCtlCstAvlFlg5 "ENM";
BA_ "SignalLongName" SG_ 1874 Aux1AmbtColrCtlCstAvlFlg5 "Auxiliary 1 Ambient Color Control Customization Availability Flag 5";
BA_ "SignalType" SG_ 1874 Aux1AmbtColrCtlCstAvlFlg4 "ENM";
BA_ "SignalLongName" SG_ 1874 Aux1AmbtColrCtlCstAvlFlg4 "Auxiliary 1 Ambient Color Control Customization Availability Flag 4";
BA_ "SignalType" SG_ 1191 HndsFrStrgeAccssCstCfg "ENM";
BA_ "SignalLongName" SG_ 1191 HndsFrStrgeAccssCstCfg "Hands Free Storage Access Customization Configuration";
BA_ "SignalType" SG_ 1191 DaytimeTlLghtsCstAvlFlg7 "ENM";
BA_ "SignalLongName" SG_ 1191 DaytimeTlLghtsCstAvlFlg7 "DaytimeTailLightsCustomizationAvailabilityFlag7";
BA_ "SignalType" SG_ 1191 DaytimeTlLghtsCstAvlFlg6 "ENM";
BA_ "SignalLongName" SG_ 1191 DaytimeTlLghtsCstAvlFlg6 "DaytimeTailLightsCustomizationAvailabilityFlag6";
BA_ "SignalType" SG_ 1191 DaytimeTlLghtsCstAvlFlg5 "ENM";
BA_ "SignalLongName" SG_ 1191 DaytimeTlLghtsCstAvlFlg5 "DaytimeTailLightsCustomizationAvailabilityFlag5";
BA_ "SignalType" SG_ 1191 DaytimeTlLghtsCstAvlFlg4 "ENM";
BA_ "SignalLongName" SG_ 1191 DaytimeTlLghtsCstAvlFlg4 "DaytimeTailLightsCustomizationAvailabilityFlag4";
BA_ "SignalType" SG_ 1191 DaytimeTlLghtsCstAvlFlg3 "ENM";
BA_ "SignalLongName" SG_ 1191 DaytimeTlLghtsCstAvlFlg3 "DaytimeTailLightsCustomizationAvailabilityFlag3";
BA_ "SignalType" SG_ 1191 DaytimeTlLghtsCstAvlFlg2 "ENM";
BA_ "SignalLongName" SG_ 1191 DaytimeTlLghtsCstAvlFlg2 "DaytimeTailLightsCustomizationAvailabilityFlag2";
BA_ "SignalType" SG_ 1191 DaytimeTlLghtsCstAvlFlg1 "ENM";
BA_ "SignalLongName" SG_ 1191 DaytimeTlLghtsCstAvlFlg1 "DaytimeTailLightsCustomizationAvailabilityFlag1";
BA_ "SignalType" SG_ 1191 HFRCCstAvlFlg1 "ENM";
BA_ "SignalLongName" SG_ 1191 HFRCCstAvlFlg1 "HandsFreeRearClosureCustomizationAvailabilityFlag1";
BA_ "SignalType" SG_ 1191 ExtLghtCstAvlFlg7 "ENM";
BA_ "SignalLongName" SG_ 1191 ExtLghtCstAvlFlg7 "Exit Lighting CustomizationAvailabilityFlag7";
BA_ "SignalType" SG_ 1191 ExtLghtCstAvlFlg6 "ENM";
BA_ "SignalLongName" SG_ 1191 ExtLghtCstAvlFlg6 "Exit Lighting CustomizationAvailabilityFlag6";
BA_ "SignalType" SG_ 1191 ExtLghtCstAvlFlg5 "ENM";
BA_ "SignalLongName" SG_ 1191 ExtLghtCstAvlFlg5 "Exit Lighting CustomizationAvailabilityFlag5";
BA_ "SignalType" SG_ 1191 ExtLghtCstAvlFlg4 "ENM";
BA_ "SignalLongName" SG_ 1191 ExtLghtCstAvlFlg4 "Exit Lighting CustomizationAvailabilityFlag4";
BA_ "SignalType" SG_ 1191 ExtLghtCstAvlFlg3 "ENM";
BA_ "SignalLongName" SG_ 1191 ExtLghtCstAvlFlg3 "Exit Lighting CustomizationAvailabilityFlag3";
BA_ "SignalType" SG_ 1191 ExtLghtCstAvlFlg2 "ENM";
BA_ "SignalLongName" SG_ 1191 ExtLghtCstAvlFlg2 "Exit Lighting CustomizationAvailabilityFlag2";
BA_ "SignalType" SG_ 1191 ExtLghtCstAvlFlg1 "ENM";
BA_ "SignalLongName" SG_ 1191 ExtLghtCstAvlFlg1 "Exit Lighting CustomizationAvailabilityFlag1";
BA_ "SignalType" SG_ 1191 IntrAmbtAnmCtlCstAvlFlg10 "ENM";
BA_ "SignalLongName" SG_ 1191 IntrAmbtAnmCtlCstAvlFlg10 "Interior Ambient Animation Control Customization Availability Flag 10";
BA_ "SignalType" SG_ 1191 IntrAmbtAnmCtlCstAvlFlg1 "ENM";
BA_ "SignalLongName" SG_ 1191 IntrAmbtAnmCtlCstAvlFlg1 "Interior Ambient Animation Control Customization Availability Flag 1";
BA_ "SignalType" SG_ 1191 HFRCCstAvlFlg7 "ENM";
BA_ "SignalLongName" SG_ 1191 HFRCCstAvlFlg7 "HandsFreeRearClosureCustomizationAvailabilityFlag7";
BA_ "SignalType" SG_ 1191 HFRCCstAvlFlg6 "ENM";
BA_ "SignalLongName" SG_ 1191 HFRCCstAvlFlg6 "HandsFreeRearClosureCustomizationAvailabilityFlag6";
BA_ "SignalType" SG_ 1191 HFRCCstAvlFlg5 "ENM";
BA_ "SignalLongName" SG_ 1191 HFRCCstAvlFlg5 "HandsFreeRearClosureCustomizationAvailabilityFlag5";
BA_ "SignalType" SG_ 1191 HFRCCstAvlFlg4 "ENM";
BA_ "SignalLongName" SG_ 1191 HFRCCstAvlFlg4 "HandsFreeRearClosureCustomizationAvailabilityFlag4";
BA_ "SignalType" SG_ 1191 HFRCCstAvlFlg3 "ENM";
BA_ "SignalLongName" SG_ 1191 HFRCCstAvlFlg3 "HandsFreeRearClosureCustomizationAvailabilityFlag3";
BA_ "SignalType" SG_ 1191 HFRCCstAvlFlg2 "ENM";
BA_ "SignalLongName" SG_ 1191 HFRCCstAvlFlg2 "HandsFreeRearClosureCustomizationAvailabilityFlag2";
BA_ "SignalType" SG_ 1191 IntrAmbtAnmCtlCstAvlFlg4 "ENM";
BA_ "SignalLongName" SG_ 1191 IntrAmbtAnmCtlCstAvlFlg4 "Interior Ambient Animation Control Customization Availability Flag 4";
BA_ "SignalType" SG_ 1191 IntrAmbtAnmCtlCstAvlFlg3 "ENM";
BA_ "SignalLongName" SG_ 1191 IntrAmbtAnmCtlCstAvlFlg3 "Interior Ambient Animation Control Customization Availability Flag 3";
BA_ "SignalType" SG_ 1191 IntrAmbtAnmCtlCstAvlFlg2 "ENM";
BA_ "SignalLongName" SG_ 1191 IntrAmbtAnmCtlCstAvlFlg2 "Interior Ambient Animation Control Customization Availability Flag 2";
BA_ "SignalType" SG_ 1191 IntrAmbtAnmCtlCstAvlFlg15 "ENM";
BA_ "SignalLongName" SG_ 1191 IntrAmbtAnmCtlCstAvlFlg15 "Interior Ambient Animation Control Customization Availability Flag 15";
BA_ "SignalType" SG_ 1191 IntrAmbtAnmCtlCstAvlFlg14 "ENM";
BA_ "SignalLongName" SG_ 1191 IntrAmbtAnmCtlCstAvlFlg14 "Interior Ambient Animation Control Customization Availability Flag 14";
BA_ "SignalType" SG_ 1191 IntrAmbtAnmCtlCstAvlFlg13 "ENM";
BA_ "SignalLongName" SG_ 1191 IntrAmbtAnmCtlCstAvlFlg13 "Interior Ambient Animation Control Customization Availability Flag 13";
BA_ "SignalType" SG_ 1191 IntrAmbtAnmCtlCstAvlFlg12 "ENM";
BA_ "SignalLongName" SG_ 1191 IntrAmbtAnmCtlCstAvlFlg12 "Interior Ambient Animation Control Customization Availability Flag 12";
BA_ "SignalType" SG_ 1191 IntrAmbtAnmCtlCstAvlFlg11 "ENM";
BA_ "SignalLongName" SG_ 1191 IntrAmbtAnmCtlCstAvlFlg11 "Interior Ambient Animation Control Customization Availability Flag 11";
BA_ "SignalType" SG_ 1191 IntrAmbtBrghtnsCtlCstAvlFlg2 "ENM";
BA_ "SignalLongName" SG_ 1191 IntrAmbtBrghtnsCtlCstAvlFlg2 "Interior Ambient Brightness Control Customization Availability Flag 2";
BA_ "SignalType" SG_ 1191 IntrAmbtBrghtnsCtlCstAvlFlg1 "ENM";
BA_ "SignalLongName" SG_ 1191 IntrAmbtBrghtnsCtlCstAvlFlg1 "Interior Ambient Brightness Control Customization Availability Flag 1";
BA_ "SignalType" SG_ 1191 IntrAmbtAnmCtlCstSetAval "ENM";
BA_ "SignalLongName" SG_ 1191 IntrAmbtAnmCtlCstSetAval "Interior Ambient Animation Control Customization Setting Available";
BA_ "SignalType" SG_ 1191 IntrAmbtAnmCtlCstAvlFlg9 "ENM";
BA_ "SignalLongName" SG_ 1191 IntrAmbtAnmCtlCstAvlFlg9 "Interior Ambient Animation Control Customization Availability Flag 9";
BA_ "SignalType" SG_ 1191 IntrAmbtAnmCtlCstAvlFlg8 "ENM";
BA_ "SignalLongName" SG_ 1191 IntrAmbtAnmCtlCstAvlFlg8 "Interior Ambient Animation Control Customization Availability Flag 8";
BA_ "SignalType" SG_ 1191 IntrAmbtAnmCtlCstAvlFlg7 "ENM";
BA_ "SignalLongName" SG_ 1191 IntrAmbtAnmCtlCstAvlFlg7 "Interior Ambient Animation Control Customization Availability Flag 7";
BA_ "SignalType" SG_ 1191 IntrAmbtAnmCtlCstAvlFlg6 "ENM";
BA_ "SignalLongName" SG_ 1191 IntrAmbtAnmCtlCstAvlFlg6 "Interior Ambient Animation Control Customization Availability Flag 6";
BA_ "SignalType" SG_ 1191 IntrAmbtAnmCtlCstAvlFlg5 "ENM";
BA_ "SignalLongName" SG_ 1191 IntrAmbtAnmCtlCstAvlFlg5 "Interior Ambient Animation Control Customization Availability Flag 5";
BA_ "SignalType" SG_ 1191 Aux1AmbtColrCtlCstAvlFlg75 "ENM";
BA_ "SignalLongName" SG_ 1191 Aux1AmbtColrCtlCstAvlFlg75 "Auxiliary 1 Ambient Color Control Customization Availability Flag 75";
BA_ "SignalType" SG_ 1191 Aux1AmbtColrCtlCstAvlFlg74 "ENM";
BA_ "SignalLongName" SG_ 1191 Aux1AmbtColrCtlCstAvlFlg74 "Auxiliary 1 Ambient Color Control Customization Availability Flag 74";
BA_ "SignalType" SG_ 1191 IntrAmbtBrghtnsCtlCstSetAval "ENM";
BA_ "SignalLongName" SG_ 1191 IntrAmbtBrghtnsCtlCstSetAval "Interior Ambient Brightness Control Customization Setting Available";
BA_ "SignalType" SG_ 1191 IntrAmbtBrghtnsCtlCstAvlFlg7 "ENM";
BA_ "SignalLongName" SG_ 1191 IntrAmbtBrghtnsCtlCstAvlFlg7 "Interior Ambient Brightness Control Customization Availability Flag 7";
BA_ "SignalType" SG_ 1191 IntrAmbtBrghtnsCtlCstAvlFlg6 "ENM";
BA_ "SignalLongName" SG_ 1191 IntrAmbtBrghtnsCtlCstAvlFlg6 "Interior Ambient Brightness Control Customization Availability Flag 6";
BA_ "SignalType" SG_ 1191 IntrAmbtBrghtnsCtlCstAvlFlg5 "ENM";
BA_ "SignalLongName" SG_ 1191 IntrAmbtBrghtnsCtlCstAvlFlg5 "Interior Ambient Brightness Control Customization Availability Flag 5";
BA_ "SignalType" SG_ 1191 IntrAmbtBrghtnsCtlCstAvlFlg4 "ENM";
BA_ "SignalLongName" SG_ 1191 IntrAmbtBrghtnsCtlCstAvlFlg4 "Interior Ambient Brightness Control Customization Availability Flag 4";
BA_ "SignalType" SG_ 1191 IntrAmbtBrghtnsCtlCstAvlFlg3 "ENM";
BA_ "SignalLongName" SG_ 1191 IntrAmbtBrghtnsCtlCstAvlFlg3 "Interior Ambient Brightness Control Customization Availability Flag 3";
BA_ "SignalType" SG_ 1191 Aux1AmbtColrCtlCstAvlFlg83 "ENM";
BA_ "SignalLongName" SG_ 1191 Aux1AmbtColrCtlCstAvlFlg83 "Auxiliary 1 Ambient Color Control Customization Availability Flag 83";
BA_ "SignalType" SG_ 1191 Aux1AmbtColrCtlCstAvlFlg82 "ENM";
BA_ "SignalLongName" SG_ 1191 Aux1AmbtColrCtlCstAvlFlg82 "Auxiliary 1 Ambient Color Control Customization Availability Flag 82";
BA_ "SignalType" SG_ 1191 Aux1AmbtColrCtlCstAvlFlg81 "ENM";
BA_ "SignalLongName" SG_ 1191 Aux1AmbtColrCtlCstAvlFlg81 "Auxiliary 1 Ambient Color Control Customization Availability Flag 81";
BA_ "SignalType" SG_ 1191 Aux1AmbtColrCtlCstAvlFlg80 "ENM";
BA_ "SignalLongName" SG_ 1191 Aux1AmbtColrCtlCstAvlFlg80 "Auxiliary 1 Ambient Color Control Customization Availability Flag 80";
BA_ "SignalType" SG_ 1191 Aux1AmbtColrCtlCstAvlFlg79 "ENM";
BA_ "SignalLongName" SG_ 1191 Aux1AmbtColrCtlCstAvlFlg79 "Auxiliary 1 Ambient Color Control Customization Availability Flag 79";
BA_ "SignalType" SG_ 1191 Aux1AmbtColrCtlCstAvlFlg78 "ENM";
BA_ "SignalLongName" SG_ 1191 Aux1AmbtColrCtlCstAvlFlg78 "Auxiliary 1 Ambient Color Control Customization Availability Flag 78";
BA_ "SignalType" SG_ 1191 Aux1AmbtColrCtlCstAvlFlg77 "ENM";
BA_ "SignalLongName" SG_ 1191 Aux1AmbtColrCtlCstAvlFlg77 "Auxiliary 1 Ambient Color Control Customization Availability Flag 77";
BA_ "SignalType" SG_ 1191 Aux1AmbtColrCtlCstAvlFlg76 "ENM";
BA_ "SignalLongName" SG_ 1191 Aux1AmbtColrCtlCstAvlFlg76 "Auxiliary 1 Ambient Color Control Customization Availability Flag 76";
BA_ "SignalLongName" SG_ 1875 FTLDI_LFTmToFlt "Front Tire Leak Detection Information : Left Front Time To Flat";
BA_ "SignalType" SG_ 1875 FTLDI_LFSts "ENM";
BA_ "SignalLongName" SG_ 1875 FTLDI_LFSts "Front Tire Leak Detection Information : Left Front Status";
BA_ "SignalType" SG_ 1875 FTLDI_RFSts "ENM";
BA_ "SignalLongName" SG_ 1875 FTLDI_RFSts "Front Tire Leak Detection Information : Right Front Status";
BA_ "SignalLongName" SG_ 1875 FTLDI_RFTmToFlt "Front Tire Leak Detection Information : Right Front Time To Flat";
BA_ "SignalType" SG_ 1875 IntrAmbtColrCtlCstAvlFlg10 "ENM";
BA_ "SignalLongName" SG_ 1875 IntrAmbtColrCtlCstAvlFlg10 "Interior Ambient Color Control Customization Availability Flag 10";
BA_ "SignalType" SG_ 1875 IntrAmbtColrCtlCstAvlFlg1 "ENM";
BA_ "SignalLongName" SG_ 1875 IntrAmbtColrCtlCstAvlFlg1 "Interior Ambient Color Control Customization Availability Flag 1";
BA_ "SignalType" SG_ 1875 IntrAmbtColrCtlCstAvlFlg18 "ENM";
BA_ "SignalLongName" SG_ 1875 IntrAmbtColrCtlCstAvlFlg18 "Interior Ambient Color Control Customization Availability Flag 18";
BA_ "SignalType" SG_ 1875 IntrAmbtColrCtlCstAvlFlg17 "ENM";
BA_ "SignalLongName" SG_ 1875 IntrAmbtColrCtlCstAvlFlg17 "Interior Ambient Color Control Customization Availability Flag 17";
BA_ "SignalType" SG_ 1875 IntrAmbtColrCtlCstAvlFlg16 "ENM";
BA_ "SignalLongName" SG_ 1875 IntrAmbtColrCtlCstAvlFlg16 "Interior Ambient Color Control Customization Availability Flag 16";
BA_ "SignalType" SG_ 1875 IntrAmbtColrCtlCstAvlFlg15 "ENM";
BA_ "SignalLongName" SG_ 1875 IntrAmbtColrCtlCstAvlFlg15 "Interior Ambient Color Control Customization Availability Flag 15";
BA_ "SignalType" SG_ 1875 IntrAmbtColrCtlCstAvlFlg14 "ENM";
BA_ "SignalLongName" SG_ 1875 IntrAmbtColrCtlCstAvlFlg14 "Interior Ambient Color Control Customization Availability Flag 14";
BA_ "SignalType" SG_ 1875 IntrAmbtColrCtlCstAvlFlg13 "ENM";
BA_ "SignalLongName" SG_ 1875 IntrAmbtColrCtlCstAvlFlg13 "Interior Ambient Color Control Customization Availability Flag 13";
BA_ "SignalType" SG_ 1875 IntrAmbtColrCtlCstAvlFlg12 "ENM";
BA_ "SignalLongName" SG_ 1875 IntrAmbtColrCtlCstAvlFlg12 "Interior Ambient Color Control Customization Availability Flag 12";
BA_ "SignalType" SG_ 1875 IntrAmbtColrCtlCstAvlFlg11 "ENM";
BA_ "SignalLongName" SG_ 1875 IntrAmbtColrCtlCstAvlFlg11 "Interior Ambient Color Control Customization Availability Flag 11";
BA_ "SignalType" SG_ 1875 IntrAmbtColrCtlCstAvlFlg25 "ENM";
BA_ "SignalLongName" SG_ 1875 IntrAmbtColrCtlCstAvlFlg25 "Interior Ambient Color Control Customization Availability Flag 25";
BA_ "SignalType" SG_ 1875 IntrAmbtColrCtlCstAvlFlg24 "ENM";
BA_ "SignalLongName" SG_ 1875 IntrAmbtColrCtlCstAvlFlg24 "Interior Ambient Color Control Customization Availability Flag 24";
BA_ "SignalType" SG_ 1875 IntrAmbtColrCtlCstAvlFlg23 "ENM";
BA_ "SignalLongName" SG_ 1875 IntrAmbtColrCtlCstAvlFlg23 "Interior Ambient Color Control Customization Availability Flag 23";
BA_ "SignalType" SG_ 1875 IntrAmbtColrCtlCstAvlFlg22 "ENM";
BA_ "SignalLongName" SG_ 1875 IntrAmbtColrCtlCstAvlFlg22 "Interior Ambient Color Control Customization Availability Flag 22";
BA_ "SignalType" SG_ 1875 IntrAmbtColrCtlCstAvlFlg21 "ENM";
BA_ "SignalLongName" SG_ 1875 IntrAmbtColrCtlCstAvlFlg21 "Interior Ambient Color Control Customization Availability Flag 21";
BA_ "SignalType" SG_ 1875 IntrAmbtColrCtlCstAvlFlg20 "ENM";
BA_ "SignalLongName" SG_ 1875 IntrAmbtColrCtlCstAvlFlg20 "Interior Ambient Color Control Customization Availability Flag 20";
BA_ "SignalType" SG_ 1875 IntrAmbtColrCtlCstAvlFlg2 "ENM";
BA_ "SignalLongName" SG_ 1875 IntrAmbtColrCtlCstAvlFlg2 "Interior Ambient Color Control Customization Availability Flag 2";
BA_ "SignalType" SG_ 1875 IntrAmbtColrCtlCstAvlFlg19 "ENM";
BA_ "SignalLongName" SG_ 1875 IntrAmbtColrCtlCstAvlFlg19 "Interior Ambient Color Control Customization Availability Flag 19";
BA_ "SignalLongName" SG_ 1190 HmdtySnsrGlssTemp "Humidity Sensor Glass Temperature";
BA_ "SignalLongName" SG_ 1190 HmdtySnsrTemp "Humidity Sensor Temperature";
BA_ "SignalLongName" SG_ 1190 HmdtySnsrRltvHmdty "Humidity Sensor Relative Humidity";
BA_ "SignalType" SG_ 1190 IntrAmbtColrCtlCstAvlFlg29 "ENM";
BA_ "SignalLongName" SG_ 1190 IntrAmbtColrCtlCstAvlFlg29 "Interior Ambient Color Control Customization Availability Flag 29";
BA_ "SignalType" SG_ 1190 IntrAmbtColrCtlCstAvlFlg28 "ENM";
BA_ "SignalLongName" SG_ 1190 IntrAmbtColrCtlCstAvlFlg28 "Interior Ambient Color Control Customization Availability Flag 28";
BA_ "SignalType" SG_ 1190 IntrAmbtColrCtlCstAvlFlg27 "ENM";
BA_ "SignalLongName" SG_ 1190 IntrAmbtColrCtlCstAvlFlg27 "Interior Ambient Color Control Customization Availability Flag 27";
BA_ "SignalType" SG_ 1190 IntrAmbtColrCtlCstAvlFlg26 "ENM";
BA_ "SignalLongName" SG_ 1190 IntrAmbtColrCtlCstAvlFlg26 "Interior Ambient Color Control Customization Availability Flag 26";
BA_ "SignalType" SG_ 1190 IntrAmbtColrCtlCstAvlFlg8 "ENM";
BA_ "SignalLongName" SG_ 1190 IntrAmbtColrCtlCstAvlFlg8 "Interior Ambient Color Control Customization Availability Flag 8";
BA_ "SignalType" SG_ 1190 IntrAmbtColrCtlCstAvlFlg7 "ENM";
BA_ "SignalLongName" SG_ 1190 IntrAmbtColrCtlCstAvlFlg7 "Interior Ambient Color Control Customization Availability Flag 7";
BA_ "SignalType" SG_ 1190 IntrAmbtColrCtlCstAvlFlg6 "ENM";
BA_ "SignalLongName" SG_ 1190 IntrAmbtColrCtlCstAvlFlg6 "Interior Ambient Color Control Customization Availability Flag 6";
BA_ "SignalType" SG_ 1190 IntrAmbtColrCtlCstAvlFlg5 "ENM";
BA_ "SignalLongName" SG_ 1190 IntrAmbtColrCtlCstAvlFlg5 "Interior Ambient Color Control Customization Availability Flag 5";
BA_ "SignalType" SG_ 1190 IntrAmbtColrCtlCstAvlFlg4 "ENM";
BA_ "SignalLongName" SG_ 1190 IntrAmbtColrCtlCstAvlFlg4 "Interior Ambient Color Control Customization Availability Flag 4";
BA_ "SignalType" SG_ 1190 IntrAmbtColrCtlCstAvlFlg31 "ENM";
BA_ "SignalLongName" SG_ 1190 IntrAmbtColrCtlCstAvlFlg31 "Interior Ambient Color Control Customization Availability Flag 31";
BA_ "SignalType" SG_ 1190 IntrAmbtColrCtlCstAvlFlg30 "ENM";
BA_ "SignalLongName" SG_ 1190 IntrAmbtColrCtlCstAvlFlg30 "Interior Ambient Color Control Customization Availability Flag 30";
BA_ "SignalType" SG_ 1190 IntrAmbtColrCtlCstAvlFlg3 "ENM";
BA_ "SignalLongName" SG_ 1190 IntrAmbtColrCtlCstAvlFlg3 "Interior Ambient Color Control Customization Availability Flag 3";
BA_ "SignalType" SG_ 1190 IonzrCtrlCstAvlFlg6 "ENM";
BA_ "SignalLongName" SG_ 1190 IonzrCtrlCstAvlFlg6 "Ionizer Control Customization Availability Flag 6";
BA_ "SignalType" SG_ 1190 IonzrCtrlCstAvlFlg5 "ENM";
BA_ "SignalLongName" SG_ 1190 IonzrCtrlCstAvlFlg5 "Ionizer Control Customization Availability Flag 5";
BA_ "SignalType" SG_ 1190 IonzrCtrlCstAvlFlg4 "ENM";
BA_ "SignalLongName" SG_ 1190 IonzrCtrlCstAvlFlg4 "Ionizer Control Customization Availability Flag 4";
BA_ "SignalType" SG_ 1190 IonzrCtrlCstAvlFlg3 "ENM";
BA_ "SignalLongName" SG_ 1190 IonzrCtrlCstAvlFlg3 "Ionizer Control Customization Availability Flag 3";
BA_ "SignalType" SG_ 1190 IonzrCtrlCstAvlFlg2 "ENM";
BA_ "SignalLongName" SG_ 1190 IonzrCtrlCstAvlFlg2 "Ionizer Control Customization Availability Flag 2";
BA_ "SignalType" SG_ 1190 IonzrCtrlCstAvlFlg1 "ENM";
BA_ "SignalLongName" SG_ 1190 IonzrCtrlCstAvlFlg1 "Ionizer Control Customization Availability Flag 1";
BA_ "SignalType" SG_ 1190 IntrAmbtColrCtlCstSetAval "ENM";
BA_ "SignalLongName" SG_ 1190 IntrAmbtColrCtlCstSetAval "Interior Ambient Color Control Customization Setting Available";
BA_ "SignalType" SG_ 1190 IntrAmbtColrCtlCstAvlFlg9 "ENM";
BA_ "SignalLongName" SG_ 1190 IntrAmbtColrCtlCstAvlFlg9 "Interior Ambient Color Control Customization Availability Flag 9";
BA_ "SignalType" SG_ 1190 LDCLCstAvlFlg7 "ENM";
BA_ "SignalLongName" SG_ 1190 LDCLCstAvlFlg7 "LastDoorClosedLockingCustomizationAvailabilityFlag7";
BA_ "SignalType" SG_ 1190 LDCLCstAvlFlg6 "ENM";
BA_ "SignalLongName" SG_ 1190 LDCLCstAvlFlg6 "LastDoorClosedLockingCustomizationAvailabilityFlag6";
BA_ "SignalType" SG_ 1190 LDCLCstAvlFlg5 "ENM";
BA_ "SignalLongName" SG_ 1190 LDCLCstAvlFlg5 "LastDoorClosedLockingCustomizationAvailabilityFlag5";
BA_ "SignalType" SG_ 1190 LDCLCstAvlFlg4 "ENM";
BA_ "SignalLongName" SG_ 1190 LDCLCstAvlFlg4 "LastDoorClosedLockingCustomizationAvailabilityFlag4";
BA_ "SignalType" SG_ 1190 LDCLCstAvlFlg3 "ENM";
BA_ "SignalLongName" SG_ 1190 LDCLCstAvlFlg3 "LastDoorClosedLockingCustomizationAvailabilityFlag3";
BA_ "SignalType" SG_ 1190 LDCLCstAvlFlg2 "ENM";
BA_ "SignalLongName" SG_ 1190 LDCLCstAvlFlg2 "LastDoorClosedLockingCustomizationAvailabilityFlag2";
BA_ "SignalType" SG_ 1190 LDCLCstAvlFlg1 "ENM";
BA_ "SignalLongName" SG_ 1190 LDCLCstAvlFlg1 "LastDoorClosedLockingCustomizationAvailabilityFlag1";
BA_ "SignalType" SG_ 1190 IonzrCtrlCstAvlFlg7 "ENM";
BA_ "SignalLongName" SG_ 1190 IonzrCtrlCstAvlFlg7 "Ionizer Control Customization Availability Flag 7";
BA_ "SignalType" SG_ 1190 Aux1AmbtColrCtlCstAvlFlg89 "ENM";
BA_ "SignalLongName" SG_ 1190 Aux1AmbtColrCtlCstAvlFlg89 "Auxiliary 1 Ambient Color Control Customization Availability Flag 89";
BA_ "SignalType" SG_ 1190 OpDrAtLOCstAvlFlg7 "ENM";
BA_ "SignalLongName" SG_ 1190 OpDrAtLOCstAvlFlg7 "OpenDoorAntiLockOutCustomizationAvailabilityFlag7";
BA_ "SignalType" SG_ 1190 OpDrAtLOCstAvlFlg6 "ENM";
BA_ "SignalLongName" SG_ 1190 OpDrAtLOCstAvlFlg6 "OpenDoorAntiLockOutCustomizationAvailabilityFlag6";
BA_ "SignalType" SG_ 1190 OpDrAtLOCstAvlFlg5 "ENM";
BA_ "SignalLongName" SG_ 1190 OpDrAtLOCstAvlFlg5 "OpenDoorAntiLockOutCustomizationAvailabilityFlag5";
BA_ "SignalType" SG_ 1190 OpDrAtLOCstAvlFlg4 "ENM";
BA_ "SignalLongName" SG_ 1190 OpDrAtLOCstAvlFlg4 "OpenDoorAntiLockOutCustomizationAvailabilityFlag4";
BA_ "SignalType" SG_ 1190 OpDrAtLOCstAvlFlg3 "ENM";
BA_ "SignalLongName" SG_ 1190 OpDrAtLOCstAvlFlg3 "OpenDoorAntiLockOutCustomizationAvailabilityFlag3";
BA_ "SignalType" SG_ 1190 OpDrAtLOCstAvlFlg2 "ENM";
BA_ "SignalLongName" SG_ 1190 OpDrAtLOCstAvlFlg2 "OpenDoorAntiLockOutCustomizationAvailabilityFlag2";
BA_ "SignalType" SG_ 1190 OpDrAtLOCstAvlFlg1 "ENM";
BA_ "SignalLongName" SG_ 1190 OpDrAtLOCstAvlFlg1 "OpenDoorAntiLockOutCustomizationAvailabilityFlag1";
BA_ "SignalType" SG_ 1876 PsvUnlckCstAvlFlg1 "ENM";
BA_ "SignalLongName" SG_ 1876 PsvUnlckCstAvlFlg1 "PassiveUnlockingCustomizationAvailabilityFlag1";
BA_ "SignalType" SG_ 1876 PlltnCtrlCstAvlFlg7 "ENM";
BA_ "SignalLongName" SG_ 1876 PlltnCtrlCstAvlFlg7 "Pollution Control Customization Availability Flag 7";
BA_ "SignalType" SG_ 1876 PlltnCtrlCstAvlFlg6 "ENM";
BA_ "SignalLongName" SG_ 1876 PlltnCtrlCstAvlFlg6 "Pollution Control Customization Availability Flag 6";
BA_ "SignalType" SG_ 1876 PlltnCtrlCstAvlFlg5 "ENM";
BA_ "SignalLongName" SG_ 1876 PlltnCtrlCstAvlFlg5 "Pollution Control Customization Availability Flag 5";
BA_ "SignalType" SG_ 1876 PlltnCtrlCstAvlFlg4 "ENM";
BA_ "SignalLongName" SG_ 1876 PlltnCtrlCstAvlFlg4 "Pollution Control Customization Availability Flag 4";
BA_ "SignalType" SG_ 1876 PlltnCtrlCstAvlFlg3 "ENM";
BA_ "SignalLongName" SG_ 1876 PlltnCtrlCstAvlFlg3 "Pollution Control Customization Availability Flag 3";
BA_ "SignalType" SG_ 1876 PlltnCtrlCstAvlFlg2 "ENM";
BA_ "SignalLongName" SG_ 1876 PlltnCtrlCstAvlFlg2 "Pollution Control Customization Availability Flag 2";
BA_ "SignalType" SG_ 1876 PlltnCtrlCstAvlFlg1 "ENM";
BA_ "SignalLongName" SG_ 1876 PlltnCtrlCstAvlFlg1 "Pollution Control Customization Availability Flag 1";
BA_ "SignalType" SG_ 1876 RemInVehRmndrCstAvlFlg2 "ENM";
BA_ "SignalLongName" SG_ 1876 RemInVehRmndrCstAvlFlg2 "RemoteInVehicleReminderCustomizationAvailabilityFlag2";
BA_ "SignalType" SG_ 1876 RemInVehRmndrCstAvlFlg1 "ENM";
BA_ "SignalLongName" SG_ 1876 RemInVehRmndrCstAvlFlg1 "RemoteInVehicleReminderCustomizationAvailabilityFlag1";
BA_ "SignalType" SG_ 1876 PsvUnlckCstAvlFlg7 "ENM";
BA_ "SignalLongName" SG_ 1876 PsvUnlckCstAvlFlg7 "PassiveUnlockingCustomizationAvailabilityFlag7";
BA_ "SignalType" SG_ 1876 PsvUnlckCstAvlFlg6 "ENM";
BA_ "SignalLongName" SG_ 1876 PsvUnlckCstAvlFlg6 "PassiveUnlockingCustomizationAvailabilityFlag6";
BA_ "SignalType" SG_ 1876 PsvUnlckCstAvlFlg5 "ENM";
BA_ "SignalLongName" SG_ 1876 PsvUnlckCstAvlFlg5 "PassiveUnlockingCustomizationAvailabilityFlag5";
BA_ "SignalType" SG_ 1876 PsvUnlckCstAvlFlg4 "ENM";
BA_ "SignalLongName" SG_ 1876 PsvUnlckCstAvlFlg4 "PassiveUnlockingCustomizationAvailabilityFlag4";
BA_ "SignalType" SG_ 1876 PsvUnlckCstAvlFlg3 "ENM";
BA_ "SignalLongName" SG_ 1876 PsvUnlckCstAvlFlg3 "PassiveUnlockingCustomizationAvailabilityFlag3";
BA_ "SignalType" SG_ 1876 PsvUnlckCstAvlFlg2 "ENM";
BA_ "SignalLongName" SG_ 1876 PsvUnlckCstAvlFlg2 "PassiveUnlockingCustomizationAvailabilityFlag2";
BA_ "SignalType" SG_ 1876 RemLftVehRmndrCstAvlFlg3 "ENM";
BA_ "SignalLongName" SG_ 1876 RemLftVehRmndrCstAvlFlg3 "RemoteLeftVehicleReminderCustomizationAvailabilityFlag3";
BA_ "SignalType" SG_ 1876 RemLftVehRmndrCstAvlFlg2 "ENM";
BA_ "SignalLongName" SG_ 1876 RemLftVehRmndrCstAvlFlg2 "RemoteLeftVehicleReminderCustomizationAvailabilityFlag2";
BA_ "SignalType" SG_ 1876 RemLftVehRmndrCstAvlFlg1 "ENM";
BA_ "SignalLongName" SG_ 1876 RemLftVehRmndrCstAvlFlg1 "RemoteLeftVehicleReminderCustomizationAvailabilityFlag1";
BA_ "SignalType" SG_ 1876 RemInVehRmndrCstAvlFlg7 "ENM";
BA_ "SignalLongName" SG_ 1876 RemInVehRmndrCstAvlFlg7 "RemoteInVehicleReminderCustomizationAvailabilityFlag7";
BA_ "SignalType" SG_ 1876 RemInVehRmndrCstAvlFlg6 "ENM";
BA_ "SignalLongName" SG_ 1876 RemInVehRmndrCstAvlFlg6 "RemoteInVehicleReminderCustomizationAvailabilityFlag6";
BA_ "SignalType" SG_ 1876 RemInVehRmndrCstAvlFlg5 "ENM";
BA_ "SignalLongName" SG_ 1876 RemInVehRmndrCstAvlFlg5 "RemoteInVehicleReminderCustomizationAvailabilityFlag5";
BA_ "SignalType" SG_ 1876 RemInVehRmndrCstAvlFlg4 "ENM";
BA_ "SignalLongName" SG_ 1876 RemInVehRmndrCstAvlFlg4 "RemoteInVehicleReminderCustomizationAvailabilityFlag4";
BA_ "SignalType" SG_ 1876 RemInVehRmndrCstAvlFlg3 "ENM";
BA_ "SignalLongName" SG_ 1876 RemInVehRmndrCstAvlFlg3 "RemoteInVehicleReminderCustomizationAvailabilityFlag3";
BA_ "SignalType" SG_ 1876 RevTltMirCstAvlFlg4 "ENM";
BA_ "SignalLongName" SG_ 1876 RevTltMirCstAvlFlg4 "ReverseTiltMirrorCustomizationAvailabilityFlag4";
BA_ "SignalType" SG_ 1876 RevTltMirCstAvlFlg3 "ENM";
BA_ "SignalLongName" SG_ 1876 RevTltMirCstAvlFlg3 "ReverseTiltMirrorCustomizationAvailabilityFlag3";
BA_ "SignalType" SG_ 1876 RevTltMirCstAvlFlg2 "ENM";
BA_ "SignalLongName" SG_ 1876 RevTltMirCstAvlFlg2 "ReverseTiltMirrorCustomizationAvailabilityFlag2";
BA_ "SignalType" SG_ 1876 RevTltMirCstAvlFlg1 "ENM";
BA_ "SignalLongName" SG_ 1876 RevTltMirCstAvlFlg1 "ReverseTiltMirrorCustomizationAvailabilityFlag1";
BA_ "SignalType" SG_ 1876 RemLftVehRmndrCstAvlFlg7 "ENM";
BA_ "SignalLongName" SG_ 1876 RemLftVehRmndrCstAvlFlg7 "RemoteLeftVehicleReminderCustomizationAvailabilityFlag7";
BA_ "SignalType" SG_ 1876 RemLftVehRmndrCstAvlFlg6 "ENM";
BA_ "SignalLongName" SG_ 1876 RemLftVehRmndrCstAvlFlg6 "RemoteLeftVehicleReminderCustomizationAvailabilityFlag6";
BA_ "SignalType" SG_ 1876 RemLftVehRmndrCstAvlFlg5 "ENM";
BA_ "SignalLongName" SG_ 1876 RemLftVehRmndrCstAvlFlg5 "RemoteLeftVehicleReminderCustomizationAvailabilityFlag5";
BA_ "SignalType" SG_ 1876 RemLftVehRmndrCstAvlFlg4 "ENM";
BA_ "SignalLongName" SG_ 1876 RemLftVehRmndrCstAvlFlg4 "RemoteLeftVehicleReminderCustomizationAvailabilityFlag4";
BA_ "SignalType" SG_ 1876 RlkRtUlkDrCstAvlFlg5 "ENM";
BA_ "SignalLongName" SG_ 1876 RlkRtUlkDrCstAvlFlg5 "RelockRemoteUnlockedDoorCustomizationAvailabilityFlag5";
BA_ "SignalType" SG_ 1876 RlkRtUlkDrCstAvlFlg4 "ENM";
BA_ "SignalLongName" SG_ 1876 RlkRtUlkDrCstAvlFlg4 "RelockRemoteUnlockedDoorCustomizationAvailabilityFlag4";
BA_ "SignalType" SG_ 1876 RlkRtUlkDrCstAvlFlg3 "ENM";
BA_ "SignalLongName" SG_ 1876 RlkRtUlkDrCstAvlFlg3 "RelockRemoteUnlockedDoorCustomizationAvailabilityFlag3";
BA_ "SignalType" SG_ 1876 RlkRtUlkDrCstAvlFlg2 "ENM";
BA_ "SignalLongName" SG_ 1876 RlkRtUlkDrCstAvlFlg2 "RelockRemoteUnlockedDoorCustomizationAvailabilityFlag2";
BA_ "SignalType" SG_ 1876 RlkRtUlkDrCstAvlFlg1 "ENM";
BA_ "SignalLongName" SG_ 1876 RlkRtUlkDrCstAvlFlg1 "RelockRemoteUnlockedDoorCustomizationAvailabilityFlag1";
BA_ "SignalType" SG_ 1876 RevTltMirCstAvlFlg7 "ENM";
BA_ "SignalLongName" SG_ 1876 RevTltMirCstAvlFlg7 "ReverseTiltMirrorCustomizationAvailabilityFlag7";
BA_ "SignalType" SG_ 1876 RevTltMirCstAvlFlg6 "ENM";
BA_ "SignalLongName" SG_ 1876 RevTltMirCstAvlFlg6 "ReverseTiltMirrorCustomizationAvailabilityFlag6";
BA_ "SignalType" SG_ 1876 RevTltMirCstAvlFlg5 "ENM";
BA_ "SignalLongName" SG_ 1876 RevTltMirCstAvlFlg5 "ReverseTiltMirrorCustomizationAvailabilityFlag5";
BA_ "SignalType" SG_ 1876 RmtSnrfOpCstAvlFlg6 "ENM";
BA_ "SignalLongName" SG_ 1876 RmtSnrfOpCstAvlFlg6 "Remote Sunroof Operation Customization Availability Flag 6";
BA_ "SignalType" SG_ 1876 RmtSnrfOpCstAvlFlg5 "ENM";
BA_ "SignalLongName" SG_ 1876 RmtSnrfOpCstAvlFlg5 "Remote Sunroof Operation Customization Availability Flag 5";
BA_ "SignalType" SG_ 1876 RmtSnrfOpCstAvlFlg4 "ENM";
BA_ "SignalLongName" SG_ 1876 RmtSnrfOpCstAvlFlg4 "Remote Sunroof Operation Customization Availability Flag 4";
BA_ "SignalType" SG_ 1876 RmtSnrfOpCstAvlFlg3 "ENM";
BA_ "SignalLongName" SG_ 1876 RmtSnrfOpCstAvlFlg3 "Remote Sunroof Operation Customization Availability Flag 3";
BA_ "SignalType" SG_ 1876 RmtSnrfOpCstAvlFlg2 "ENM";
BA_ "SignalLongName" SG_ 1876 RmtSnrfOpCstAvlFlg2 "Remote Sunroof Operation Customization Availability Flag 2";
BA_ "SignalType" SG_ 1876 RmtSnrfOpCstAvlFlg1 "ENM";
BA_ "SignalLongName" SG_ 1876 RmtSnrfOpCstAvlFlg1 "Remote Sunroof Operation Customization Availability Flag 1";
BA_ "SignalType" SG_ 1876 RlkRtUlkDrCstAvlFlg7 "ENM";
BA_ "SignalLongName" SG_ 1876 RlkRtUlkDrCstAvlFlg7 "RelockRemoteUnlockedDoorCustomizationAvailabilityFlag7";
BA_ "SignalType" SG_ 1876 RlkRtUlkDrCstAvlFlg6 "ENM";
BA_ "SignalLongName" SG_ 1876 RlkRtUlkDrCstAvlFlg6 "RelockRemoteUnlockedDoorCustomizationAvailabilityFlag6";
BA_ "SignalType" SG_ 1876 RmtStrtCoolStCstAvlFlg7 "ENM";
BA_ "SignalLongName" SG_ 1876 RmtStrtCoolStCstAvlFlg7 "Remote Start Cooled Seat Customization Availability Flag 7";
BA_ "SignalType" SG_ 1876 RmtStrtCoolStCstAvlFlg6 "ENM";
BA_ "SignalLongName" SG_ 1876 RmtStrtCoolStCstAvlFlg6 "Remote Start Cooled Seat Customization Availability Flag 6";
BA_ "SignalType" SG_ 1876 RmtStrtCoolStCstAvlFlg5 "ENM";
BA_ "SignalLongName" SG_ 1876 RmtStrtCoolStCstAvlFlg5 "Remote Start Cooled Seat Customization Availability Flag 5";
BA_ "SignalType" SG_ 1876 RmtStrtCoolStCstAvlFlg4 "ENM";
BA_ "SignalLongName" SG_ 1876 RmtStrtCoolStCstAvlFlg4 "Remote Start Cooled Seat Customization Availability Flag 4";
BA_ "SignalType" SG_ 1876 RmtStrtCoolStCstAvlFlg3 "ENM";
BA_ "SignalLongName" SG_ 1876 RmtStrtCoolStCstAvlFlg3 "Remote Start Cooled Seat Customization Availability Flag 3";
BA_ "SignalType" SG_ 1876 RmtStrtCoolStCstAvlFlg2 "ENM";
BA_ "SignalLongName" SG_ 1876 RmtStrtCoolStCstAvlFlg2 "Remote Start Cooled Seat Customization Availability Flag 2";
BA_ "SignalType" SG_ 1876 RmtStrtCoolStCstAvlFlg1 "ENM";
BA_ "SignalLongName" SG_ 1876 RmtStrtCoolStCstAvlFlg1 "Remote Start Cooled Seat Customization Availability Flag 1";
BA_ "SignalType" SG_ 1876 RmtSnrfOpCstAvlFlg7 "ENM";
BA_ "SignalLongName" SG_ 1876 RmtSnrfOpCstAvlFlg7 "Remote Sunroof Operation Customization Availability Flag 7";
BA_ "SignalType" SG_ 1876 Aux1AmbtColrCtlCstAvlFlg90 "ENM";
BA_ "SignalLongName" SG_ 1876 Aux1AmbtColrCtlCstAvlFlg90 "Auxiliary 1 Ambient Color Control Customization Availability Flag 90";
BA_ "SignalType" SG_ 1876 RmtStrtHtdStCstAvlFlg7 "ENM";
BA_ "SignalLongName" SG_ 1876 RmtStrtHtdStCstAvlFlg7 "Remote Start Heated Seat Customization Availability Flag 7";
BA_ "SignalType" SG_ 1876 RmtStrtHtdStCstAvlFlg6 "ENM";
BA_ "SignalLongName" SG_ 1876 RmtStrtHtdStCstAvlFlg6 "Remote Start Heated Seat Customization Availability Flag 6";
BA_ "SignalType" SG_ 1876 RmtStrtHtdStCstAvlFlg5 "ENM";
BA_ "SignalLongName" SG_ 1876 RmtStrtHtdStCstAvlFlg5 "Remote Start Heated Seat Customization Availability Flag 5";
BA_ "SignalType" SG_ 1876 RmtStrtHtdStCstAvlFlg4 "ENM";
BA_ "SignalLongName" SG_ 1876 RmtStrtHtdStCstAvlFlg4 "Remote Start Heated Seat Customization Availability Flag 4";
BA_ "SignalType" SG_ 1876 RmtStrtHtdStCstAvlFlg3 "ENM";
BA_ "SignalLongName" SG_ 1876 RmtStrtHtdStCstAvlFlg3 "Remote Start Heated Seat Customization Availability Flag 3";
BA_ "SignalType" SG_ 1876 RmtStrtHtdStCstAvlFlg2 "ENM";
BA_ "SignalLongName" SG_ 1876 RmtStrtHtdStCstAvlFlg2 "Remote Start Heated Seat Customization Availability Flag 2";
BA_ "SignalType" SG_ 1876 RmtStrtHtdStCstAvlFlg1 "ENM";
BA_ "SignalLongName" SG_ 1876 RmtStrtHtdStCstAvlFlg1 "Remote Start Heated Seat Customization Availability Flag 1";
BA_ "SignalType" SG_ 1189 RnSnsCstAvlFlg1 "ENM";
BA_ "SignalLongName" SG_ 1189 RnSnsCstAvlFlg1 "RainSenseCustomizationAvailabilityFlag1";
BA_ "SignalType" SG_ 1189 RmtWndOpCstAvlFlg7 "ENM";
BA_ "SignalLongName" SG_ 1189 RmtWndOpCstAvlFlg7 "RemoteWindowOperationCustomizationAvailabilityFlag7";
BA_ "SignalType" SG_ 1189 RmtWndOpCstAvlFlg6 "ENM";
BA_ "SignalLongName" SG_ 1189 RmtWndOpCstAvlFlg6 "RemoteWindowOperationCustomizationAvailabilityFlag6";
BA_ "SignalType" SG_ 1189 RmtWndOpCstAvlFlg5 "ENM";
BA_ "SignalLongName" SG_ 1189 RmtWndOpCstAvlFlg5 "RemoteWindowOperationCustomizationAvailabilityFlag5";
BA_ "SignalType" SG_ 1189 RmtWndOpCstAvlFlg4 "ENM";
BA_ "SignalLongName" SG_ 1189 RmtWndOpCstAvlFlg4 "RemoteWindowOperationCustomizationAvailabilityFlag4";
BA_ "SignalType" SG_ 1189 RmtWndOpCstAvlFlg3 "ENM";
BA_ "SignalLongName" SG_ 1189 RmtWndOpCstAvlFlg3 "RemoteWindowOperationCustomizationAvailabilityFlag3";
BA_ "SignalType" SG_ 1189 RmtWndOpCstAvlFlg2 "ENM";
BA_ "SignalLongName" SG_ 1189 RmtWndOpCstAvlFlg2 "RemoteWindowOperationCustomizationAvailabilityFlag2";
BA_ "SignalType" SG_ 1189 RmtWndOpCstAvlFlg1 "ENM";
BA_ "SignalLongName" SG_ 1189 RmtWndOpCstAvlFlg1 "RemoteWindowOperationCustomizationAvailabilityFlag1";
BA_ "SignalType" SG_ 1189 RrDfgStUpCstAvlFlg2 "ENM";
BA_ "SignalLongName" SG_ 1189 RrDfgStUpCstAvlFlg2 "Rear Defog Startup Customization Availability Flag 2";
BA_ "SignalType" SG_ 1189 RrDfgStUpCstAvlFlg1 "ENM";
BA_ "SignalLongName" SG_ 1189 RrDfgStUpCstAvlFlg1 "Rear Defog Startup Customization Availability Flag 1";
BA_ "SignalType" SG_ 1189 RnSnsCstAvlFlg7 "ENM";
BA_ "SignalLongName" SG_ 1189 RnSnsCstAvlFlg7 "RainSenseCustomizationAvailabilityFlag7";
BA_ "SignalType" SG_ 1189 RnSnsCstAvlFlg6 "ENM";
BA_ "SignalLongName" SG_ 1189 RnSnsCstAvlFlg6 "RainSenseCustomizationAvailabilityFlag6";
BA_ "SignalType" SG_ 1189 RnSnsCstAvlFlg5 "ENM";
BA_ "SignalLongName" SG_ 1189 RnSnsCstAvlFlg5 "RainSenseCustomizationAvailabilityFlag5";
BA_ "SignalType" SG_ 1189 RnSnsCstAvlFlg4 "ENM";
BA_ "SignalLongName" SG_ 1189 RnSnsCstAvlFlg4 "RainSenseCustomizationAvailabilityFlag4";
BA_ "SignalType" SG_ 1189 RnSnsCstAvlFlg3 "ENM";
BA_ "SignalLongName" SG_ 1189 RnSnsCstAvlFlg3 "RainSenseCustomizationAvailabilityFlag3";
BA_ "SignalType" SG_ 1189 RnSnsCstAvlFlg2 "ENM";
BA_ "SignalLongName" SG_ 1189 RnSnsCstAvlFlg2 "RainSenseCustomizationAvailabilityFlag2";
BA_ "SignalType" SG_ 1189 RrStRmndrEnblDsblCstAvlFlg3 "ENM";
BA_ "SignalLongName" SG_ 1189 RrStRmndrEnblDsblCstAvlFlg3 "Rear Seat Reminder Enable Disable Customization Availability Flag 3";
BA_ "SignalType" SG_ 1189 RrStRmndrEnblDsblCstAvlFlg2 "ENM";
BA_ "SignalLongName" SG_ 1189 RrStRmndrEnblDsblCstAvlFlg2 "Rear Seat Reminder Enable Disable Customization Availability Flag 2";
BA_ "SignalType" SG_ 1189 RrStRmndrEnblDsblCstAvlFlg1 "ENM";
BA_ "SignalLongName" SG_ 1189 RrStRmndrEnblDsblCstAvlFlg1 "Rear Seat Reminder Enable Disable Customization Availability Flag 1";
BA_ "SignalType" SG_ 1189 RrDfgStUpCstAvlFlg7 "ENM";
BA_ "SignalLongName" SG_ 1189 RrDfgStUpCstAvlFlg7 "Rear Defog Startup Customization Availability Flag 7";
BA_ "SignalType" SG_ 1189 RrDfgStUpCstAvlFlg6 "ENM";
BA_ "SignalLongName" SG_ 1189 RrDfgStUpCstAvlFlg6 "Rear Defog Startup Customization Availability Flag 6";
BA_ "SignalType" SG_ 1189 RrDfgStUpCstAvlFlg5 "ENM";
BA_ "SignalLongName" SG_ 1189 RrDfgStUpCstAvlFlg5 "Rear Defog Startup Customization Availability Flag 5";
BA_ "SignalType" SG_ 1189 RrDfgStUpCstAvlFlg4 "ENM";
BA_ "SignalLongName" SG_ 1189 RrDfgStUpCstAvlFlg4 "Rear Defog Startup Customization Availability Flag 4";
BA_ "SignalType" SG_ 1189 RrDfgStUpCstAvlFlg3 "ENM";
BA_ "SignalLongName" SG_ 1189 RrDfgStUpCstAvlFlg3 "Rear Defog Startup Customization Availability Flag 3";
BA_ "SignalType" SG_ 1189 RrZnStUpCstAvlFlg4 "ENM";
BA_ "SignalLongName" SG_ 1189 RrZnStUpCstAvlFlg4 "Rear Zone Startup Customization Availability Flag 4";
BA_ "SignalType" SG_ 1189 RrZnStUpCstAvlFlg3 "ENM";
BA_ "SignalLongName" SG_ 1189 RrZnStUpCstAvlFlg3 "Rear Zone Startup Customization Availability Flag 3";
BA_ "SignalType" SG_ 1189 RrZnStUpCstAvlFlg2 "ENM";
BA_ "SignalLongName" SG_ 1189 RrZnStUpCstAvlFlg2 "Rear Zone Startup Customization Availability Flag 2";
BA_ "SignalType" SG_ 1189 RrZnStUpCstAvlFlg1 "ENM";
BA_ "SignalLongName" SG_ 1189 RrZnStUpCstAvlFlg1 "Rear Zone Startup Customization Availability Flag 1";
BA_ "SignalType" SG_ 1189 RrStRmndrEnblDsblCstAvlFlg7 "ENM";
BA_ "SignalLongName" SG_ 1189 RrStRmndrEnblDsblCstAvlFlg7 "Rear Seat Reminder Enable Disable Customization Availability Flag 7";
BA_ "SignalType" SG_ 1189 RrStRmndrEnblDsblCstAvlFlg6 "ENM";
BA_ "SignalLongName" SG_ 1189 RrStRmndrEnblDsblCstAvlFlg6 "Rear Seat Reminder Enable Disable Customization Availability Flag 6";
BA_ "SignalType" SG_ 1189 RrStRmndrEnblDsblCstAvlFlg5 "ENM";
BA_ "SignalLongName" SG_ 1189 RrStRmndrEnblDsblCstAvlFlg5 "Rear Seat Reminder Enable Disable Customization Availability Flag 5";
BA_ "SignalType" SG_ 1189 RrStRmndrEnblDsblCstAvlFlg4 "ENM";
BA_ "SignalLongName" SG_ 1189 RrStRmndrEnblDsblCstAvlFlg4 "Rear Seat Reminder Enable Disable Customization Availability Flag 4";
BA_ "SignalType" SG_ 1189 RtLkFdbkCstAvlFlg5 "ENM";
BA_ "SignalLongName" SG_ 1189 RtLkFdbkCstAvlFlg5 "RemoteLockingFeedbackCustomizationAvailabilityFlag5";
BA_ "SignalType" SG_ 1189 RtLkFdbkCstAvlFlg4 "ENM";
BA_ "SignalLongName" SG_ 1189 RtLkFdbkCstAvlFlg4 "RemoteLockingFeedbackCustomizationAvailabilityFlag4";
BA_ "SignalType" SG_ 1189 RtLkFdbkCstAvlFlg3 "ENM";
BA_ "SignalLongName" SG_ 1189 RtLkFdbkCstAvlFlg3 "RemoteLockingFeedbackCustomizationAvailabilityFlag3";
BA_ "SignalType" SG_ 1189 RtLkFdbkCstAvlFlg2 "ENM";
BA_ "SignalLongName" SG_ 1189 RtLkFdbkCstAvlFlg2 "RemoteLockingFeedbackCustomizationAvailabilityFlag2";
BA_ "SignalType" SG_ 1189 RtLkFdbkCstAvlFlg1 "ENM";
BA_ "SignalLongName" SG_ 1189 RtLkFdbkCstAvlFlg1 "RemoteLockingFeedbackCustomizationAvailabilityFlag1";
BA_ "SignalType" SG_ 1189 RrZnStUpCstAvlFlg7 "ENM";
BA_ "SignalLongName" SG_ 1189 RrZnStUpCstAvlFlg7 "Rear Zone Startup Customization Availability Flag 7";
BA_ "SignalType" SG_ 1189 RrZnStUpCstAvlFlg6 "ENM";
BA_ "SignalLongName" SG_ 1189 RrZnStUpCstAvlFlg6 "Rear Zone Startup Customization Availability Flag 6";
BA_ "SignalType" SG_ 1189 RrZnStUpCstAvlFlg5 "ENM";
BA_ "SignalLongName" SG_ 1189 RrZnStUpCstAvlFlg5 "Rear Zone Startup Customization Availability Flag 5";
BA_ "SignalType" SG_ 1189 RtUlkLtFbCstAvlFlg6 "ENM";
BA_ "SignalLongName" SG_ 1189 RtUlkLtFbCstAvlFlg6 "RemoteUnlockLightingFeedbackCustomizationAvailabilityFlag6";
BA_ "SignalType" SG_ 1189 RtUlkLtFbCstAvlFlg5 "ENM";
BA_ "SignalLongName" SG_ 1189 RtUlkLtFbCstAvlFlg5 "RemoteUnlockLightingFeedbackCustomizationAvailabilityFlag5";
BA_ "SignalType" SG_ 1189 RtUlkLtFbCstAvlFlg4 "ENM";
BA_ "SignalLongName" SG_ 1189 RtUlkLtFbCstAvlFlg4 "RemoteUnlockLightingFeedbackCustomizationAvailabilityFlag4";
BA_ "SignalType" SG_ 1189 RtUlkLtFbCstAvlFlg3 "ENM";
BA_ "SignalLongName" SG_ 1189 RtUlkLtFbCstAvlFlg3 "RemoteUnlockLightingFeedbackCustomizationAvailabilityFlag3";
BA_ "SignalType" SG_ 1189 RtUlkLtFbCstAvlFlg2 "ENM";
BA_ "SignalLongName" SG_ 1189 RtUlkLtFbCstAvlFlg2 "RemoteUnlockLightingFeedbackCustomizationAvailabilityFlag2";
BA_ "SignalType" SG_ 1189 RtUlkLtFbCstAvlFlg1 "ENM";
BA_ "SignalLongName" SG_ 1189 RtUlkLtFbCstAvlFlg1 "RemoteUnlockLightingFeedbackCustomizationAvailabilityFlag1";
BA_ "SignalType" SG_ 1189 RtLkFdbkCstAvlFlg7 "ENM";
BA_ "SignalLongName" SG_ 1189 RtLkFdbkCstAvlFlg7 "RemoteLockingFeedbackCustomizationAvailabilityFlag7";
BA_ "SignalType" SG_ 1189 RtLkFdbkCstAvlFlg6 "ENM";
BA_ "SignalLongName" SG_ 1189 RtLkFdbkCstAvlFlg6 "RemoteLockingFeedbackCustomizationAvailabilityFlag6";
BA_ "SignalType" SG_ 1189 SelUlkCstAvlFlg7 "ENM";
BA_ "SignalLongName" SG_ 1189 SelUlkCstAvlFlg7 "SelectiveUnlockingCustomizationAvailabilityFlag7";
BA_ "SignalType" SG_ 1189 SelUlkCstAvlFlg6 "ENM";
BA_ "SignalLongName" SG_ 1189 SelUlkCstAvlFlg6 "SelectiveUnlockingCustomizationAvailabilityFlag6";
BA_ "SignalType" SG_ 1189 SelUlkCstAvlFlg5 "ENM";
BA_ "SignalLongName" SG_ 1189 SelUlkCstAvlFlg5 "SelectiveUnlockingCustomizationAvailabilityFlag5";
BA_ "SignalType" SG_ 1189 SelUlkCstAvlFlg4 "ENM";
BA_ "SignalLongName" SG_ 1189 SelUlkCstAvlFlg4 "SelectiveUnlockingCustomizationAvailabilityFlag4";
BA_ "SignalType" SG_ 1189 SelUlkCstAvlFlg3 "ENM";
BA_ "SignalLongName" SG_ 1189 SelUlkCstAvlFlg3 "SelectiveUnlockingCustomizationAvailabilityFlag3";
BA_ "SignalType" SG_ 1189 SelUlkCstAvlFlg2 "ENM";
BA_ "SignalLongName" SG_ 1189 SelUlkCstAvlFlg2 "SelectiveUnlockingCustomizationAvailabilityFlag2";
BA_ "SignalType" SG_ 1189 SelUlkCstAvlFlg1 "ENM";
BA_ "SignalLongName" SG_ 1189 SelUlkCstAvlFlg1 "SelectiveUnlockingCustomizationAvailabilityFlag1";
BA_ "SignalType" SG_ 1189 RtUlkLtFbCstAvlFlg7 "ENM";
BA_ "SignalLongName" SG_ 1189 RtUlkLtFbCstAvlFlg7 "RemoteUnlockLightingFeedbackCustomizationAvailabilityFlag7";
BA_ "SignalType" SG_ 1189 Aux1AmbtColrCtlCstAvlFlg92 "ENM";
BA_ "SignalLongName" SG_ 1189 Aux1AmbtColrCtlCstAvlFlg92 "Auxiliary 1 Ambient Color Control Customization Availability Flag 92";
BA_ "SignalType" SG_ 1189 Aux1AmbtColrCtlCstAvlFlg91 "ENM";
BA_ "SignalLongName" SG_ 1189 Aux1AmbtColrCtlCstAvlFlg91 "Auxiliary 1 Ambient Color Control Customization Availability Flag 91";
BA_ "SignalType" SG_ 1189 TnDrvOvSpdWrnCstAvlFlg6 "ENM";
BA_ "SignalLongName" SG_ 1189 TnDrvOvSpdWrnCstAvlFlg6 "Teen Driver Overspeed Warning Customization Availability Flag 6";
BA_ "SignalType" SG_ 1189 TnDrvOvSpdWrnCstAvlFlg5 "ENM";
BA_ "SignalLongName" SG_ 1189 TnDrvOvSpdWrnCstAvlFlg5 "Teen Driver Overspeed Warning Customization Availability Flag 5";
BA_ "SignalType" SG_ 1189 TnDrvOvSpdWrnCstAvlFlg4 "ENM";
BA_ "SignalLongName" SG_ 1189 TnDrvOvSpdWrnCstAvlFlg4 "Teen Driver Overspeed Warning Customization Availability Flag 4";
BA_ "SignalType" SG_ 1189 TnDrvOvSpdWrnCstAvlFlg3 "ENM";
BA_ "SignalLongName" SG_ 1189 TnDrvOvSpdWrnCstAvlFlg3 "Teen Driver Overspeed Warning Customization Availability Flag 3";
BA_ "SignalType" SG_ 1189 TnDrvOvSpdWrnCstAvlFlg2 "ENM";
BA_ "SignalLongName" SG_ 1189 TnDrvOvSpdWrnCstAvlFlg2 "Teen Driver Overspeed Warning Customization Availability Flag 2";
BA_ "SignalType" SG_ 1189 TnDrvOvSpdWrnCstAvlFlg1 "ENM";
BA_ "SignalLongName" SG_ 1189 TnDrvOvSpdWrnCstAvlFlg1 "Teen Driver Overspeed Warning Customization Availability Flag 1";
BA_ "SignalLongName" SG_ 1877 RTLDI_LRTmToFlt "Rear Tire Leak Detection Information : Left Rear Time To Flat";
BA_ "SignalType" SG_ 1877 RTLDI_LRSts "ENM";
BA_ "SignalLongName" SG_ 1877 RTLDI_LRSts "Rear Tire Leak Detection Information : Left Rear Status";
BA_ "SignalType" SG_ 1877 RTLDI_RRSts "ENM";
BA_ "SignalLongName" SG_ 1877 RTLDI_RRSts "Rear Tire Leak Detection Information : Right Rear Status";
BA_ "SignalLongName" SG_ 1877 RTLDI_RRTmToFlt "Rear Tire Leak Detection Information : Right Rear Time To Flat";
BA_ "SignalType" SG_ 1877 TrlrProfSeltnResp "ENM";
BA_ "SignalLongName" SG_ 1877 TrlrProfSeltnResp "Trailer Profile Selection Response";
BA_ "SignalType" SG_ 1877 TrlrTireLFPresSts "ENM";
BA_ "SignalLongName" SG_ 1877 TrlrTireLFPresSts "Trailer Tire Left Front Pressure Status";
BA_ "SignalType" SG_ 1877 TrlrTireLFPresSts_Inv "ENM";
BA_ "SignalLongName" SG_ 1877 TrlrTireLFPresSts_Inv "Trailer Tire Left Front Pressure Status Invalid";
BA_ "SignalType" SG_ 1877 TnDrvSpdLmtCstAvlFlg7 "ENM";
BA_ "SignalLongName" SG_ 1877 TnDrvSpdLmtCstAvlFlg7 "Teen Driver Speed Limit Customization Availability Flag 7";
BA_ "SignalType" SG_ 1877 TnDrvSpdLmtCstAvlFlg6 "ENM";
BA_ "SignalLongName" SG_ 1877 TnDrvSpdLmtCstAvlFlg6 "Teen Driver Speed Limit Customization Availability Flag 6";
BA_ "SignalType" SG_ 1877 TnDrvSpdLmtCstAvlFlg5 "ENM";
BA_ "SignalLongName" SG_ 1877 TnDrvSpdLmtCstAvlFlg5 "Teen Driver Speed Limit Customization Availability Flag 5";
BA_ "SignalType" SG_ 1877 TnDrvSpdLmtCstAvlFlg4 "ENM";
BA_ "SignalLongName" SG_ 1877 TnDrvSpdLmtCstAvlFlg4 "Teen Driver Speed Limit Customization Availability Flag 4";
BA_ "SignalType" SG_ 1877 TnDrvSpdLmtCstAvlFlg3 "ENM";
BA_ "SignalLongName" SG_ 1877 TnDrvSpdLmtCstAvlFlg3 "Teen Driver Speed Limit Customization Availability Flag 3";
BA_ "SignalType" SG_ 1877 TnDrvSpdLmtCstAvlFlg2 "ENM";
BA_ "SignalLongName" SG_ 1877 TnDrvSpdLmtCstAvlFlg2 "Teen Driver Speed Limit Customization Availability Flag 2";
BA_ "SignalType" SG_ 1877 TnDrvSpdLmtCstAvlFlg1 "ENM";
BA_ "SignalLongName" SG_ 1877 TnDrvSpdLmtCstAvlFlg1 "Teen Driver Speed Limit Customization Availability Flag 1";
BA_ "SignalType" SG_ 1877 TnDrvOvSpdWrnCstAvlFlg7 "ENM";
BA_ "SignalLongName" SG_ 1877 TnDrvOvSpdWrnCstAvlFlg7 "Teen Driver Overspeed Warning Customization Availability Flag 7";
BA_ "SignalLongName" SG_ 1878 TLDWCI_TmToFlt "Tire Leak Detection Worst Case Information : Time To Flat";
BA_ "SignalType" SG_ 1878 TLDWCI_Sts "ENM";
BA_ "SignalLongName" SG_ 1878 TLDWCI_Sts "Tire Leak Detection Worst Case Information : Status";
BA_ "SignalLongName" SG_ 1878 TirePrsFrntPlcrd "Tire Pressure Front Placard";
BA_ "SignalLongName" SG_ 1878 TirePrsRrPlcrd "Tire Pressure Rear Placard";
BA_ "SignalType" SG_ 1878 TrlrTireLFPres_Inv "ENM";
BA_ "SignalLongName" SG_ 1878 TrlrTireLFPres_Inv "Trailer Tire Left Front Pressure Invalid";
BA_ "SignalLongName" SG_ 1878 TrlrTireLFPres "Trailer Tire Left Front Pressure";
BA_ "SignalLongName" SG_ 1879 TrlrTireLFSnsrID "Trailer Tire Left Front Sensor Identifier";
BA_ "SignalLongName" SG_ 1879 TrlrTireLRPres "Trailer Tire Left Rear Pressure";
BA_ "SignalType" SG_ 1879 TrlrTireLRPres_Inv "ENM";
BA_ "SignalLongName" SG_ 1879 TrlrTireLRPres_Inv "Trailer Tire Left Rear Pressure Invalid";
BA_ "SignalLongName" SG_ 1879 TrlrTireLFTemp "Trailer Tire Left Front Temperature";
BA_ "SignalType" SG_ 1879 TrlrTireLFTemp_Inv "ENM";
BA_ "SignalLongName" SG_ 1879 TrlrTireLFTemp_Inv "Trailer Tire Left Front Temperature Invalid";
BA_ "SignalType" SG_ 1879 TrlrTireLtMdlPresSts "ENM";
BA_ "SignalLongName" SG_ 1879 TrlrTireLtMdlPresSts "Trailer Tire Left Middle Pressure Status";
BA_ "SignalType" SG_ 1879 TrlrTireLtMdlPresSts_Inv "ENM";
BA_ "SignalLongName" SG_ 1879 TrlrTireLtMdlPresSts_Inv "Trailer Tire Left Middle Pressure Status Invalid";
BA_ "SignalType" SG_ 1879 TrlrTireLRPresSts "ENM";
BA_ "SignalLongName" SG_ 1879 TrlrTireLRPresSts "Trailer Tire Left Rear Pressure Status";
BA_ "SignalType" SG_ 1879 TrlrTireLRPresSts_Inv "ENM";
BA_ "SignalLongName" SG_ 1879 TrlrTireLRPresSts_Inv "Trailer Tire Left Rear Pressure Status Invalid";
BA_ "SignalType" SG_ 1879 Aux1AmbtColrCtlCstAvlFlg94 "ENM";
BA_ "SignalLongName" SG_ 1879 Aux1AmbtColrCtlCstAvlFlg94 "Auxiliary 1 Ambient Color Control Customization Availability Flag 94";
BA_ "SignalType" SG_ 1879 Aux1AmbtColrCtlCstAvlFlg93 "ENM";
BA_ "SignalLongName" SG_ 1879 Aux1AmbtColrCtlCstAvlFlg93 "Auxiliary 1 Ambient Color Control Customization Availability Flag 93";
BA_ "SignalType" SG_ 1879 TrlrTireLrnSts "ENM";
BA_ "SignalLongName" SG_ 1879 TrlrTireLrnSts "Trailer Tire Learn Status";
VAL_ 1966 HVACICRFllAutoLF 0 "No Action" 1 "Auto Off" 2 "Auto On" ;
VAL_ 1966 HVACICRFllAutoThrdRow 0 "No Action" 1 "Auto Off" 2 "Auto On" ;
VAL_ 1966 HVACICRFllAutoRR 0 "No Action" 1 "Auto Off" 2 "Auto On" ;
VAL_ 1966 HVACICRFllAutoRF 0 "No Action" 1 "Auto Off" 2 "Auto On" ;
VAL_ 1966 HVACICRFllAutoLR 0 "No Action" 1 "Auto Off" 2 "Auto On" ;
VAL_ 1966 HVACICRPwrRrRt 0 "No Action" 1 "Power Off" 2 "Power On" ;
VAL_ 1966 HVACICRPwrRrLt 0 "No Action" 1 "Power Off" 2 "Power On" ;
VAL_ 1966 HVACICRPwrFrtRt 0 "No Action" 1 "Power Off" 2 "Power On" ;
VAL_ 1966 HVACICRPwrFrtLt 0 "No Action" 1 "Power Off" 2 "Power On" ;
VAL_ 1966 HVACICRWprHtdPrkDcr 0 "No Action" 1 "Off" 2 "On" ;
VAL_ 1966 HVACICRThrdRowLck 0 "No Action" 1 "Off" 2 "On" ;
VAL_ 1966 HVACICRRrLck 0 "No Action" 1 "Off" 2 "On" ;
VAL_ 1966 HVACICRPwrThrdRow 0 "No Action" 1 "Power Off" 2 "Power On" ;
VAL_ 662 InfoPsngSysHdg_Inv 0 "FALSE" 1 "TRUE" ;
VAL_ 662 InfoPsngSysElvtn_Inv 0 "FALSE" 1 "TRUE" ;
VAL_ 1083 ACCCSR_Aux3Colr 0 "No Action" 1 "Off" 2 "Color Type 1" 3 "Color Type 2" 4 "Color Type 3" 5 "Color Type 4" 6 "Color Type 5" 7 "Color Type 6" 8 "Color Type 7" 9 "Color Type 8" 10 "Color Type 9" 11 "Color Type 10" 12 "Color Type 11" 13 "Color Type 12" 14 "Color Type 13" 15 "Color Type 14" 16 "Color Type 15" 17 "Color Type 16" 18 "Color Type 17" 19 "Color Type 18" 20 "Color Type 19" 21 "Color Type 20" 22 "Color Type 21" 23 "Color Type 22" 24 "Color Type 23" 25 "Color Type 24" 26 "Color Type 25" 27 "Color Type 26" 28 "Color Type 27" 29 "Color Type 28" 30 "Color Type 29" 31 "Color Type 30" 32 "Color Type 31" 33 "Color Type 32" 34 "Color Type 33" 35 "Color Type 34" 36 "Color Type 35" 37 "Color Type 36" 38 "Color Type 37" 39 "Color Type 38" 40 "Color Type 39" 41 "Color Type 40" 42 "Color Type 41" 43 "Color Type 42" 44 "Color Type 43" 45 "Color Type 44" 46 "Color Type 45" 47 "Color Type 46" 48 "Color Type 47" 49 "Color Type 48" 50 "Color Type 49" 51 "Color Type 50" 52 "Color Type 51" 53 "Color Type 52" 54 "Color Type 53" 55 "Color Type 54" 56 "Color Type 55" 57 "Color Type 56" 58 "Color Type 57" 59 "Color Type 58" 60 "Color Type 59" 61 "Color Type 60" 62 "Color Type 61" 63 "Color Type 62" 64 "Color Type 63" 65 "Color Type 64" 66 "Color Type 65" 67 "Color Type 66" 68 "Color Type 67" 69 "Color Type 68" 70 "Color Type 69" 71 "Color Type 70" 72 "Color Type 71" 73 "Color Type 72" 74 "Color Type 73" 75 "Color Type 74" 76 "Color Type 75" 77 "Color Type 76" 78 "Color Type 77" 79 "Color Type 78" 80 "Color Type 79" 81 "Color Type 80" 82 "Color Type 81" 83 "Color Type 82" 84 "Color Type 83" 85 "Color Type 84" 86 "Color Type 85" 87 "Color Type 86" 88 "Color Type 87" 89 "Color Type 88" 90 "Color Type 89" 91 "Color Type 90" 92 "Color Type 91" 93 "Color Type 92" 94 "Color Type 93" 95 "Color Type 94" 96 "Color Type 95" 97 "Color Type 96" 98 "Color Type 97" 99 "Color Type 98" 100 "Color Type 99" 101 "Color Type 100" 102 "Color Type 101" 103 "Color Type 102" 104 "Color Type 103" 105 "Color Type 104" 106 "Color Type 105" 107 "Color Type 106" 108 "Color Type 107" 109 "Color Type 108" 110 "Color Type 109" 111 "Color Type 110" 112 "Color Type 111" 113 "Color Type 112" 114 "Color Type 113" 115 "Color Type 114" 116 "Color Type 115" 117 "Color Type 116" 118 "Color Type 117" 119 "Color Type 118" 120 "Color Type 119" 121 "Color Type 120" 122 "Color Type 121" 123 "Color Type 122" 124 "Color Type 123" 125 "Color Type 124" 126 "Color Type 125" 127 "Color Type 126" ;
VAL_ 1083 ACCCSR_Aux2Colr 0 "No Action" 1 "Off" 2 "Color Type 1" 3 "Color Type 2" 4 "Color Type 3" 5 "Color Type 4" 6 "Color Type 5" 7 "Color Type 6" 8 "Color Type 7" 9 "Color Type 8" 10 "Color Type 9" 11 "Color Type 10" 12 "Color Type 11" 13 "Color Type 12" 14 "Color Type 13" 15 "Color Type 14" 16 "Color Type 15" 17 "Color Type 16" 18 "Color Type 17" 19 "Color Type 18" 20 "Color Type 19" 21 "Color Type 20" 22 "Color Type 21" 23 "Color Type 22" 24 "Color Type 23" 25 "Color Type 24" 26 "Color Type 25" 27 "Color Type 26" 28 "Color Type 27" 29 "Color Type 28" 30 "Color Type 29" 31 "Color Type 30" 32 "Color Type 31" 33 "Color Type 32" 34 "Color Type 33" 35 "Color Type 34" 36 "Color Type 35" 37 "Color Type 36" 38 "Color Type 37" 39 "Color Type 38" 40 "Color Type 39" 41 "Color Type 40" 42 "Color Type 41" 43 "Color Type 42" 44 "Color Type 43" 45 "Color Type 44" 46 "Color Type 45" 47 "Color Type 46" 48 "Color Type 47" 49 "Color Type 48" 50 "Color Type 49" 51 "Color Type 50" 52 "Color Type 51" 53 "Color Type 52" 54 "Color Type 53" 55 "Color Type 54" 56 "Color Type 55" 57 "Color Type 56" 58 "Color Type 57" 59 "Color Type 58" 60 "Color Type 59" 61 "Color Type 60" 62 "Color Type 61" 63 "Color Type 62" 64 "Color Type 63" 65 "Color Type 64" 66 "Color Type 65" 67 "Color Type 66" 68 "Color Type 67" 69 "Color Type 68" 70 "Color Type 69" 71 "Color Type 70" 72 "Color Type 71" 73 "Color Type 72" 74 "Color Type 73" 75 "Color Type 74" 76 "Color Type 75" 77 "Color Type 76" 78 "Color Type 77" 79 "Color Type 78" 80 "Color Type 79" 81 "Color Type 80" 82 "Color Type 81" 83 "Color Type 82" 84 "Color Type 83" 85 "Color Type 84" 86 "Color Type 85" 87 "Color Type 86" 88 "Color Type 87" 89 "Color Type 88" 90 "Color Type 89" 91 "Color Type 90" 92 "Color Type 91" 93 "Color Type 92" 94 "Color Type 93" 95 "Color Type 94" 96 "Color Type 95" 97 "Color Type 96" 98 "Color Type 97" 99 "Color Type 98" 100 "Color Type 99" 101 "Color Type 100" 102 "Color Type 101" 103 "Color Type 102" 104 "Color Type 103" 105 "Color Type 104" 106 "Color Type 105" 107 "Color Type 106" 108 "Color Type 107" 109 "Color Type 108" 110 "Color Type 109" 111 "Color Type 110" 112 "Color Type 111" 113 "Color Type 112" 114 "Color Type 113" 115 "Color Type 114" 116 "Color Type 115" 117 "Color Type 116" 118 "Color Type 117" 119 "Color Type 118" 120 "Color Type 119" 121 "Color Type 120" 122 "Color Type 121" 123 "Color Type 122" 124 "Color Type 123" 125 "Color Type 124" 126 "Color Type 125" 127 "Color Type 126" ;
VAL_ 1083 ACCCSR_Aux2Anm 0 "No Action" 1 "Off" 2 "Animation Type 1" 3 "Animation Type 2" 4 "Animation Type 3" 5 "Animation Type 4" 6 "Animation Type 5" 7 "Animation Type 6" 8 "Animation Type 7" 9 "Animation Type 8" 10 "Animation Type 9" 11 "Animation Type 10" 12 "Animation Type 11" 13 "Animation Type 12" 14 "Animation Type 13" 15 "Animation Type 14" ;
VAL_ 1083 ACCCSR_Aux2Brghtns 0 "No Action" 1 "Brightness Level 1" 2 "Brightness Level 2" 3 "Brightness Level 3" 4 "Brightness Level 4" ;
VAL_ 1083 ACCCSR_Aux3Anm 0 "No Action" 1 "Off" 2 "Animation Type 1" 3 "Animation Type 2" 4 "Animation Type 3" 5 "Animation Type 4" 6 "Animation Type 5" 7 "Animation Type 6" 8 "Animation Type 7" 9 "Animation Type 8" 10 "Animation Type 9" 11 "Animation Type 10" 12 "Animation Type 11" 13 "Animation Type 12" 14 "Animation Type 13" 15 "Animation Type 14" ;
VAL_ 1083 ACCCSR_Aux3Brghtns 0 "No Action" 1 "Brightness Level 1" 2 "Brightness Level 2" 3 "Brightness Level 3" 4 "Brightness Level 4" ;
VAL_ 1965 StMasgTypLFVirtCtlReq 0 "No Request" 1 "Massage Off" 2 "Type 1" 3 "Type 2" 4 "Type 3" 5 "Type 4" 6 "Type 5" 7 "Type 6" 8 "Type 7" 9 "Type 8" 10 "Type 9" 11 "Type 10" 12 "Type 11" 13 "Type 12" 14 "Type 13" 15 "Type 14" 16 "Type 15" ;
VAL_ 1965 StMemLFVirtCtlReq 0 "No Request" 1 "Store Mem 1" 2 "Store Mem 2" 3 "Store Mem 3" 4 "Store Mem 4" 5 "Store Mem 5" 6 "Store Mem 6" 7 "Store Mem 7" 8 "Store Mem 8" 9 "Store Exit 1" 10 "Store Exit 2" 11 "Store Exit 3" 12 "Store Exit 4" 13 "Store Exit 5" 14 "Store Exit 6" 15 "Store Exit 7" 16 "Store Exit 8" 17 "Recall Mem 1" 18 "Recall Mem 2" 19 "Recall Mem 3" 20 "Recall Mem 4" 21 "Recall Mem 5" 22 "Recall Mem 6" 23 "Recall Mem 7" 24 "Recall Mem 8" 25 "Recall Exit 1" 26 "Recall Exit 2" 27 "Recall Exit 3" 28 "Recall Exit 4" 29 "Recall Exit 5" 30 "Recall Exit 6" 31 "Recall Exit 7" 32 "Recall Exit 8" 33 "Stop All Movement" ;
VAL_ 1965 StBkHrztlLFCtlFrmFrtVirtCtlReq 0 "No Request" 1 "Forward" 2 "Rearward" ;
VAL_ 1965 StMasgIntstyLFVirtCtlReq 0 "No Request" 1 "Massage Off" 2 "Intensity 1" 3 "Intensity 2" 4 "Intensity 3" 5 "Intensity 4" 6 "Intensity 5" 7 "Intensity 6" 8 "Intensity 7" ;
VAL_ 1965 StBkLumbHrztlLFVirtCtlReq 0 "No Request" 1 "Forward" 2 "Rearward" ;
VAL_ 1965 StCushHrztlLFCtlFrmFrtVirtCtlRq 0 "No Request" 1 "Forward" 2 "Rearward" ;
VAL_ 1965 StCushFrtVertLFVirtCtlReq 0 "No Request" 1 "Up" 2 "Down" ;
VAL_ 1965 StBkHrztlLFCtlFrmRrVirtCtlReq 0 "No Request" 1 "Forward" 2 "Rearward" ;
VAL_ 1965 StBkLumbVertLFVirtCtlReq 0 "No Request" 1 "Up" 2 "Down" ;
VAL_ 1965 StCushRrVertLFVirtCtlReq 0 "No Request" 1 "Up" 2 "Down" ;
VAL_ 1965 StCushLgthHrztlLFVirtCtlReq 0 "No Request" 1 "Forward" 2 "Rearward" ;
VAL_ 1965 StCushHrztlLFCtlFrmRrVirtCtlReq 0 "No Request" 1 "Forward" 2 "Rearward" ;
VAL_ 1965 StHdrstVertLFVirtCtlReq 0 "No Request" 1 "Up" 2 "Down" ;
VAL_ 1965 StHdrstHrztlLFVirtCtlReq 0 "No Request" 1 "Forward" 2 "Rearward" ;
VAL_ 1965 StBkSdBolsLFVirtCtlReq 0 "No Request" 1 "In" 2 "Out" ;
VAL_ 1965 StCushSdBolsLFVirtCtlReq 0 "No Request" 1 "In" 2 "Out" ;
VAL_ 1965 StUpprShldrHrztlLFVirtCtlReq 0 "No Request" 1 "Forward" 2 "Rearward" ;
VAL_ 1082 StMasgIntstyLRVirtCtlReq 0 "No Request" 1 "Massage Off" 2 "Intensity 1" 3 "Intensity 2" 4 "Intensity 3" 5 "Intensity 4" 6 "Intensity 5" 7 "Intensity 6" 8 "Intensity 7" ;
VAL_ 1082 StMasgTypLRVirtCtlReq 0 "No Request" 1 "Massage Off" 2 "Type 1" 3 "Type 2" 4 "Type 3" 5 "Type 4" 6 "Type 5" 7 "Type 6" 8 "Type 7" 9 "Type 8" 10 "Type 9" 11 "Type 10" 12 "Type 11" 13 "Type 12" 14 "Type 13" 15 "Type 14" 16 "Type 15" ;
VAL_ 1082 StCushLgthHrztlLRVirtCtlReq 0 "No Request" 1 "Forward" 2 "Rearward" ;
VAL_ 1082 StCushHrztlLRVirtCtlReq 0 "No Request" 1 "Forward" 2 "Rearward" ;
VAL_ 1082 StCushFrtVertLRVirtCtlReq 0 "No Request" 1 "Up" 2 "Down" ;
VAL_ 1082 StBkHrztlLRVirtCtlReq 0 "No Request" 1 "Forward" 2 "Rearward" ;
VAL_ 1082 StBkLumbVertLRVirtCtlReq 0 "No Request" 1 "Up" 2 "Down" ;
VAL_ 1082 StCushSdBolsLRVirtCtlReq 0 "No Request" 1 "In" 2 "Out" ;
VAL_ 1082 StBkLumbHrztlLRVirtCtlReq 0 "No Request" 1 "Forward" 2 "Rearward" ;
VAL_ 1082 StCushRrVertLRVirtCtlReq 0 "No Request" 1 "Up" 2 "Down" ;
VAL_ 1082 StUpprShldrHrztlLRVirtCtlReq 0 "No Request" 1 "Forward" 2 "Rearward" ;
VAL_ 1082 StHdrstVertLRVirtCtlReq 0 "No Request" 1 "Up" 2 "Down" ;
VAL_ 1082 StHdrstHrztlLRVirtCtlReq 0 "No Request" 1 "Forward" 2 "Rearward" ;
VAL_ 1082 StBkSdBolsLRVirtCtlReq 0 "No Request" 1 "In" 2 "Out" ;
VAL_ 1082 StLckoutLRVirtCtlReq 0 "No Request" 1 "Locked Out" 2 "Not Locked Out" ;
VAL_ 1026 StMasgIntstyRFVirtCtlReq 0 "No Request" 1 "Massage Off" 2 "Intensity 1" 3 "Intensity 2" 4 "Intensity 3" 5 "Intensity 4" 6 "Intensity 5" 7 "Intensity 6" 8 "Intensity 7" ;
VAL_ 1026 StMasgTypRFVirtCtlReq 0 "No Request" 1 "Massage Off" 2 "Type 1" 3 "Type 2" 4 "Type 3" 5 "Type 4" 6 "Type 5" 7 "Type 6" 8 "Type 7" 9 "Type 8" 10 "Type 9" 11 "Type 10" 12 "Type 11" 13 "Type 12" 14 "Type 13" 15 "Type 14" 16 "Type 15" ;
VAL_ 1026 StCushHrztlRFCtlFrmFrtVirtCtlRq 0 "No Request" 1 "Forward" 2 "Rearward" ;
VAL_ 1026 StBkHrztlRFCtlFrmRrVirtCtlReq 0 "No Request" 1 "Forward" 2 "Rearward" ;
VAL_ 1026 StCushFrtVertRFVirtCtlReq 0 "No Request" 1 "Up" 2 "Down" ;
VAL_ 1026 StBkHrztlRFCtlFrmFrtVirtCtlReq 0 "No Request" 1 "Forward" 2 "Rearward" ;
VAL_ 1026 StCushRrVertRFVirtCtlReq 0 "No Request" 1 "Up" 2 "Down" ;
VAL_ 1026 StBkLumbHrztlRFVirtCtlReq 0 "No Request" 1 "Forward" 2 "Rearward" ;
VAL_ 1026 StCushLgthHrztlRFVirtCtlReq 0 "No Request" 1 "Forward" 2 "Rearward" ;
VAL_ 1026 StCushHrztlRFCtlFrmRrVirtCtlReq 0 "No Request" 1 "Forward" 2 "Rearward" ;
VAL_ 1026 StHdrstHrztlRFVirtCtlReq 0 "No Request" 1 "Forward" 2 "Rearward" ;
VAL_ 1026 StBkSdBolsRFVirtCtlReq 0 "No Request" 1 "In" 2 "Out" ;
VAL_ 1026 StBkLumbVertRFVirtCtlReq 0 "No Request" 1 "Up" 2 "Down" ;
VAL_ 1026 StCushSdBolsRFVirtCtlReq 0 "No Request" 1 "In" 2 "Out" ;
VAL_ 1026 StUpprShldrHrztlRFVirtCtlReq 0 "No Request" 1 "Forward" 2 "Rearward" ;
VAL_ 1026 StHdrstVertRFVirtCtlReq 0 "No Request" 1 "Up" 2 "Down" ;
VAL_ 1027 StMasgIntstyRRVirtCtlReq 0 "No Request" 1 "Massage Off" 2 "Intensity 1" 3 "Intensity 2" 4 "Intensity 3" 5 "Intensity 4" 6 "Intensity 5" 7 "Intensity 6" 8 "Intensity 7" ;
VAL_ 1027 StMasgTypRRVirtCtlReq 0 "No Request" 1 "Massage Off" 2 "Type 1" 3 "Type 2" 4 "Type 3" 5 "Type 4" 6 "Type 5" 7 "Type 6" 8 "Type 7" 9 "Type 8" 10 "Type 9" 11 "Type 10" 12 "Type 11" 13 "Type 12" 14 "Type 13" 15 "Type 14" 16 "Type 15" ;
VAL_ 1027 StBkSdBolsRRVirtCtlReq 0 "No Request" 1 "In" 2 "Out" ;
VAL_ 1027 StBkLumbVertRRVirtCtlReq 0 "No Request" 1 "Up" 2 "Down" ;
VAL_ 1027 StBkLumbHrztlRRVirtCtlReq 0 "No Request" 1 "Forward" 2 "Rearward" ;
VAL_ 1027 StBkHrztlRRVirtCtlReq 0 "No Request" 1 "Forward" 2 "Rearward" ;
VAL_ 1027 StCushRrVertRRVirtCtlReq 0 "No Request" 1 "Up" 2 "Down" ;
VAL_ 1027 StCushLgthHrztlRRVirtCtlReq 0 "No Request" 1 "Forward" 2 "Rearward" ;
VAL_ 1027 StCushHrztlRRVirtCtlReq 0 "No Request" 1 "Forward" 2 "Rearward" ;
VAL_ 1027 StCushFrtVertRRVirtCtlReq 0 "No Request" 1 "Up" 2 "Down" ;
VAL_ 1027 StUpprShldrHrztlRRVirtCtlReq 0 "No Request" 1 "Forward" 2 "Rearward" ;
VAL_ 1027 StHdrstVertRRVirtCtlReq 0 "No Request" 1 "Up" 2 "Down" ;
VAL_ 1027 StHdrstHrztlRRVirtCtlReq 0 "No Request" 1 "Forward" 2 "Rearward" ;
VAL_ 1027 StCushSdBolsRRVirtCtlReq 0 "No Request" 1 "In" 2 "Out" ;
VAL_ 1027 StLckoutRRVirtCtlReq 0 "No Request" 1 "Locked Out" 2 "Not Locked Out" ;
VAL_ 1983 InfoUTCMth 0 "Unknown" 1 "January" 2 "February" 3 "March" 4 "April" 5 "May" 6 "June" 7 "July" 8 "August" 9 "September" 10 "October" 11 "November" 12 "December" ;
VAL_ 1983 InfoUTCYr_Inv 0 "FALSE" 1 "TRUE" ;
VAL_ 1983 InfoUTCSec_Inv 0 "FALSE" 1 "TRUE" ;
VAL_ 1983 InfoUTCMth_Inv 0 "FALSE" 1 "TRUE" ;
VAL_ 1983 InfoUTCMin_Inv 0 "FALSE" 1 "TRUE" ;
VAL_ 1983 InfoUTCHrs_Inv 0 "FALSE" 1 "TRUE" ;
VAL_ 1983 InfoUTCDay_Inv 0 "FALSE" 1 "TRUE" ;
VAL_ 1983 DrvrSeltdOtltOffPwrMdVirCtlRq 0 "No Request" 1 "Disabled" 2 "Enabled" ;
VAL_ 1983 OtltsOffPwrModeTmrOpCstSetReq 0 "No Action" 1 "Off" 2 "On" ;
VAL_ 1983 OffbrdEngyXferMinSOCReq_DuD 0 "FALSE" 1 "TRUE" ;
VAL_ 1983 OtltsOffPwrModeTmrReqVal_DuD 0 "FALSE" 1 "TRUE" ;
VAL_ 1979 VirtCtlGlsRfTntLvlPnl3Req 0 "No Request" 1 "Dark" 2 "Clear Level 1" 3 "Clear Level 2" 4 "Clear Level 3" 5 "Clear Level 4" 6 "Clear Level 5" 7 "Clear Level 6" ;
VAL_ 1979 VirtCtlGlsRfTntLvlPnl2Req 0 "No Request" 1 "Dark" 2 "Clear Level 1" 3 "Clear Level 2" 4 "Clear Level 3" 5 "Clear Level 4" 6 "Clear Level 5" 7 "Clear Level 6" ;
VAL_ 1979 VirtCtlGlsRfTntLvlPnl1Req 0 "No Request" 1 "Dark" 2 "Clear Level 1" 3 "Clear Level 2" 4 "Clear Level 3" 5 "Clear Level 4" 6 "Clear Level 5" 7 "Clear Level 6" ;
VAL_ 1979 VirtCtlGlsRfTntLvlPnl6Req 0 "No Request" 1 "Dark" 2 "Clear Level 1" 3 "Clear Level 2" 4 "Clear Level 3" 5 "Clear Level 4" 6 "Clear Level 5" 7 "Clear Level 6" ;
VAL_ 1979 VirtCtlGlsRfTntLvlPnl5Req 0 "No Request" 1 "Dark" 2 "Clear Level 1" 3 "Clear Level 2" 4 "Clear Level 3" 5 "Clear Level 4" 6 "Clear Level 5" 7 "Clear Level 6" ;
VAL_ 1979 VirtCtlGlsRfTntLvlPnl4Req 0 "No Request" 1 "Dark" 2 "Clear Level 1" 3 "Clear Level 2" 4 "Clear Level 3" 5 "Clear Level 4" 6 "Clear Level 5" 7 "Clear Level 6" ;
VAL_ 1979 VirtCtlGlsRfTntLvlPnl8Req 0 "No Request" 1 "Dark" 2 "Clear Level 1" 3 "Clear Level 2" 4 "Clear Level 3" 5 "Clear Level 4" 6 "Clear Level 5" 7 "Clear Level 6" ;
VAL_ 1979 VirtCtlGlsRfTntLvlPnl7Req 0 "No Request" 1 "Dark" 2 "Clear Level 1" 3 "Clear Level 2" 4 "Clear Level 3" 5 "Clear Level 4" 6 "Clear Level 5" 7 "Clear Level 6" ;
VAL_ 1979 VirtCtlPwrShdBkGlsReq 0 "No Request" 1 "Fully Open" 2 "Fully Closed" ;
VAL_ 1979 VirtCtlGlsRfTntAutoSetReq 0 "No Request" 1 "Active" 2 "Inactive" ;
VAL_ 1979 VirtCtlGlsRfPwrShdPrvcyReqd 0 "No Request" 1 "Privacy" 2 "Visibility" ;
VAL_ 1979 VirtCtlGlsRfTntLvlSldrReq 0 "No Request" 1 "Clear Level 1" 2 "Clear Level 2" 3 "Clear Level 3" 4 "Clear Level 4" 5 "Clear Level 5" 6 "Clear Level 6" ;
VAL_ 1979 VirtCtlGlsRfTntReqd 0 "FALSE" 1 "TRUE" ;
VAL_ 1979 VirtCtlGlsRfDrkReqd 0 "FALSE" 1 "TRUE" ;
VAL_ 1979 VirtCtlGlsRfClrReqd 0 "FALSE" 1 "TRUE" ;
VAL_ 1979 VirtCtlPwrShdRRReq 0 "No Request" 1 "Fully Open" 2 "Fully Closed" ;
VAL_ 1979 VirtCtlPwrShdLRReq 0 "No Request" 1 "Fully Open" 2 "Fully Closed" ;
VAL_ 1979 OtltsOffPwrModeTmrAddTmReq 0 "FALSE" 1 "TRUE" ;
VAL_ 1979 OtltsOffPwrMdSysStopReq 0 "FALSE" 1 "TRUE" ;
VAL_ 95 HiVltgChrgCtlPilotDCGtd_DuD 0 "FALSE" 1 "TRUE" ;
VAL_ 95 HiVltgChrgCtlPilotVltgGtd_DuD 0 "FALSE" 1 "TRUE" ;
VAL_ 95 HiVltgChrgCtlPilotPrdGtd_Inv 0 "FALSE" 1 "TRUE" ;
VAL_ 95 HiVltgChrgCtlPilotPrdGtd_DuD 0 "FALSE" 1 "TRUE" ;
VAL_ 95 HiVltgChrgCtlPilotDCGtd_Inv 0 "FALSE" 1 "TRUE" ;
VAL_ 95 HiVltgChrgVntilationSwSts 0 "Indeterminate" 1 "Closed" 2 "Open" 3 "Faulted" ;
VAL_ 95 HiVltgChrgS2SwSts 0 "Indeterminate" 1 "Closed" 2 "Open" 3 "Faulted" ;
VAL_ 95 HiVltgChrgCtlPilotVltgGtd_Inv 0 "FALSE" 1 "TRUE" ;
VAL_ 1936 ChrgStnCommActvReqd 0 "FALSE" 1 "TRUE" ;
VAL_ 1992 EmsRltPrsnlMdSndCstChngSetReq 0 "No Action" 1 "Personal Mode 1" 2 "Personal Mode 2" 3 "Personal Mode 3" 4 "Personal Mode 4" 5 "Personal Mode 5" 6 "Personal Mode 6" 7 "Personal Mode 7" ;
VAL_ 1992 EmsRltCustMdSndCstChngSetReq 0 "No Action" 1 "Custom Mode 1" 2 "Custom Mode 2" 3 "Custom Mode 3" 4 "Custom Mode 4" 5 "Custom Mode 5" 6 "Custom Mode 6" 7 "Custom Mode 7" ;
VAL_ 1992 EmsRltCustMdPTCstChngSetReq 0 "No Action" 1 "Custom Mode 1" 2 "Custom Mode 2" 3 "Custom Mode 3" 4 "Custom Mode 4" 5 "Custom Mode 5" 6 "Custom Mode 6" 7 "Custom Mode 7" ;
VAL_ 1074 EnhdServsVehTopSpdLimRespTyp 0 "Inactive" 1 "Faulted" 2 "Safety_woBrake" 3 "Safety_wBrake" 4 "OBD" 5 "nonOBD" 6 "Legislated" ;
VAL_ 1074 PrplInhbWrnIndOn 0 "FALSE" 1 "TRUE" ;
VAL_ 1993 VirtKeyPinToStrtScrnReq 0 "No Screen" 1 "Pin Entry Screen" 2 "Retrigger Pin Entry Screen" 3 "Pin Confirmed Screen" 4 "Pin Authentication Timed Out Screen" 5 "Pin Rejected Screen" 6 "Lockout Screen" 7 "NFC Authenticated Screen" 8 "NFC Tap Required Screen" 9 "Retry Pin Entry Screen" ;
VAL_ 1993 VirtKeyPinToStrtPINLgth 0 "No Value" 1 "1 Digit" 2 "2 Digits" 3 "3 Digits" 4 "4 Digits" 5 "5 Digits" 6 "6 Digits" 7 "7 Digits" ;
VAL_ 1993 VirtKeyPinToStrtRmnAtmp 0 "No Value" 1 "1 Attempt" 2 "2 Attempts" 3 "3 Attempts" 4 "4 Attempts" 5 "5 Attempts" 6 "6 Attempts" 7 "7 Attempts" 8 "8 Attempts" 9 "9 Attempts" 10 "10 Attempts" 11 "11 Attempts" 12 "12 Attempts" 13 "13 Attempts" 14 "14 Attempts" 15 "15 Attempts" ;
VAL_ 1947 TrfcSgnMemCstSetAval 0 "FALSE" 1 "TRUE" ;
VAL_ 1947 TrfcSgnMemCstAvlFlg7 0 "FALSE" 1 "TRUE" ;
VAL_ 1947 TrfcSgnMemCstAvlFlg6 0 "FALSE" 1 "TRUE" ;
VAL_ 1947 TrfcSgnMemCstAvlFlg5 0 "FALSE" 1 "TRUE" ;
VAL_ 1947 TrfcSgnMemCstAvlFlg4 0 "FALSE" 1 "TRUE" ;
VAL_ 1947 TrfcSgnMemCstAvlFlg3 0 "FALSE" 1 "TRUE" ;
VAL_ 1947 TrfcSgnMemCstAvlFlg2 0 "FALSE" 1 "TRUE" ;
VAL_ 1947 TrfcSgnMemCstAvlFlg1 0 "FALSE" 1 "TRUE" ;
VAL_ 1947 TrfcSgnMemOvrspdChmCstAvlFlg7 0 "FALSE" 1 "TRUE" ;
VAL_ 1947 TrfcSgnMemOvrspdChmCstAvlFlg6 0 "FALSE" 1 "TRUE" ;
VAL_ 1947 TrfcSgnMemOvrspdChmCstAvlFlg5 0 "FALSE" 1 "TRUE" ;
VAL_ 1947 TrfcSgnMemOvrspdChmCstAvlFlg4 0 "FALSE" 1 "TRUE" ;
VAL_ 1947 TrfcSgnMemOvrspdChmCstAvlFlg3 0 "FALSE" 1 "TRUE" ;
VAL_ 1947 TrfcSgnMemOvrspdChmCstAvlFlg2 0 "FALSE" 1 "TRUE" ;
VAL_ 1947 TrfcSgnMemOvrspdChmCstAvlFlg1 0 "FALSE" 1 "TRUE" ;
VAL_ 1947 TrfcSgnMemOfstEnbld 0 "FALSE" 1 "TRUE" ;
VAL_ 1947 TrfcSgnMemSpdLmChgChmCstAvlFlg7 0 "FALSE" 1 "TRUE" ;
VAL_ 1947 TrfcSgnMemSpdLmChgChmCstAvlFlg6 0 "FALSE" 1 "TRUE" ;
VAL_ 1947 TrfcSgnMemSpdLmChgChmCstAvlFlg5 0 "FALSE" 1 "TRUE" ;
VAL_ 1947 TrfcSgnMemSpdLmChgChmCstAvlFlg4 0 "FALSE" 1 "TRUE" ;
VAL_ 1947 TrfcSgnMemSpdLmChgChmCstAvlFlg3 0 "FALSE" 1 "TRUE" ;
VAL_ 1947 TrfcSgnMemSpdLmChgChmCstAvlFlg2 0 "FALSE" 1 "TRUE" ;
VAL_ 1947 TrfcSgnMemSpdLmChgChmCstAvlFlg1 0 "FALSE" 1 "TRUE" ;
VAL_ 1947 TrfcSgnMemOvrspdChmCstSetAval 0 "FALSE" 1 "TRUE" ;
VAL_ 1947 TrfcSgnMemSpdLmChgChmCstSetAval 0 "FALSE" 1 "TRUE" ;
VAL_ 1118 TrfcSgnMemOvrspdChmCstChgSetReq 0 "No Action" 1 "Off" 2 "On" ;
VAL_ 1118 TrfcSgnMemCstChgSetReq 0 "No Action" 1 "Off" 2 "On" ;
VAL_ 1118 TrfSgnMemSpdLmChgChmCstChgSetRq 0 "No Action" 1 "Off" 2 "On" ;
VAL_ 1119 TrfcSgnMemSgnChgChmEvntStat 0 "No Action" 1 "Active" 2 "Cancel Chime" ;
VAL_ 1119 TrfcSgnMemOvrspdChmEvntStat 0 "No Action" 1 "Active" 2 "Cancel Chime" ;
VAL_ 1948 TrfcSgnMemCstCurrSetVal 0 "Setting Unknown" 1 "Off" 2 "On" ;
VAL_ 1948 TrfSgnMemSpdLmChgChmCstCurSetVl 0 "Setting Unknown" 1 "Off" 2 "On" ;
VAL_ 1948 TrfSgnMemOvrspdChmCstCurrSetVal 0 "Setting Unknown" 1 "Off" 2 "On" ;
VAL_ 1948 TrfcSgnMemOvrspdWrnOffIndOn 0 "FALSE" 1 "TRUE" ;
VAL_ 1948 TrfcSgnMemDsbldIndOn 0 "FALSE" 1 "TRUE" ;
VAL_ 1192 AutDrvLckCstAvlFlg1 0 "FALSE" 1 "TRUE" ;
VAL_ 1192 AirQltySnsCstAvlFlg7 0 "FALSE" 1 "TRUE" ;
VAL_ 1192 AirQltySnsCstAvlFlg6 0 "FALSE" 1 "TRUE" ;
VAL_ 1192 AirQltySnsCstAvlFlg5 0 "FALSE" 1 "TRUE" ;
VAL_ 1192 AirQltySnsCstAvlFlg4 0 "FALSE" 1 "TRUE" ;
VAL_ 1192 AirQltySnsCstAvlFlg3 0 "FALSE" 1 "TRUE" ;
VAL_ 1192 AirQltySnsCstAvlFlg2 0 "FALSE" 1 "TRUE" ;
VAL_ 1192 AirQltySnsCstAvlFlg1 0 "FALSE" 1 "TRUE" ;
VAL_ 1192 AutMirFldCstAvlFlg2 0 "FALSE" 1 "TRUE" ;
VAL_ 1192 AutMirFldCstAvlFlg1 0 "FALSE" 1 "TRUE" ;
VAL_ 1192 AutDrvLckCstAvlFlg7 0 "FALSE" 1 "TRUE" ;
VAL_ 1192 AutDrvLckCstAvlFlg6 0 "FALSE" 1 "TRUE" ;
VAL_ 1192 AutDrvLckCstAvlFlg5 0 "FALSE" 1 "TRUE" ;
VAL_ 1192 AutDrvLckCstAvlFlg4 0 "FALSE" 1 "TRUE" ;
VAL_ 1192 AutDrvLckCstAvlFlg3 0 "FALSE" 1 "TRUE" ;
VAL_ 1192 AutDrvLckCstAvlFlg2 0 "FALSE" 1 "TRUE" ;
VAL_ 1192 AutoAirDstCstAvlFlg3 0 "FALSE" 1 "TRUE" ;
VAL_ 1192 AutoAirDstCstAvlFlg2 0 "FALSE" 1 "TRUE" ;
VAL_ 1192 AutoAirDstCstAvlFlg1 0 "FALSE" 1 "TRUE" ;
VAL_ 1192 AutMirFldCstAvlFlg7 0 "FALSE" 1 "TRUE" ;
VAL_ 1192 AutMirFldCstAvlFlg6 0 "FALSE" 1 "TRUE" ;
VAL_ 1192 AutMirFldCstAvlFlg5 0 "FALSE" 1 "TRUE" ;
VAL_ 1192 AutMirFldCstAvlFlg4 0 "FALSE" 1 "TRUE" ;
VAL_ 1192 AutMirFldCstAvlFlg3 0 "FALSE" 1 "TRUE" ;
VAL_ 1192 AutoCoolStCstAvlFlg4 0 "FALSE" 1 "TRUE" ;
VAL_ 1192 AutoCoolStCstAvlFlg3 0 "FALSE" 1 "TRUE" ;
VAL_ 1192 AutoCoolStCstAvlFlg2 0 "FALSE" 1 "TRUE" ;
VAL_ 1192 AutoCoolStCstAvlFlg1 0 "FALSE" 1 "TRUE" ;
VAL_ 1192 AutoAirDstCstAvlFlg7 0 "FALSE" 1 "TRUE" ;
VAL_ 1192 AutoAirDstCstAvlFlg6 0 "FALSE" 1 "TRUE" ;
VAL_ 1192 AutoAirDstCstAvlFlg5 0 "FALSE" 1 "TRUE" ;
VAL_ 1192 AutoAirDstCstAvlFlg4 0 "FALSE" 1 "TRUE" ;
VAL_ 1192 AutoDfgCstAvlFlg5 0 "FALSE" 1 "TRUE" ;
VAL_ 1192 AutoDfgCstAvlFlg4 0 "FALSE" 1 "TRUE" ;
VAL_ 1192 AutoDfgCstAvlFlg3 0 "FALSE" 1 "TRUE" ;
VAL_ 1192 AutoDfgCstAvlFlg2 0 "FALSE" 1 "TRUE" ;
VAL_ 1192 AutoDfgCstAvlFlg1 0 "FALSE" 1 "TRUE" ;
VAL_ 1192 AutoCoolStCstAvlFlg7 0 "FALSE" 1 "TRUE" ;
VAL_ 1192 AutoCoolStCstAvlFlg6 0 "FALSE" 1 "TRUE" ;
VAL_ 1192 AutoCoolStCstAvlFlg5 0 "FALSE" 1 "TRUE" ;
VAL_ 1192 AutoFanCstAvlFlg6 0 "FALSE" 1 "TRUE" ;
VAL_ 1192 AutoFanCstAvlFlg5 0 "FALSE" 1 "TRUE" ;
VAL_ 1192 AutoFanCstAvlFlg4 0 "FALSE" 1 "TRUE" ;
VAL_ 1192 AutoFanCstAvlFlg3 0 "FALSE" 1 "TRUE" ;
VAL_ 1192 AutoFanCstAvlFlg2 0 "FALSE" 1 "TRUE" ;
VAL_ 1192 AutoFanCstAvlFlg1 0 "FALSE" 1 "TRUE" ;
VAL_ 1192 AutoDfgCstAvlFlg7 0 "FALSE" 1 "TRUE" ;
VAL_ 1192 AutoDfgCstAvlFlg6 0 "FALSE" 1 "TRUE" ;
VAL_ 1192 AutoHtdStCstAvlFlg7 0 "FALSE" 1 "TRUE" ;
VAL_ 1192 AutoHtdStCstAvlFlg6 0 "FALSE" 1 "TRUE" ;
VAL_ 1192 AutoHtdStCstAvlFlg5 0 "FALSE" 1 "TRUE" ;
VAL_ 1192 AutoHtdStCstAvlFlg4 0 "FALSE" 1 "TRUE" ;
VAL_ 1192 AutoHtdStCstAvlFlg3 0 "FALSE" 1 "TRUE" ;
VAL_ 1192 AutoHtdStCstAvlFlg2 0 "FALSE" 1 "TRUE" ;
VAL_ 1192 AutoHtdStCstAvlFlg1 0 "FALSE" 1 "TRUE" ;
VAL_ 1192 AutoFanCstAvlFlg7 0 "FALSE" 1 "TRUE" ;
VAL_ 1192 Aux1AmbtColrCtlCstAvlFlg87 0 "FALSE" 1 "TRUE" ;
VAL_ 1192 AutoRrWpCstAvlFlg7 0 "FALSE" 1 "TRUE" ;
VAL_ 1192 AutoRrWpCstAvlFlg6 0 "FALSE" 1 "TRUE" ;
VAL_ 1192 AutoRrWpCstAvlFlg5 0 "FALSE" 1 "TRUE" ;
VAL_ 1192 AutoRrWpCstAvlFlg4 0 "FALSE" 1 "TRUE" ;
VAL_ 1192 AutoRrWpCstAvlFlg3 0 "FALSE" 1 "TRUE" ;
VAL_ 1192 AutoRrWpCstAvlFlg2 0 "FALSE" 1 "TRUE" ;
VAL_ 1192 AutoRrWpCstAvlFlg1 0 "FALSE" 1 "TRUE" ;
VAL_ 1874 Aux1AmbtAnmCtlCstAvlFlg1 0 "FALSE" 1 "TRUE" ;
VAL_ 1874 AutUnlckCstAvlFlg7 0 "FALSE" 1 "TRUE" ;
VAL_ 1874 AutUnlckCstAvlFlg6 0 "FALSE" 1 "TRUE" ;
VAL_ 1874 AutUnlckCstAvlFlg5 0 "FALSE" 1 "TRUE" ;
VAL_ 1874 AutUnlckCstAvlFlg4 0 "FALSE" 1 "TRUE" ;
VAL_ 1874 AutUnlckCstAvlFlg3 0 "FALSE" 1 "TRUE" ;
VAL_ 1874 AutUnlckCstAvlFlg2 0 "FALSE" 1 "TRUE" ;
VAL_ 1874 AutUnlckCstAvlFlg1 0 "FALSE" 1 "TRUE" ;
VAL_ 1874 Aux1AmbtAnmCtlCstAvlFlg3 0 "FALSE" 1 "TRUE" ;
VAL_ 1874 Aux1AmbtAnmCtlCstAvlFlg2 0 "FALSE" 1 "TRUE" ;
VAL_ 1874 Aux1AmbtAnmCtlCstAvlFlg15 0 "FALSE" 1 "TRUE" ;
VAL_ 1874 Aux1AmbtAnmCtlCstAvlFlg14 0 "FALSE" 1 "TRUE" ;
VAL_ 1874 Aux1AmbtAnmCtlCstAvlFlg13 0 "FALSE" 1 "TRUE" ;
VAL_ 1874 Aux1AmbtAnmCtlCstAvlFlg12 0 "FALSE" 1 "TRUE" ;
VAL_ 1874 Aux1AmbtAnmCtlCstAvlFlg11 0 "FALSE" 1 "TRUE" ;
VAL_ 1874 Aux1AmbtAnmCtlCstAvlFlg10 0 "FALSE" 1 "TRUE" ;
VAL_ 1874 Aux1AmbtBrghtnsCtlCstAvlFlg1 0 "FALSE" 1 "TRUE" ;
VAL_ 1874 Aux1AmbtAnmCtlCstSetAval 0 "FALSE" 1 "TRUE" ;
VAL_ 1874 Aux1AmbtAnmCtlCstAvlFlg9 0 "FALSE" 1 "TRUE" ;
VAL_ 1874 Aux1AmbtAnmCtlCstAvlFlg8 0 "FALSE" 1 "TRUE" ;
VAL_ 1874 Aux1AmbtAnmCtlCstAvlFlg7 0 "FALSE" 1 "TRUE" ;
VAL_ 1874 Aux1AmbtAnmCtlCstAvlFlg6 0 "FALSE" 1 "TRUE" ;
VAL_ 1874 Aux1AmbtAnmCtlCstAvlFlg5 0 "FALSE" 1 "TRUE" ;
VAL_ 1874 Aux1AmbtAnmCtlCstAvlFlg4 0 "FALSE" 1 "TRUE" ;
VAL_ 1874 Aux1AmbtColrCtlCstAvlFlg1 0 "FALSE" 1 "TRUE" ;
VAL_ 1874 Aux1AmbtBrghtnsCtlCstSetAval 0 "FALSE" 1 "TRUE" ;
VAL_ 1874 Aux1AmbtBrghtnsCtlCstAvlFlg7 0 "FALSE" 1 "TRUE" ;
VAL_ 1874 Aux1AmbtBrghtnsCtlCstAvlFlg6 0 "FALSE" 1 "TRUE" ;
VAL_ 1874 Aux1AmbtBrghtnsCtlCstAvlFlg5 0 "FALSE" 1 "TRUE" ;
VAL_ 1874 Aux1AmbtBrghtnsCtlCstAvlFlg4 0 "FALSE" 1 "TRUE" ;
VAL_ 1874 Aux1AmbtBrghtnsCtlCstAvlFlg3 0 "FALSE" 1 "TRUE" ;
VAL_ 1874 Aux1AmbtBrghtnsCtlCstAvlFlg2 0 "FALSE" 1 "TRUE" ;
VAL_ 1874 Aux1AmbtColrCtlCstAvlFlg17 0 "FALSE" 1 "TRUE" ;
VAL_ 1874 Aux1AmbtColrCtlCstAvlFlg16 0 "FALSE" 1 "TRUE" ;
VAL_ 1874 Aux1AmbtColrCtlCstAvlFlg15 0 "FALSE" 1 "TRUE" ;
VAL_ 1874 Aux1AmbtColrCtlCstAvlFlg14 0 "FALSE" 1 "TRUE" ;
VAL_ 1874 Aux1AmbtColrCtlCstAvlFlg13 0 "FALSE" 1 "TRUE" ;
VAL_ 1874 Aux1AmbtColrCtlCstAvlFlg12 0 "FALSE" 1 "TRUE" ;
VAL_ 1874 Aux1AmbtColrCtlCstAvlFlg11 0 "FALSE" 1 "TRUE" ;
VAL_ 1874 Aux1AmbtColrCtlCstAvlFlg10 0 "FALSE" 1 "TRUE" ;
VAL_ 1874 Aux1AmbtColrCtlCstAvlFlg24 0 "FALSE" 1 "TRUE" ;
VAL_ 1874 Aux1AmbtColrCtlCstAvlFlg23 0 "FALSE" 1 "TRUE" ;
VAL_ 1874 Aux1AmbtColrCtlCstAvlFlg22 0 "FALSE" 1 "TRUE" ;
VAL_ 1874 Aux1AmbtColrCtlCstAvlFlg21 0 "FALSE" 1 "TRUE" ;
VAL_ 1874 Aux1AmbtColrCtlCstAvlFlg20 0 "FALSE" 1 "TRUE" ;
VAL_ 1874 Aux1AmbtColrCtlCstAvlFlg2 0 "FALSE" 1 "TRUE" ;
VAL_ 1874 Aux1AmbtColrCtlCstAvlFlg19 0 "FALSE" 1 "TRUE" ;
VAL_ 1874 Aux1AmbtColrCtlCstAvlFlg18 0 "FALSE" 1 "TRUE" ;
VAL_ 1874 Aux1AmbtColrCtlCstAvlFlg31 0 "FALSE" 1 "TRUE" ;
VAL_ 1874 Aux1AmbtColrCtlCstAvlFlg30 0 "FALSE" 1 "TRUE" ;
VAL_ 1874 Aux1AmbtColrCtlCstAvlFlg3 0 "FALSE" 1 "TRUE" ;
VAL_ 1874 Aux1AmbtColrCtlCstAvlFlg29 0 "FALSE" 1 "TRUE" ;
VAL_ 1874 Aux1AmbtColrCtlCstAvlFlg28 0 "FALSE" 1 "TRUE" ;
VAL_ 1874 Aux1AmbtColrCtlCstAvlFlg27 0 "FALSE" 1 "TRUE" ;
VAL_ 1874 Aux1AmbtColrCtlCstAvlFlg26 0 "FALSE" 1 "TRUE" ;
VAL_ 1874 Aux1AmbtColrCtlCstAvlFlg25 0 "FALSE" 1 "TRUE" ;
VAL_ 1874 Aux1AmbtColrCtlCstAvlFlg88 0 "FALSE" 1 "TRUE" ;
VAL_ 1874 Aux1AmbtColrCtlCstSetAval 0 "FALSE" 1 "TRUE" ;
VAL_ 1874 Aux1AmbtColrCtlCstAvlFlg9 0 "FALSE" 1 "TRUE" ;
VAL_ 1874 Aux1AmbtColrCtlCstAvlFlg8 0 "FALSE" 1 "TRUE" ;
VAL_ 1874 Aux1AmbtColrCtlCstAvlFlg7 0 "FALSE" 1 "TRUE" ;
VAL_ 1874 Aux1AmbtColrCtlCstAvlFlg6 0 "FALSE" 1 "TRUE" ;
VAL_ 1874 Aux1AmbtColrCtlCstAvlFlg5 0 "FALSE" 1 "TRUE" ;
VAL_ 1874 Aux1AmbtColrCtlCstAvlFlg4 0 "FALSE" 1 "TRUE" ;
VAL_ 1191 HndsFrStrgeAccssCstCfg 0 "Handsfree Kick" 1 "Presence Based Via Phone and Fob" 2 "Presence Based Via Fob" ;
VAL_ 1191 DaytimeTlLghtsCstAvlFlg7 0 "FALSE" 1 "TRUE" ;
VAL_ 1191 DaytimeTlLghtsCstAvlFlg6 0 "FALSE" 1 "TRUE" ;
VAL_ 1191 DaytimeTlLghtsCstAvlFlg5 0 "FALSE" 1 "TRUE" ;
VAL_ 1191 DaytimeTlLghtsCstAvlFlg4 0 "FALSE" 1 "TRUE" ;
VAL_ 1191 DaytimeTlLghtsCstAvlFlg3 0 "FALSE" 1 "TRUE" ;
VAL_ 1191 DaytimeTlLghtsCstAvlFlg2 0 "FALSE" 1 "TRUE" ;
VAL_ 1191 DaytimeTlLghtsCstAvlFlg1 0 "FALSE" 1 "TRUE" ;
VAL_ 1191 HFRCCstAvlFlg1 0 "FALSE" 1 "TRUE" ;
VAL_ 1191 ExtLghtCstAvlFlg7 0 "FALSE" 1 "TRUE" ;
VAL_ 1191 ExtLghtCstAvlFlg6 0 "FALSE" 1 "TRUE" ;
VAL_ 1191 ExtLghtCstAvlFlg5 0 "FALSE" 1 "TRUE" ;
VAL_ 1191 ExtLghtCstAvlFlg4 0 "FALSE" 1 "TRUE" ;
VAL_ 1191 ExtLghtCstAvlFlg3 0 "FALSE" 1 "TRUE" ;
VAL_ 1191 ExtLghtCstAvlFlg2 0 "FALSE" 1 "TRUE" ;
VAL_ 1191 ExtLghtCstAvlFlg1 0 "FALSE" 1 "TRUE" ;
VAL_ 1191 IntrAmbtAnmCtlCstAvlFlg10 0 "FALSE" 1 "TRUE" ;
VAL_ 1191 IntrAmbtAnmCtlCstAvlFlg1 0 "FALSE" 1 "TRUE" ;
VAL_ 1191 HFRCCstAvlFlg7 0 "FALSE" 1 "TRUE" ;
VAL_ 1191 HFRCCstAvlFlg6 0 "FALSE" 1 "TRUE" ;
VAL_ 1191 HFRCCstAvlFlg5 0 "FALSE" 1 "TRUE" ;
VAL_ 1191 HFRCCstAvlFlg4 0 "FALSE" 1 "TRUE" ;
VAL_ 1191 HFRCCstAvlFlg3 0 "FALSE" 1 "TRUE" ;
VAL_ 1191 HFRCCstAvlFlg2 0 "FALSE" 1 "TRUE" ;
VAL_ 1191 IntrAmbtAnmCtlCstAvlFlg4 0 "FALSE" 1 "TRUE" ;
VAL_ 1191 IntrAmbtAnmCtlCstAvlFlg3 0 "FALSE" 1 "TRUE" ;
VAL_ 1191 IntrAmbtAnmCtlCstAvlFlg2 0 "FALSE" 1 "TRUE" ;
VAL_ 1191 IntrAmbtAnmCtlCstAvlFlg15 0 "FALSE" 1 "TRUE" ;
VAL_ 1191 IntrAmbtAnmCtlCstAvlFlg14 0 "FALSE" 1 "TRUE" ;
VAL_ 1191 IntrAmbtAnmCtlCstAvlFlg13 0 "FALSE" 1 "TRUE" ;
VAL_ 1191 IntrAmbtAnmCtlCstAvlFlg12 0 "FALSE" 1 "TRUE" ;
VAL_ 1191 IntrAmbtAnmCtlCstAvlFlg11 0 "FALSE" 1 "TRUE" ;
VAL_ 1191 IntrAmbtBrghtnsCtlCstAvlFlg2 0 "FALSE" 1 "TRUE" ;
VAL_ 1191 IntrAmbtBrghtnsCtlCstAvlFlg1 0 "FALSE" 1 "TRUE" ;
VAL_ 1191 IntrAmbtAnmCtlCstSetAval 0 "FALSE" 1 "TRUE" ;
VAL_ 1191 IntrAmbtAnmCtlCstAvlFlg9 0 "FALSE" 1 "TRUE" ;
VAL_ 1191 IntrAmbtAnmCtlCstAvlFlg8 0 "FALSE" 1 "TRUE" ;
VAL_ 1191 IntrAmbtAnmCtlCstAvlFlg7 0 "FALSE" 1 "TRUE" ;
VAL_ 1191 IntrAmbtAnmCtlCstAvlFlg6 0 "FALSE" 1 "TRUE" ;
VAL_ 1191 IntrAmbtAnmCtlCstAvlFlg5 0 "FALSE" 1 "TRUE" ;
VAL_ 1191 Aux1AmbtColrCtlCstAvlFlg75 0 "FALSE" 1 "TRUE" ;
VAL_ 1191 Aux1AmbtColrCtlCstAvlFlg74 0 "FALSE" 1 "TRUE" ;
VAL_ 1191 IntrAmbtBrghtnsCtlCstSetAval 0 "FALSE" 1 "TRUE" ;
VAL_ 1191 IntrAmbtBrghtnsCtlCstAvlFlg7 0 "FALSE" 1 "TRUE" ;
VAL_ 1191 IntrAmbtBrghtnsCtlCstAvlFlg6 0 "FALSE" 1 "TRUE" ;
VAL_ 1191 IntrAmbtBrghtnsCtlCstAvlFlg5 0 "FALSE" 1 "TRUE" ;
VAL_ 1191 IntrAmbtBrghtnsCtlCstAvlFlg4 0 "FALSE" 1 "TRUE" ;
VAL_ 1191 IntrAmbtBrghtnsCtlCstAvlFlg3 0 "FALSE" 1 "TRUE" ;
VAL_ 1191 Aux1AmbtColrCtlCstAvlFlg83 0 "FALSE" 1 "TRUE" ;
VAL_ 1191 Aux1AmbtColrCtlCstAvlFlg82 0 "FALSE" 1 "TRUE" ;
VAL_ 1191 Aux1AmbtColrCtlCstAvlFlg81 0 "FALSE" 1 "TRUE" ;
VAL_ 1191 Aux1AmbtColrCtlCstAvlFlg80 0 "FALSE" 1 "TRUE" ;
VAL_ 1191 Aux1AmbtColrCtlCstAvlFlg79 0 "FALSE" 1 "TRUE" ;
VAL_ 1191 Aux1AmbtColrCtlCstAvlFlg78 0 "FALSE" 1 "TRUE" ;
VAL_ 1191 Aux1AmbtColrCtlCstAvlFlg77 0 "FALSE" 1 "TRUE" ;
VAL_ 1191 Aux1AmbtColrCtlCstAvlFlg76 0 "FALSE" 1 "TRUE" ;
VAL_ 1875 FTLDI_LFSts 0 "Unknown" 1 "No Leak" 2 "Slow Leak" 3 "Fast Leak" ;
VAL_ 1875 FTLDI_RFSts 0 "Unknown" 1 "No Leak" 2 "Slow Leak" 3 "Fast Leak" ;
VAL_ 1875 IntrAmbtColrCtlCstAvlFlg10 0 "FALSE" 1 "TRUE" ;
VAL_ 1875 IntrAmbtColrCtlCstAvlFlg1 0 "FALSE" 1 "TRUE" ;
VAL_ 1875 IntrAmbtColrCtlCstAvlFlg18 0 "FALSE" 1 "TRUE" ;
VAL_ 1875 IntrAmbtColrCtlCstAvlFlg17 0 "FALSE" 1 "TRUE" ;
VAL_ 1875 IntrAmbtColrCtlCstAvlFlg16 0 "FALSE" 1 "TRUE" ;
VAL_ 1875 IntrAmbtColrCtlCstAvlFlg15 0 "FALSE" 1 "TRUE" ;
VAL_ 1875 IntrAmbtColrCtlCstAvlFlg14 0 "FALSE" 1 "TRUE" ;
VAL_ 1875 IntrAmbtColrCtlCstAvlFlg13 0 "FALSE" 1 "TRUE" ;
VAL_ 1875 IntrAmbtColrCtlCstAvlFlg12 0 "FALSE" 1 "TRUE" ;
VAL_ 1875 IntrAmbtColrCtlCstAvlFlg11 0 "FALSE" 1 "TRUE" ;
VAL_ 1875 IntrAmbtColrCtlCstAvlFlg25 0 "FALSE" 1 "TRUE" ;
VAL_ 1875 IntrAmbtColrCtlCstAvlFlg24 0 "FALSE" 1 "TRUE" ;
VAL_ 1875 IntrAmbtColrCtlCstAvlFlg23 0 "FALSE" 1 "TRUE" ;
VAL_ 1875 IntrAmbtColrCtlCstAvlFlg22 0 "FALSE" 1 "TRUE" ;
VAL_ 1875 IntrAmbtColrCtlCstAvlFlg21 0 "FALSE" 1 "TRUE" ;
VAL_ 1875 IntrAmbtColrCtlCstAvlFlg20 0 "FALSE" 1 "TRUE" ;
VAL_ 1875 IntrAmbtColrCtlCstAvlFlg2 0 "FALSE" 1 "TRUE" ;
VAL_ 1875 IntrAmbtColrCtlCstAvlFlg19 0 "FALSE" 1 "TRUE" ;
VAL_ 1190 IntrAmbtColrCtlCstAvlFlg29 0 "FALSE" 1 "TRUE" ;
VAL_ 1190 IntrAmbtColrCtlCstAvlFlg28 0 "FALSE" 1 "TRUE" ;
VAL_ 1190 IntrAmbtColrCtlCstAvlFlg27 0 "FALSE" 1 "TRUE" ;
VAL_ 1190 IntrAmbtColrCtlCstAvlFlg26 0 "FALSE" 1 "TRUE" ;
VAL_ 1190 IntrAmbtColrCtlCstAvlFlg8 0 "FALSE" 1 "TRUE" ;
VAL_ 1190 IntrAmbtColrCtlCstAvlFlg7 0 "FALSE" 1 "TRUE" ;
VAL_ 1190 IntrAmbtColrCtlCstAvlFlg6 0 "FALSE" 1 "TRUE" ;
VAL_ 1190 IntrAmbtColrCtlCstAvlFlg5 0 "FALSE" 1 "TRUE" ;
VAL_ 1190 IntrAmbtColrCtlCstAvlFlg4 0 "FALSE" 1 "TRUE" ;
VAL_ 1190 IntrAmbtColrCtlCstAvlFlg31 0 "FALSE" 1 "TRUE" ;
VAL_ 1190 IntrAmbtColrCtlCstAvlFlg30 0 "FALSE" 1 "TRUE" ;
VAL_ 1190 IntrAmbtColrCtlCstAvlFlg3 0 "FALSE" 1 "TRUE" ;
VAL_ 1190 IonzrCtrlCstAvlFlg6 0 "FALSE" 1 "TRUE" ;
VAL_ 1190 IonzrCtrlCstAvlFlg5 0 "FALSE" 1 "TRUE" ;
VAL_ 1190 IonzrCtrlCstAvlFlg4 0 "FALSE" 1 "TRUE" ;
VAL_ 1190 IonzrCtrlCstAvlFlg3 0 "FALSE" 1 "TRUE" ;
VAL_ 1190 IonzrCtrlCstAvlFlg2 0 "FALSE" 1 "TRUE" ;
VAL_ 1190 IonzrCtrlCstAvlFlg1 0 "FALSE" 1 "TRUE" ;
VAL_ 1190 IntrAmbtColrCtlCstSetAval 0 "FALSE" 1 "TRUE" ;
VAL_ 1190 IntrAmbtColrCtlCstAvlFlg9 0 "FALSE" 1 "TRUE" ;
VAL_ 1190 LDCLCstAvlFlg7 0 "FALSE" 1 "TRUE" ;
VAL_ 1190 LDCLCstAvlFlg6 0 "FALSE" 1 "TRUE" ;
VAL_ 1190 LDCLCstAvlFlg5 0 "FALSE" 1 "TRUE" ;
VAL_ 1190 LDCLCstAvlFlg4 0 "FALSE" 1 "TRUE" ;
VAL_ 1190 LDCLCstAvlFlg3 0 "FALSE" 1 "TRUE" ;
VAL_ 1190 LDCLCstAvlFlg2 0 "FALSE" 1 "TRUE" ;
VAL_ 1190 LDCLCstAvlFlg1 0 "FALSE" 1 "TRUE" ;
VAL_ 1190 IonzrCtrlCstAvlFlg7 0 "FALSE" 1 "TRUE" ;
VAL_ 1190 Aux1AmbtColrCtlCstAvlFlg89 0 "FALSE" 1 "TRUE" ;
VAL_ 1190 OpDrAtLOCstAvlFlg7 0 "FALSE" 1 "TRUE" ;
VAL_ 1190 OpDrAtLOCstAvlFlg6 0 "FALSE" 1 "TRUE" ;
VAL_ 1190 OpDrAtLOCstAvlFlg5 0 "FALSE" 1 "TRUE" ;
VAL_ 1190 OpDrAtLOCstAvlFlg4 0 "FALSE" 1 "TRUE" ;
VAL_ 1190 OpDrAtLOCstAvlFlg3 0 "FALSE" 1 "TRUE" ;
VAL_ 1190 OpDrAtLOCstAvlFlg2 0 "FALSE" 1 "TRUE" ;
VAL_ 1190 OpDrAtLOCstAvlFlg1 0 "FALSE" 1 "TRUE" ;
VAL_ 1876 PsvUnlckCstAvlFlg1 0 "FALSE" 1 "TRUE" ;
VAL_ 1876 PlltnCtrlCstAvlFlg7 0 "FALSE" 1 "TRUE" ;
VAL_ 1876 PlltnCtrlCstAvlFlg6 0 "FALSE" 1 "TRUE" ;
VAL_ 1876 PlltnCtrlCstAvlFlg5 0 "FALSE" 1 "TRUE" ;
VAL_ 1876 PlltnCtrlCstAvlFlg4 0 "FALSE" 1 "TRUE" ;
VAL_ 1876 PlltnCtrlCstAvlFlg3 0 "FALSE" 1 "TRUE" ;
VAL_ 1876 PlltnCtrlCstAvlFlg2 0 "FALSE" 1 "TRUE" ;
VAL_ 1876 PlltnCtrlCstAvlFlg1 0 "FALSE" 1 "TRUE" ;
VAL_ 1876 RemInVehRmndrCstAvlFlg2 0 "FALSE" 1 "TRUE" ;
VAL_ 1876 RemInVehRmndrCstAvlFlg1 0 "FALSE" 1 "TRUE" ;
VAL_ 1876 PsvUnlckCstAvlFlg7 0 "FALSE" 1 "TRUE" ;
VAL_ 1876 PsvUnlckCstAvlFlg6 0 "FALSE" 1 "TRUE" ;
VAL_ 1876 PsvUnlckCstAvlFlg5 0 "FALSE" 1 "TRUE" ;
VAL_ 1876 PsvUnlckCstAvlFlg4 0 "FALSE" 1 "TRUE" ;
VAL_ 1876 PsvUnlckCstAvlFlg3 0 "FALSE" 1 "TRUE" ;
VAL_ 1876 PsvUnlckCstAvlFlg2 0 "FALSE" 1 "TRUE" ;
VAL_ 1876 RemLftVehRmndrCstAvlFlg3 0 "FALSE" 1 "TRUE" ;
VAL_ 1876 RemLftVehRmndrCstAvlFlg2 0 "FALSE" 1 "TRUE" ;
VAL_ 1876 RemLftVehRmndrCstAvlFlg1 0 "FALSE" 1 "TRUE" ;
VAL_ 1876 RemInVehRmndrCstAvlFlg7 0 "FALSE" 1 "TRUE" ;
VAL_ 1876 RemInVehRmndrCstAvlFlg6 0 "FALSE" 1 "TRUE" ;
VAL_ 1876 RemInVehRmndrCstAvlFlg5 0 "FALSE" 1 "TRUE" ;
VAL_ 1876 RemInVehRmndrCstAvlFlg4 0 "FALSE" 1 "TRUE" ;
VAL_ 1876 RemInVehRmndrCstAvlFlg3 0 "FALSE" 1 "TRUE" ;
VAL_ 1876 RevTltMirCstAvlFlg4 0 "FALSE" 1 "TRUE" ;
VAL_ 1876 RevTltMirCstAvlFlg3 0 "FALSE" 1 "TRUE" ;
VAL_ 1876 RevTltMirCstAvlFlg2 0 "FALSE" 1 "TRUE" ;
VAL_ 1876 RevTltMirCstAvlFlg1 0 "FALSE" 1 "TRUE" ;
VAL_ 1876 RemLftVehRmndrCstAvlFlg7 0 "FALSE" 1 "TRUE" ;
VAL_ 1876 RemLftVehRmndrCstAvlFlg6 0 "FALSE" 1 "TRUE" ;
VAL_ 1876 RemLftVehRmndrCstAvlFlg5 0 "FALSE" 1 "TRUE" ;
VAL_ 1876 RemLftVehRmndrCstAvlFlg4 0 "FALSE" 1 "TRUE" ;
VAL_ 1876 RlkRtUlkDrCstAvlFlg5 0 "FALSE" 1 "TRUE" ;
VAL_ 1876 RlkRtUlkDrCstAvlFlg4 0 "FALSE" 1 "TRUE" ;
VAL_ 1876 RlkRtUlkDrCstAvlFlg3 0 "FALSE" 1 "TRUE" ;
VAL_ 1876 RlkRtUlkDrCstAvlFlg2 0 "FALSE" 1 "TRUE" ;
VAL_ 1876 RlkRtUlkDrCstAvlFlg1 0 "FALSE" 1 "TRUE" ;
VAL_ 1876 RevTltMirCstAvlFlg7 0 "FALSE" 1 "TRUE" ;
VAL_ 1876 RevTltMirCstAvlFlg6 0 "FALSE" 1 "TRUE" ;
VAL_ 1876 RevTltMirCstAvlFlg5 0 "FALSE" 1 "TRUE" ;
VAL_ 1876 RmtSnrfOpCstAvlFlg6 0 "FALSE" 1 "TRUE" ;
VAL_ 1876 RmtSnrfOpCstAvlFlg5 0 "FALSE" 1 "TRUE" ;
VAL_ 1876 RmtSnrfOpCstAvlFlg4 0 "FALSE" 1 "TRUE" ;
VAL_ 1876 RmtSnrfOpCstAvlFlg3 0 "FALSE" 1 "TRUE" ;
VAL_ 1876 RmtSnrfOpCstAvlFlg2 0 "FALSE" 1 "TRUE" ;
VAL_ 1876 RmtSnrfOpCstAvlFlg1 0 "FALSE" 1 "TRUE" ;
VAL_ 1876 RlkRtUlkDrCstAvlFlg7 0 "FALSE" 1 "TRUE" ;
VAL_ 1876 RlkRtUlkDrCstAvlFlg6 0 "FALSE" 1 "TRUE" ;
VAL_ 1876 RmtStrtCoolStCstAvlFlg7 0 "FALSE" 1 "TRUE" ;
VAL_ 1876 RmtStrtCoolStCstAvlFlg6 0 "FALSE" 1 "TRUE" ;
VAL_ 1876 RmtStrtCoolStCstAvlFlg5 0 "FALSE" 1 "TRUE" ;
VAL_ 1876 RmtStrtCoolStCstAvlFlg4 0 "FALSE" 1 "TRUE" ;
VAL_ 1876 RmtStrtCoolStCstAvlFlg3 0 "FALSE" 1 "TRUE" ;
VAL_ 1876 RmtStrtCoolStCstAvlFlg2 0 "FALSE" 1 "TRUE" ;
VAL_ 1876 RmtStrtCoolStCstAvlFlg1 0 "FALSE" 1 "TRUE" ;
VAL_ 1876 RmtSnrfOpCstAvlFlg7 0 "FALSE" 1 "TRUE" ;
VAL_ 1876 Aux1AmbtColrCtlCstAvlFlg90 0 "FALSE" 1 "TRUE" ;
VAL_ 1876 RmtStrtHtdStCstAvlFlg7 0 "FALSE" 1 "TRUE" ;
VAL_ 1876 RmtStrtHtdStCstAvlFlg6 0 "FALSE" 1 "TRUE" ;
VAL_ 1876 RmtStrtHtdStCstAvlFlg5 0 "FALSE" 1 "TRUE" ;
VAL_ 1876 RmtStrtHtdStCstAvlFlg4 0 "FALSE" 1 "TRUE" ;
VAL_ 1876 RmtStrtHtdStCstAvlFlg3 0 "FALSE" 1 "TRUE" ;
VAL_ 1876 RmtStrtHtdStCstAvlFlg2 0 "FALSE" 1 "TRUE" ;
VAL_ 1876 RmtStrtHtdStCstAvlFlg1 0 "FALSE" 1 "TRUE" ;
VAL_ 1189 RnSnsCstAvlFlg1 0 "FALSE" 1 "TRUE" ;
VAL_ 1189 RmtWndOpCstAvlFlg7 0 "FALSE" 1 "TRUE" ;
VAL_ 1189 RmtWndOpCstAvlFlg6 0 "FALSE" 1 "TRUE" ;
VAL_ 1189 RmtWndOpCstAvlFlg5 0 "FALSE" 1 "TRUE" ;
VAL_ 1189 RmtWndOpCstAvlFlg4 0 "FALSE" 1 "TRUE" ;
VAL_ 1189 RmtWndOpCstAvlFlg3 0 "FALSE" 1 "TRUE" ;
VAL_ 1189 RmtWndOpCstAvlFlg2 0 "FALSE" 1 "TRUE" ;
VAL_ 1189 RmtWndOpCstAvlFlg1 0 "FALSE" 1 "TRUE" ;
VAL_ 1189 RrDfgStUpCstAvlFlg2 0 "FALSE" 1 "TRUE" ;
VAL_ 1189 RrDfgStUpCstAvlFlg1 0 "FALSE" 1 "TRUE" ;
VAL_ 1189 RnSnsCstAvlFlg7 0 "FALSE" 1 "TRUE" ;
VAL_ 1189 RnSnsCstAvlFlg6 0 "FALSE" 1 "TRUE" ;
VAL_ 1189 RnSnsCstAvlFlg5 0 "FALSE" 1 "TRUE" ;
VAL_ 1189 RnSnsCstAvlFlg4 0 "FALSE" 1 "TRUE" ;
VAL_ 1189 RnSnsCstAvlFlg3 0 "FALSE" 1 "TRUE" ;
VAL_ 1189 RnSnsCstAvlFlg2 0 "FALSE" 1 "TRUE" ;
VAL_ 1189 RrStRmndrEnblDsblCstAvlFlg3 0 "FALSE" 1 "TRUE" ;
VAL_ 1189 RrStRmndrEnblDsblCstAvlFlg2 0 "FALSE" 1 "TRUE" ;
VAL_ 1189 RrStRmndrEnblDsblCstAvlFlg1 0 "FALSE" 1 "TRUE" ;
VAL_ 1189 RrDfgStUpCstAvlFlg7 0 "FALSE" 1 "TRUE" ;
VAL_ 1189 RrDfgStUpCstAvlFlg6 0 "FALSE" 1 "TRUE" ;
VAL_ 1189 RrDfgStUpCstAvlFlg5 0 "FALSE" 1 "TRUE" ;
VAL_ 1189 RrDfgStUpCstAvlFlg4 0 "FALSE" 1 "TRUE" ;
VAL_ 1189 RrDfgStUpCstAvlFlg3 0 "FALSE" 1 "TRUE" ;
VAL_ 1189 RrZnStUpCstAvlFlg4 0 "FALSE" 1 "TRUE" ;
VAL_ 1189 RrZnStUpCstAvlFlg3 0 "FALSE" 1 "TRUE" ;
VAL_ 1189 RrZnStUpCstAvlFlg2 0 "FALSE" 1 "TRUE" ;
VAL_ 1189 RrZnStUpCstAvlFlg1 0 "FALSE" 1 "TRUE" ;
VAL_ 1189 RrStRmndrEnblDsblCstAvlFlg7 0 "FALSE" 1 "TRUE" ;
VAL_ 1189 RrStRmndrEnblDsblCstAvlFlg6 0 "FALSE" 1 "TRUE" ;
VAL_ 1189 RrStRmndrEnblDsblCstAvlFlg5 0 "FALSE" 1 "TRUE" ;
VAL_ 1189 RrStRmndrEnblDsblCstAvlFlg4 0 "FALSE" 1 "TRUE" ;
VAL_ 1189 RtLkFdbkCstAvlFlg5 0 "FALSE" 1 "TRUE" ;
VAL_ 1189 RtLkFdbkCstAvlFlg4 0 "FALSE" 1 "TRUE" ;
VAL_ 1189 RtLkFdbkCstAvlFlg3 0 "FALSE" 1 "TRUE" ;
VAL_ 1189 RtLkFdbkCstAvlFlg2 0 "FALSE" 1 "TRUE" ;
VAL_ 1189 RtLkFdbkCstAvlFlg1 0 "FALSE" 1 "TRUE" ;
VAL_ 1189 RrZnStUpCstAvlFlg7 0 "FALSE" 1 "TRUE" ;
VAL_ 1189 RrZnStUpCstAvlFlg6 0 "FALSE" 1 "TRUE" ;
VAL_ 1189 RrZnStUpCstAvlFlg5 0 "FALSE" 1 "TRUE" ;
VAL_ 1189 RtUlkLtFbCstAvlFlg6 0 "FALSE" 1 "TRUE" ;
VAL_ 1189 RtUlkLtFbCstAvlFlg5 0 "FALSE" 1 "TRUE" ;
VAL_ 1189 RtUlkLtFbCstAvlFlg4 0 "FALSE" 1 "TRUE" ;
VAL_ 1189 RtUlkLtFbCstAvlFlg3 0 "FALSE" 1 "TRUE" ;
VAL_ 1189 RtUlkLtFbCstAvlFlg2 0 "FALSE" 1 "TRUE" ;
VAL_ 1189 RtUlkLtFbCstAvlFlg1 0 "FALSE" 1 "TRUE" ;
VAL_ 1189 RtLkFdbkCstAvlFlg7 0 "FALSE" 1 "TRUE" ;
VAL_ 1189 RtLkFdbkCstAvlFlg6 0 "FALSE" 1 "TRUE" ;
VAL_ 1189 SelUlkCstAvlFlg7 0 "FALSE" 1 "TRUE" ;
VAL_ 1189 SelUlkCstAvlFlg6 0 "FALSE" 1 "TRUE" ;
VAL_ 1189 SelUlkCstAvlFlg5 0 "FALSE" 1 "TRUE" ;
VAL_ 1189 SelUlkCstAvlFlg4 0 "FALSE" 1 "TRUE" ;
VAL_ 1189 SelUlkCstAvlFlg3 0 "FALSE" 1 "TRUE" ;
VAL_ 1189 SelUlkCstAvlFlg2 0 "FALSE" 1 "TRUE" ;
VAL_ 1189 SelUlkCstAvlFlg1 0 "FALSE" 1 "TRUE" ;
VAL_ 1189 RtUlkLtFbCstAvlFlg7 0 "FALSE" 1 "TRUE" ;
VAL_ 1189 Aux1AmbtColrCtlCstAvlFlg92 0 "FALSE" 1 "TRUE" ;
VAL_ 1189 Aux1AmbtColrCtlCstAvlFlg91 0 "FALSE" 1 "TRUE" ;
VAL_ 1189 TnDrvOvSpdWrnCstAvlFlg6 0 "FALSE" 1 "TRUE" ;
VAL_ 1189 TnDrvOvSpdWrnCstAvlFlg5 0 "FALSE" 1 "TRUE" ;
VAL_ 1189 TnDrvOvSpdWrnCstAvlFlg4 0 "FALSE" 1 "TRUE" ;
VAL_ 1189 TnDrvOvSpdWrnCstAvlFlg3 0 "FALSE" 1 "TRUE" ;
VAL_ 1189 TnDrvOvSpdWrnCstAvlFlg2 0 "FALSE" 1 "TRUE" ;
VAL_ 1189 TnDrvOvSpdWrnCstAvlFlg1 0 "FALSE" 1 "TRUE" ;
VAL_ 1877 RTLDI_LRSts 0 "Unknown" 1 "No Leak" 2 "Slow Leak" 3 "Fast Leak" ;
VAL_ 1877 RTLDI_RRSts 0 "Unknown" 1 "No Leak" 2 "Slow Leak" 3 "Fast Leak" ;
VAL_ 1877 TrlrProfSeltnResp 0 "No Action" 1 "Default Profile" 2 "Profile1" 3 "Profile2" 4 "Profile3" 5 "Profile4" 6 "Profile5" 7 "Profile6" 8 "Profile7" 9 "Profile8" 10 "Profile9" 11 "Profile10" 12 "Profile11" 13 "Profile12" 14 "Profile13" 15 "Profile14" 16 "Profile15" 17 "Profile16" 18 "Profile17" 19 "Profile18" 20 "Profile19" 21 "Profile20" ;
VAL_ 1877 TrlrTireLFPresSts 0 "Unknown" 1 "Normal" 2 "Low Pressure" 3 "Malfunction" 4 "Learning in Progress" 5 "Learn Tire" 6 "Tire Learning Complete" 7 "High Pressure" 8 "High Temperature" ;
VAL_ 1877 TrlrTireLFPresSts_Inv 0 "FALSE" 1 "TRUE" ;
VAL_ 1877 TnDrvSpdLmtCstAvlFlg7 0 "FALSE" 1 "TRUE" ;
VAL_ 1877 TnDrvSpdLmtCstAvlFlg6 0 "FALSE" 1 "TRUE" ;
VAL_ 1877 TnDrvSpdLmtCstAvlFlg5 0 "FALSE" 1 "TRUE" ;
VAL_ 1877 TnDrvSpdLmtCstAvlFlg4 0 "FALSE" 1 "TRUE" ;
VAL_ 1877 TnDrvSpdLmtCstAvlFlg3 0 "FALSE" 1 "TRUE" ;
VAL_ 1877 TnDrvSpdLmtCstAvlFlg2 0 "FALSE" 1 "TRUE" ;
VAL_ 1877 TnDrvSpdLmtCstAvlFlg1 0 "FALSE" 1 "TRUE" ;
VAL_ 1877 TnDrvOvSpdWrnCstAvlFlg7 0 "FALSE" 1 "TRUE" ;
VAL_ 1878 TLDWCI_Sts 0 "Unknown" 1 "No Leak" 2 "Slow Leak" 3 "Fast Leak" ;
VAL_ 1878 TrlrTireLFPres_Inv 0 "FALSE" 1 "TRUE" ;
VAL_ 1879 TrlrTireLRPres_Inv 0 "FALSE" 1 "TRUE" ;
VAL_ 1879 TrlrTireLFTemp_Inv 0 "FALSE" 1 "TRUE" ;
VAL_ 1879 TrlrTireLtMdlPresSts 0 "Unknown" 1 "Normal" 2 "Low Pressure" 3 "Malfunction" 4 "Learning in Progress" 5 "Learn Tire" 6 "Tire Learning Complete" 7 "High Pressure" 8 "High Temperature" ;
VAL_ 1879 TrlrTireLtMdlPresSts_Inv 0 "FALSE" 1 "TRUE" ;
VAL_ 1879 TrlrTireLRPresSts 0 "Unknown" 1 "Normal" 2 "Low Pressure" 3 "Malfunction" 4 "Learning in Progress" 5 "Learn Tire" 6 "Tire Learning Complete" 7 "High Pressure" 8 "High Temperature" ;
VAL_ 1879 TrlrTireLRPresSts_Inv 0 "FALSE" 1 "TRUE" ;
VAL_ 1879 Aux1AmbtColrCtlCstAvlFlg94 0 "FALSE" 1 "TRUE" ;
VAL_ 1879 Aux1AmbtColrCtlCstAvlFlg93 0 "FALSE" 1 "TRUE" ;
VAL_ 1879 TrlrTireLrnSts 0 "Unknown" 1 "Learn Completed" 2 "Learn Progressing" 3 "Learn Failed" 4 "Tires not Learned" ;
